VERSION "eCMP INFO-DIV vehicle review 2026-11-03; 125000 bit/s; PSA-RE 67f7581e7622410efdbb29c7eda3b86982b9b450; Apache-2.0"

NS_ :

BS_:

BU_: AAS AMPLI AVP BCM BGP BSG BSI BTA BTEL BTT CDC CMB CRT DIAG_TOOL EDP_C EMF FMUX IC ICSV IDVR IVC_D MATT MDS OVIP PDS_C RAD RBG SDCM VTH WLC

BO_ 603 BTEL_ClimatePrecondSched: 7 BTEL
 SG_ ClimatePrecondSlot2StartTime : 42|11@0+ (1,0) [0|1440] "min"  BSI
 SG_ Unused3 : 47|5@0+ (1,0) [0|31] ""  BSI
 SG_ ClimatePrecondSundaySlot2Enabled : 32|1@0+ (1,0) [0|1] ""  BSI
 SG_ ClimatePrecondSaturdaySlo_fd2bfe : 33|1@0+ (1,0) [0|1] ""  BSI
 SG_ ClimatePrecondFridaySlot2Enabled : 34|1@0+ (1,0) [0|1] ""  BSI
 SG_ ClimatePrecondThursdaySlo_8ba9ec : 35|1@0+ (1,0) [0|1] ""  BSI
 SG_ ClimatePrecondWednesdaySl_20214f : 36|1@0+ (1,0) [0|1] ""  BSI
 SG_ ClimatePrecondTuesdaySlot_413385 : 37|1@0+ (1,0) [0|1] ""  BSI
 SG_ ClimatePrecondMondaySlot2Enabled : 38|1@0+ (1,0) [0|1] ""  BSI
 SG_ ClimatePrecondSlot2Enabled : 39|1@0+ (1,0) [0|1] ""  BSI
 SG_ ClimatePrecondSlot1StartTime : 18|11@0+ (1,0) [0|1440] "min"  BSI
 SG_ Unused2 : 23|5@0+ (1,0) [0|31] ""  BSI
 SG_ ClimatePrecondSundaySlot1Enabled : 8|1@0+ (1,0) [0|1] ""  BSI
 SG_ ClimatePrecondSaturdaySlo_c187b9 : 9|1@0+ (1,0) [0|1] ""  BSI
 SG_ ClimatePrecondFridaySlot1Enabled : 10|1@0+ (1,0) [0|1] ""  BSI
 SG_ ClimatePrecondThursdaySlo_13efd6 : 11|1@0+ (1,0) [0|1] ""  BSI
 SG_ ClimatePrecondWednesdaySl_d65ca4 : 12|1@0+ (1,0) [0|1] ""  BSI
 SG_ ClimatePrecondTuesdaySlot_1bddd8 : 13|1@0+ (1,0) [0|1] ""  BSI
 SG_ ClimatePrecondMondaySlot1Enabled : 14|1@0+ (1,0) [0|1] ""  BSI
 SG_ ClimatePrecondSlot1Enabled : 15|1@0+ (1,0) [0|1] ""  BSI
 SG_ Unused1 : 6|7@0+ (1,0) [0|127] ""  BSI
 SG_ ClimatePrecondMenuAvailability : 7|1@0+ (1,0) [0|1] ""  BSI

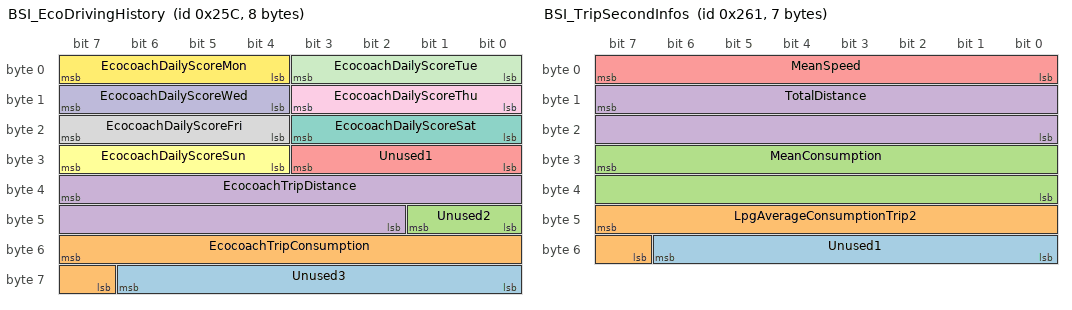
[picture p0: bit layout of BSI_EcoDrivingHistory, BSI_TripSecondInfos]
BO_ 604 BSI_EcoDrivingHistory: 8 BSI
 SG_ Unused3 : 62|7@0+ (1,0) [0|127] ""  OVIP,BTEL
 SG_ EcocoachTripConsumption : 55|9@0+ (0.1,0) [0|30] "L"  OVIP,BTEL
 SG_ Unused2 : 41|2@0+ (1,0) [0|3] ""  OVIP,BTEL
 SG_ EcocoachTripDistance : 39|14@0+ (1,0) [0|16383] "km"  OVIP,BTEL
 SG_ Unused1 : 27|4@0+ (1,0) [0|15] ""  OVIP,BTEL
 SG_ EcocoachDailyScoreSun : 31|4@0+ (1,0) [0|10] ""  OVIP,BTEL
 SG_ EcocoachDailyScoreSat : 19|4@0+ (1,0) [0|10] ""  OVIP,BTEL
 SG_ EcocoachDailyScoreFri : 23|4@0+ (1,0) [0|10] ""  OVIP,BTEL
 SG_ EcocoachDailyScoreThu : 11|4@0+ (1,0) [0|10] ""  OVIP,BTEL
 SG_ EcocoachDailyScoreWed : 15|4@0+ (1,0) [0|10] ""  OVIP,BTEL
 SG_ EcocoachDailyScoreTue : 3|4@0+ (1,0) [0|10] ""  OVIP,BTEL
 SG_ EcocoachDailyScoreMon : 7|4@0+ (1,0) [0|10] ""  OVIP,BTEL

BO_ 607 EMF_KmlReplyFlowControl: 8 EMF
 SG_ FlowPadding5 m3 : 63|8@0+ (1,0) [0|255] "raw"  RAD
 SG_ FirstData6 m1 : 63|8@0+ (1,0) [0|255] "raw"  RAD
 SG_ UnknownData7 m4 : 63|8@0+ (1,0) [0|255] "raw"  RAD
 SG_ ConsecutiveData7 m2 : 63|8@0+ (1,0) [0|255] "raw"  RAD
 SG_ SingleData7 m0 : 63|8@0+ (1,0) [0|255] "raw"  RAD
 SG_ FlowPadding4 m3 : 55|8@0+ (1,0) [0|255] "raw"  RAD
 SG_ FirstData5 m1 : 55|8@0+ (1,0) [0|255] "raw"  RAD
 SG_ UnknownData6 m4 : 55|8@0+ (1,0) [0|255] "raw"  RAD
 SG_ ConsecutiveData6 m2 : 55|8@0+ (1,0) [0|255] "raw"  RAD
 SG_ SingleData6 m0 : 55|8@0+ (1,0) [0|255] "raw"  RAD
 SG_ FlowPadding3 m3 : 47|8@0+ (1,0) [0|255] "raw"  RAD
 SG_ FirstData4 m1 : 47|8@0+ (1,0) [0|255] "raw"  RAD
 SG_ UnknownData5 m4 : 47|8@0+ (1,0) [0|255] "raw"  RAD
 SG_ ConsecutiveData5 m2 : 47|8@0+ (1,0) [0|255] "raw"  RAD
 SG_ SingleData5 m0 : 47|8@0+ (1,0) [0|255] "raw"  RAD
 SG_ FlowPadding2 m3 : 39|8@0+ (1,0) [0|255] "raw"  RAD
 SG_ FirstData3 m1 : 39|8@0+ (1,0) [0|255] "raw"  RAD
 SG_ UnknownData4 m4 : 39|8@0+ (1,0) [0|255] "raw"  RAD
 SG_ ConsecutiveData4 m2 : 39|8@0+ (1,0) [0|255] "raw"  RAD
 SG_ SingleData4 m0 : 39|8@0+ (1,0) [0|255] "raw"  RAD
 SG_ FlowPadding1 m3 : 31|8@0+ (1,0) [0|255] "raw"  RAD
 SG_ FirstData2 m1 : 31|8@0+ (1,0) [0|255] "raw"  RAD
 SG_ UnknownData3 m4 : 31|8@0+ (1,0) [0|255] "raw"  RAD
 SG_ ConsecutiveData3 m2 : 31|8@0+ (1,0) [0|255] "raw"  RAD
 SG_ SingleData3 m0 : 31|8@0+ (1,0) [0|255] "raw"  RAD
 SG_ FirstData1 m1 : 23|8@0+ (1,0) [0|255] "raw"  RAD
 SG_ UnknownData2 m4 : 23|8@0+ (1,0) [0|255] "raw"  RAD
 SG_ ConsecutiveData2 m2 : 23|8@0+ (1,0) [0|255] "raw"  RAD
 SG_ SingleData2 m0 : 23|8@0+ (1,0) [0|255] "raw"  RAD
 SG_ SeparationTimeRaw m3 : 23|8@0+ (1,0) [0|255] "raw"  RAD
 SG_ UnknownData1 m4 : 15|8@0+ (1,0) [0|255] "raw"  RAD
 SG_ ConsecutiveData1 m2 : 15|8@0+ (1,0) [0|255] "raw"  RAD
 SG_ SingleData1 m0 : 15|8@0+ (1,0) [0|255] "raw"  RAD
 SG_ BlockSize m3 : 15|8@0+ (1,0) [0|255] "raw"  RAD
 SG_ UnknownPciLow m4 : 3|4@0+ (1,0) [0|15] "raw"  RAD
 SG_ FlowStatus m3 : 3|4@0+ (1,0) [0|15] "raw"  RAD
 SG_ ConsecutiveSequence m2 : 3|4@0+ (1,0) [0|15] "raw"  RAD
 SG_ FirstFrameLength m1 : 3|12@0+ (1,0) [0|4095] "raw"  RAD
 SG_ SingleFrameLength m0 : 3|4@0+ (1,0) [0|15] "raw"  RAD
 SG_ IsoTpFrameType M : 7|4@0+ (1,0) [0|15] ""  RAD

BO_ 608 BSI_VehiclePersonalizatio_19d41f: 8 BSI
 SG_ AmlaItemStatus : 56|1@0+ (1,0) [0|1] ""  IDVR,EMF,BTEL,MATT,MDS,CMB,VTH,RAD,ICSV,BGP,FMUX,OVIP
 SG_ AfsFunctionActive : 57|1@0+ (1,0) [0|1] ""  IDVR,EMF,BTEL,MATT,MDS,CMB,VTH,RAD,ICSV,BGP,FMUX,OVIP
 SG_ ArsFunctionActive : 58|1@0+ (1,0) [0|1] ""  IDVR,EMF,BTEL,MATT,MDS,CMB,VTH,RAD,ICSV,BGP,FMUX,OVIP
 SG_ IrvFunctionInhibited : 59|1@0+ (1,0) [0|1] ""  IDVR,EMF,BTEL,MATT,MDS,CMB,VTH,RAD,ICSV,BGP,FMUX,OVIP
 SG_ Dae4wdItemModeStatus : 61|2@0+ (1,0) [0|3] ""  IDVR,EMF,BTEL,MATT,MDS,CMB,VTH,RAD,ICSV,BGP,FMUX,OVIP
 SG_ DaeItemModeStatus : 63|2@0+ (1,0) [0|3] ""  IDVR,EMF,BTEL,MATT,MDS,CMB,VTH,RAD,ICSV,BGP,FMUX,OVIP
 SG_ LoadedArmsAccessFunctionActive : 48|1@0+ (1,0) [0|1] ""  IDVR,EMF,BTEL,MATT,MDS,CMB,VTH,RAD,ICSV,BGP,FMUX,OVIP
 SG_ IlvItemStatus : 49|1@0+ (1,0) [0|1] ""  IDVR,EMF,BTEL,MATT,MDS,CMB,VTH,RAD,ICSV,BGP,FMUX,OVIP
 SG_ GrilleLightingFunctionStatus : 50|1@0+ (1,0) [0|1] ""  IDVR,EMF,BTEL,MATT,MDS,CMB,VTH,RAD,ICSV,BGP,FMUX,OVIP
 SG_ CafrItemStatus : 51|1@0+ (1,0) [0|1] ""  IDVR,EMF,BTEL,MATT,MDS,CMB,VTH,RAD,ICSV,BGP,FMUX,OVIP
 SG_ DriverAlertAssistFunctionActive : 52|1@0+ (1,0) [0|1] ""  IDVR,EMF,BTEL,MATT,MDS,CMB,VTH,RAD,ICSV,BGP,FMUX,OVIP
 SG_ LoadedArmsLockFunctionActive : 53|1@0+ (1,0) [0|1] ""  IDVR,EMF,BTEL,MATT,MDS,CMB,VTH,RAD,ICSV,BGP,FMUX,OVIP
 SG_ EtsrFunctionActive : 54|1@0+ (1,0) [0|1] ""  IDVR,EMF,BTEL,MATT,MDS,CMB,VTH,RAD,ICSV,BGP,FMUX,OVIP
 SG_ EcsModeFunctionActive : 55|1@0+ (1,0) [0|1] ""  IDVR,EMF,BTEL,MATT,MDS,CMB,VTH,RAD,ICSV,BGP,FMUX,OVIP
 SG_ ActiveUserProfile : 41|2@0+ (1,0) [0|3] ""  IDVR,EMF,BTEL,MATT,MDS,CMB,VTH,RAD,ICSV,BGP,FMUX,OVIP
 SG_ ReverseIndexingStatus : 42|1@0+ (1,0) [0|1] ""  IDVR,EMF,BTEL,MATT,MDS,CMB,VTH,RAD,ICSV,BGP,FMUX,OVIP
 SG_ TpmsReinitializationStatus : 43|1@0+ (1,0) [0|1] ""  IDVR,EMF,BTEL,MATT,MDS,CMB,VTH,RAD,ICSV,BGP,FMUX,OVIP
 SG_ CollisionRiskBrakingType : 44|1@0+ (1,0) [0|1] ""  IDVR,EMF,BTEL,MATT,MDS,CMB,VTH,RAD,ICSV,BGP,FMUX,OVIP
 SG_ ArcSensitivityLevel : 46|2@0+ (1,0) [0|3] ""  IDVR,EMF,BTEL,MATT,MDS,CMB,VTH,RAD,ICSV,BGP,FMUX,OVIP
 SG_ ArcFunctionActive : 47|1@0+ (1,0) [0|1] ""  IDVR,EMF,BTEL,MATT,MDS,CMB,VTH,RAD,ICSV,BGP,FMUX,OVIP
 SG_ ConfigurableButtonFunction : 35|4@0+ (1,0) [0|15] ""  IDVR,EMF,BTEL,MATT,MDS,CMB,VTH,RAD,ICSV,BGP,FMUX,OVIP
 SG_ RearFlapMotorizationFunct_177f8c : 36|1@0+ (1,0) [0|1] ""  IDVR,EMF,BTEL,MATT,MDS,CMB,VTH,RAD,ICSV,BGP,FMUX,OVIP
 SG_ AutomaticRearWiperInReverse : 37|1@0+ (1,0) [0|1] ""  IDVR,EMF,BTEL,MATT,MDS,CMB,VTH,RAD,ICSV,BGP,FMUX,OVIP
 SG_ BlindSpotMonitoringFeedbackType : 38|1@0+ (1,0) [0|1] ""  IDVR,EMF,BTEL,MATT,MDS,CMB,VTH,RAD,ICSV,BGP,FMUX,OVIP
 SG_ ParkingAidSetup : 39|1@0+ (1,0) [0|1] ""  IDVR,EMF,BTEL,MATT,MDS,CMB,VTH,RAD,ICSV,BGP,FMUX,OVIP
 SG_ AutomaticHeadlightsSwitchingOn : 24|1@0+ (1,0) [0|1] ""  IDVR,EMF,BTEL,MATT,MDS,CMB,VTH,RAD,ICSV,BGP,FMUX,OVIP
 SG_ UnlockingLightingDuration : 26|2@0+ (1,0) [0|3] ""  IDVR,EMF,BTEL,MATT,MDS,CMB,VTH,RAD,ICSV,BGP,FMUX,OVIP
 SG_ UnlockingLightingFunction : 27|1@0+ (1,0) [0|1] ""  IDVR,EMF,BTEL,MATT,MDS,CMB,VTH,RAD,ICSV,BGP,FMUX,OVIP
 SG_ MotorwayLightingFunction : 28|1@0+ (1,0) [0|1] ""  IDVR,EMF,BTEL,MATT,MDS,CMB,VTH,RAD,ICSV,BGP,FMUX,OVIP
 SG_ FollowMeHomeDuration : 30|2@0+ (1,0) [0|3] ""  IDVR,EMF,BTEL,MATT,MDS,CMB,VTH,RAD,ICSV,BGP,FMUX,OVIP
 SG_ FollowMeHome : 31|1@0+ (1,0) [0|1] ""  IDVR,EMF,BTEL,MATT,MDS,CMB,VTH,RAD,ICSV,BGP,FMUX,OVIP
 SG_ AmbientLighting : 16|1@0+ (1,0) [0|1] ""  IDVR,EMF,BTEL,MATT,MDS,CMB,VTH,RAD,ICSV,BGP,FMUX,OVIP
 SG_ DlrFunction : 17|1@0+ (1,0) [0|1] ""  IDVR,EMF,BTEL,MATT,MDS,CMB,VTH,RAD,ICSV,BGP,FMUX,OVIP
 SG_ AdaptiveLighting : 18|1@0+ (1,0) [0|1] ""  IDVR,EMF,BTEL,MATT,MDS,CMB,VTH,RAD,ICSV,BGP,FMUX,OVIP
 SG_ DriverGreeting : 19|1@0+ (1,0) [0|1] ""  IDVR,EMF,BTEL,MATT,MDS,CMB,VTH,RAD,ICSV,BGP,FMUX,OVIP
 SG_ RearOpeningsSelectivityStatus : 20|1@0+ (1,0) [0|1] ""  IDVR,EMF,BTEL,MATT,MDS,CMB,VTH,RAD,ICSV,BGP,FMUX,OVIP
 SG_ CabOpeningsSelectivityFun_dd2313 : 21|1@0+ (1,0) [0|1] ""  IDVR,EMF,BTEL,MATT,MDS,CMB,VTH,RAD,ICSV,BGP,FMUX,OVIP
 SG_ DoorUnlockingModeOnKey : 22|1@0+ (1,0) [0|1] ""  IDVR,EMF,BTEL,MATT,MDS,CMB,VTH,RAD,ICSV,BGP,FMUX,OVIP
 SG_ AutomaticElectricParkingB_11b15b : 23|1@0+ (1,0) [0|1] ""  IDVR,EMF,BTEL,MATT,MDS,CMB,VTH,RAD,ICSV,BGP,FMUX,OVIP
 SG_ VehicleSoundHarmony : 9|2@0+ (1,0) [0|3] ""  IDVR,EMF,BTEL,MATT,MDS,CMB,VTH,RAD,ICSV,BGP,FMUX,OVIP
 SG_ VehicleConfigurationDataValid : 10|1@0+ (1,0) [0|1] ""  IDVR,EMF,BTEL,MATT,MDS,CMB,VTH,RAD,ICSV,BGP,FMUX,OVIP
 SG_ AmbientLightingLevel : 13|3@0+ (1,0) [0|7] ""  IDVR,EMF,BTEL,MATT,MDS,CMB,VTH,RAD,ICSV,BGP,FMUX,OVIP
 SG_ TemperatureUnit : 14|1@0+ (1,0) [0|1] ""  IDVR,EMF,BTEL,MATT,MDS,CMB,VTH,RAD,ICSV,BGP,FMUX,OVIP
 SG_ ConfigVolumeUnit : 15|1@0+ (1,0) [0|1] ""  IDVR,EMF,BTEL,MATT,MDS,CMB,VTH,RAD,ICSV,BGP,FMUX,OVIP
 SG_ ConfigConsumptionUnit : 0|1@0+ (1,0) [0|1] ""  IDVR,EMF,BTEL,MATT,MDS,CMB,VTH,RAD,ICSV,BGP,FMUX,OVIP
 SG_ DistanceUnit : 1|1@0+ (1,0) [0|1] ""  IDVR,EMF,BTEL,MATT,MDS,CMB,VTH,RAD,ICSV,BGP,FMUX,OVIP
 SG_ VehicleLanguage : 6|5@0+ (1,0) [0|31] ""  IDVR,EMF,BTEL,MATT,MDS,CMB,VTH,RAD,ICSV,BGP,FMUX,OVIP
 SG_ UnitLanguageDataValidity : 7|1@0+ (1,0) [0|1] ""  IDVR,EMF,BTEL,MATT,MDS,CMB,VTH,RAD,ICSV,BGP,FMUX,OVIP

BO_ 609 BSI_TripSecondInfos: 7 BSI
 SG_ Unused1 : 54|7@0+ (1,0) [0|127] ""  EMF,CMB,BTEL,MATT,BGP,OVIP,RAD
 SG_ LpgAverageConsumptionTrip2 : 47|9@0+ (0.1,0) [0|30] "L/100km"  EMF,CMB,BTEL,MATT,BGP,OVIP,RAD
 SG_ MeanConsumption : 31|16@0+ (0.1,0) [0|30] "L/100km"  EMF,CMB,BTEL,MATT,BGP,OVIP,RAD
 SG_ TotalDistance : 15|16@0+ (1,0) [0|50000] "km"  EMF,CMB,BTEL,MATT,BGP,OVIP,RAD
 SG_ MeanSpeed : 7|8@0+ (1,0) [0|250] "km/h"  EMF,CMB,BTEL,MATT,BGP,OVIP,RAD

BO_ 611 RAD_EmfTelephoneReplyFlowControl: 8 RAD
 SG_ FlowPadding5 m3 : 63|8@0+ (1,0) [0|255] "raw"  EMF
 SG_ FirstData6 m1 : 63|8@0+ (1,0) [0|255] "raw"  EMF
 SG_ UnknownData7 m4 : 63|8@0+ (1,0) [0|255] "raw"  EMF
 SG_ ConsecutiveData7 m2 : 63|8@0+ (1,0) [0|255] "raw"  EMF
 SG_ SingleData7 m0 : 63|8@0+ (1,0) [0|255] "raw"  EMF
 SG_ FlowPadding4 m3 : 55|8@0+ (1,0) [0|255] "raw"  EMF
 SG_ FirstData5 m1 : 55|8@0+ (1,0) [0|255] "raw"  EMF
 SG_ UnknownData6 m4 : 55|8@0+ (1,0) [0|255] "raw"  EMF
 SG_ ConsecutiveData6 m2 : 55|8@0+ (1,0) [0|255] "raw"  EMF
 SG_ SingleData6 m0 : 55|8@0+ (1,0) [0|255] "raw"  EMF
 SG_ FlowPadding3 m3 : 47|8@0+ (1,0) [0|255] "raw"  EMF
 SG_ FirstData4 m1 : 47|8@0+ (1,0) [0|255] "raw"  EMF
 SG_ UnknownData5 m4 : 47|8@0+ (1,0) [0|255] "raw"  EMF
 SG_ ConsecutiveData5 m2 : 47|8@0+ (1,0) [0|255] "raw"  EMF
 SG_ SingleData5 m0 : 47|8@0+ (1,0) [0|255] "raw"  EMF
 SG_ FlowPadding2 m3 : 39|8@0+ (1,0) [0|255] "raw"  EMF
 SG_ FirstData3 m1 : 39|8@0+ (1,0) [0|255] "raw"  EMF
 SG_ UnknownData4 m4 : 39|8@0+ (1,0) [0|255] "raw"  EMF
 SG_ ConsecutiveData4 m2 : 39|8@0+ (1,0) [0|255] "raw"  EMF
 SG_ SingleData4 m0 : 39|8@0+ (1,0) [0|255] "raw"  EMF
 SG_ FlowPadding1 m3 : 31|8@0+ (1,0) [0|255] "raw"  EMF
 SG_ FirstData2 m1 : 31|8@0+ (1,0) [0|255] "raw"  EMF
 SG_ UnknownData3 m4 : 31|8@0+ (1,0) [0|255] "raw"  EMF
 SG_ ConsecutiveData3 m2 : 31|8@0+ (1,0) [0|255] "raw"  EMF
 SG_ SingleData3 m0 : 31|8@0+ (1,0) [0|255] "raw"  EMF
 SG_ FirstData1 m1 : 23|8@0+ (1,0) [0|255] "raw"  EMF
 SG_ UnknownData2 m4 : 23|8@0+ (1,0) [0|255] "raw"  EMF
 SG_ ConsecutiveData2 m2 : 23|8@0+ (1,0) [0|255] "raw"  EMF
 SG_ SingleData2 m0 : 23|8@0+ (1,0) [0|255] "raw"  EMF
 SG_ SeparationTimeRaw m3 : 23|8@0+ (1,0) [0|255] "raw"  EMF
 SG_ UnknownData1 m4 : 15|8@0+ (1,0) [0|255] "raw"  EMF
 SG_ ConsecutiveData1 m2 : 15|8@0+ (1,0) [0|255] "raw"  EMF
 SG_ SingleData1 m0 : 15|8@0+ (1,0) [0|255] "raw"  EMF
 SG_ BlockSize m3 : 15|8@0+ (1,0) [0|255] "raw"  EMF
 SG_ UnknownPciLow m4 : 3|4@0+ (1,0) [0|15] "raw"  EMF
 SG_ FlowStatus m3 : 3|4@0+ (1,0) [0|15] "raw"  EMF
 SG_ ConsecutiveSequence m2 : 3|4@0+ (1,0) [0|15] "raw"  EMF
 SG_ FirstFrameLength m1 : 3|12@0+ (1,0) [0|4095] "raw"  EMF
 SG_ SingleFrameLength m0 : 3|4@0+ (1,0) [0|15] "raw"  EMF
 SG_ IsoTpFrameType M : 7|4@0+ (1,0) [0|15] ""  EMF

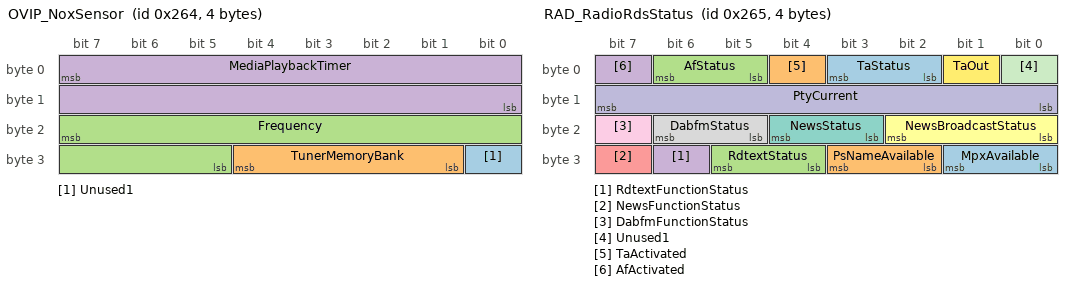
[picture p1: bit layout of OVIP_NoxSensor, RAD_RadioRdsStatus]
BO_ 612 OVIP_NoxSensor: 4 OVIP
 SG_ Unused1 : 24|1@0+ (1,0) [0|1] ""  CMB
 SG_ TunerMemoryBank : 28|4@0+ (1,0) [0|15] ""  CMB
 SG_ Frequency : 23|11@0+ (1,0) [0|2045] "frequency step"  CMB
 SG_ MediaPlaybackTimer : 7|16@0+ (1,0) [0|65500] "s"  CMB

BO_ 613 RAD_RadioRdsStatus: 4 RAD
 SG_ MpxAvailable : 25|2@0+ (1,0) [0|3] ""  EMF
 SG_ PsNameAvailable : 27|2@0+ (1,0) [0|3] ""  EMF
 SG_ RdtextStatus : 29|2@0+ (1,0) [0|3] ""  EMF
 SG_ RdtextFunctionStatus : 30|1@0+ (1,0) [0|1] ""  EMF
 SG_ NewsFunctionStatus : 31|1@0+ (1,0) [0|1] ""  EMF
 SG_ NewsBroadcastStatus : 18|3@0+ (1,0) [0|7] ""  EMF
 SG_ NewsStatus : 20|2@0+ (1,0) [0|3] ""  EMF
 SG_ DabfmStatus : 22|2@0+ (1,0) [0|3] ""  EMF
 SG_ DabfmFunctionStatus : 23|1@0+ (1,0) [0|1] ""  EMF
 SG_ PtyCurrent : 15|8@0+ (1,0) [0|255] ""  EMF
 SG_ Unused1 : 0|1@0+ (1,0) [0|1] ""  EMF
 SG_ TaOut : 1|1@0+ (1,0) [0|1] ""  EMF
 SG_ TaStatus : 3|2@0+ (1,0) [0|3] ""  EMF
 SG_ TaActivated : 4|1@0+ (1,0) [0|1] ""  EMF
 SG_ AfStatus : 6|2@0+ (1,0) [0|3] ""  EMF
 SG_ AfActivated : 7|1@0+ (1,0) [0|1] ""  EMF

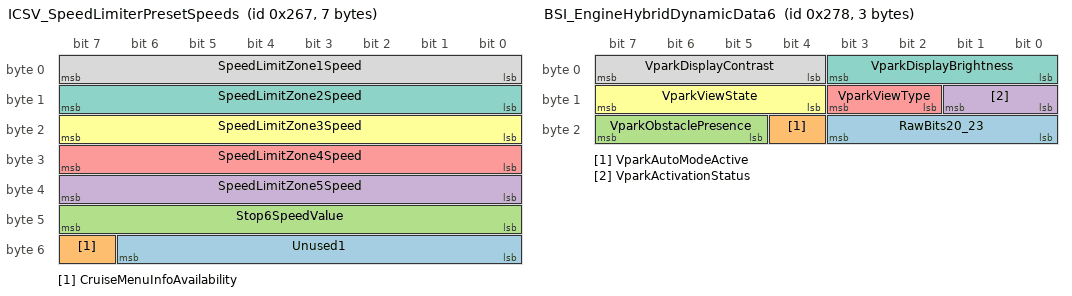
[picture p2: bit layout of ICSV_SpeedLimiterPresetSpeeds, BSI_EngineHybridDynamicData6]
BO_ 615 ICSV_SpeedLimiterPresetSpeeds: 7 ICSV
 SG_ Unused1 : 54|7@0+ (1,0) [0|127] ""  CMB,BTEL,OVIP,MATT,RAD
 SG_ CruiseMenuInfoAvailability : 55|1@0+ (1,0) [0|1] ""  CMB,BTEL,OVIP,MATT,RAD
 SG_ Stop6SpeedValue : 47|8@0+ (1,0) [0|253] "km/h"  CMB,BTEL,OVIP,MATT,RAD
 SG_ SpeedLimitZone5Speed : 39|8@0+ (1,0) [0|254] "km/h"  CMB,BTEL,OVIP,MATT,RAD
 SG_ SpeedLimitZone4Speed : 31|8@0+ (1,0) [0|254] "km/h"  CMB,BTEL,OVIP,MATT,RAD
 SG_ SpeedLimitZone3Speed : 23|8@0+ (1,0) [0|254] "km/h"  CMB,BTEL,OVIP,MATT,RAD
 SG_ SpeedLimitZone2Speed : 15|8@0+ (1,0) [0|254] "km/h"  CMB,BTEL,OVIP,MATT,RAD
 SG_ SpeedLimitZone1Speed : 7|8@0+ (1,0) [0|254] "km/h"  CMB,BTEL,OVIP,MATT,RAD

BO_ 616 BSI_EngineDynamicData: 8 BSI
 SG_ AuthenticationHmiDisplayRequest : 56|1@0+ (1,0) [0|1] ""  BTEL,VTH,CMB,MATT,MDS,OVIP,FMUX,RAD
 SG_ ManualModeSelectionState : 57|1@0+ (1,0) [0|1] ""  BTEL,VTH,CMB,MATT,MDS,OVIP,FMUX,RAD
 SG_ VehicleModeSelectorCommand : 59|2@0+ (1,0) [0|3] ""  BTEL,VTH,CMB,MATT,MDS,OVIP,FMUX,RAD
 SG_ CurrentVehicleMode : 63|4@0+ (1,0) [0|15] ""  BTEL,VTH,CMB,MATT,MDS,OVIP,FMUX,RAD
 SG_ VehicleModeSelectorConfiguration : 51|4@0+ (1,0) [0|15] ""  BTEL,VTH,CMB,MATT,MDS,OVIP,FMUX,RAD
 SG_ DriverMassageStatus : 53|2@0+ (1,0) [0|3] ""  BTEL,VTH,CMB,MATT,MDS,OVIP,FMUX,RAD
 SG_ PassengerMassageStatus : 55|2@0+ (1,0) [0|3] ""  BTEL,VTH,CMB,MATT,MDS,OVIP,FMUX,RAD
 SG_ SmartDeviceNotification : 40|1@0+ (1,0) [0|1] ""  BTEL,VTH,CMB,MATT,MDS,OVIP,FMUX,RAD
 SG_ AsrConnectionStatus : 42|2@0+ (1,0) [0|3] ""  BTEL,VTH,CMB,MATT,MDS,OVIP,FMUX,RAD
 SG_ AdblueMaxRefillVolume : 47|5@0+ (1,0) [0|30] "L"  BTEL,VTH,CMB,MATT,MDS,OVIP,FMUX,RAD
 SG_ DynamicModeHmiFeedback : 33|2@0+ (1,0) [0|3] ""  BTEL,VTH,CMB,MATT,MDS,OVIP,FMUX,RAD
 SG_ UreaTankLevel : 38|5@0+ (5,0) [0|100] "%"  BTEL,VTH,CMB,MATT,MDS,OVIP,FMUX,RAD
 SG_ DynamicSettingType : 39|1@0+ (1,0) [0|1] ""  BTEL,VTH,CMB,MATT,MDS,OVIP,FMUX,RAD
 SG_ DynamicModeSelectedSynthesis : 25|2@0+ (1,0) [0|3] ""  BTEL,VTH,CMB,MATT,MDS,OVIP,FMUX,RAD
 SG_ DriverMassageButtonStatus : 26|1@0+ (1,0) [0|1] ""  BTEL,VTH,CMB,MATT,MDS,OVIP,FMUX,RAD
 SG_ PassengerMassageButtonStatus : 27|1@0+ (1,0) [0|1] ""  BTEL,VTH,CMB,MATT,MDS,OVIP,FMUX,RAD
 SG_ DriverMassageIntensityStatus : 29|2@0+ (1,0) [0|3] ""  BTEL,VTH,CMB,MATT,MDS,OVIP,FMUX,RAD
 SG_ PassengerMassageIntensityStatus : 31|2@0+ (1,0) [0|3] ""  BTEL,VTH,CMB,MATT,MDS,OVIP,FMUX,RAD
 SG_ DriverMassageTypeStatus : 19|4@0+ (1,0) [0|15] ""  BTEL,VTH,CMB,MATT,MDS,OVIP,FMUX,RAD
 SG_ PassengerMassageTypeStatus : 23|4@0+ (1,0) [0|15] ""  BTEL,VTH,CMB,MATT,MDS,OVIP,FMUX,RAD
 SG_ VehiclePoiDisplayRequest : 11|4@0+ (1,0) [0|15] ""  BTEL,VTH,CMB,MATT,MDS,OVIP,FMUX,RAD
 SG_ IlvSpeedRobustFlag : 12|1@0+ (1,0) [0|1] ""  BTEL,VTH,CMB,MATT,MDS,OVIP,FMUX,RAD
 SG_ IlvOverspeedFlag : 13|1@0+ (1,0) [0|1] ""  BTEL,VTH,CMB,MATT,MDS,OVIP,FMUX,RAD
 SG_ IlvSignType : 15|2@0+ (1,0) [0|3] ""  BTEL,VTH,CMB,MATT,MDS,OVIP,FMUX,RAD
 SG_ IlvSpeedToDisplay : 7|8@0+ (1,0) [0|253] "km/h"  BTEL,VTH,CMB,MATT,MDS,OVIP,FMUX,RAD

BO_ 617 MATT_NavExportFlowControl2: 8 MATT
 SG_ FlowPadding5 m3 : 63|8@0+ (1,0) [0|255] "raw"  BTEL,OVIP
 SG_ FirstData6 m1 : 63|8@0+ (1,0) [0|255] "raw"  BTEL,OVIP
 SG_ UnknownData7 m4 : 63|8@0+ (1,0) [0|255] "raw"  BTEL,OVIP
 SG_ ConsecutiveData7 m2 : 63|8@0+ (1,0) [0|255] "raw"  BTEL,OVIP
 SG_ SingleData7 m0 : 63|8@0+ (1,0) [0|255] "raw"  BTEL,OVIP
 SG_ FlowPadding4 m3 : 55|8@0+ (1,0) [0|255] "raw"  BTEL,OVIP
 SG_ FirstData5 m1 : 55|8@0+ (1,0) [0|255] "raw"  BTEL,OVIP
 SG_ UnknownData6 m4 : 55|8@0+ (1,0) [0|255] "raw"  BTEL,OVIP
 SG_ ConsecutiveData6 m2 : 55|8@0+ (1,0) [0|255] "raw"  BTEL,OVIP
 SG_ SingleData6 m0 : 55|8@0+ (1,0) [0|255] "raw"  BTEL,OVIP
 SG_ FlowPadding3 m3 : 47|8@0+ (1,0) [0|255] "raw"  BTEL,OVIP
 SG_ FirstData4 m1 : 47|8@0+ (1,0) [0|255] "raw"  BTEL,OVIP
 SG_ UnknownData5 m4 : 47|8@0+ (1,0) [0|255] "raw"  BTEL,OVIP
 SG_ ConsecutiveData5 m2 : 47|8@0+ (1,0) [0|255] "raw"  BTEL,OVIP
 SG_ SingleData5 m0 : 47|8@0+ (1,0) [0|255] "raw"  BTEL,OVIP
 SG_ FlowPadding2 m3 : 39|8@0+ (1,0) [0|255] "raw"  BTEL,OVIP
 SG_ FirstData3 m1 : 39|8@0+ (1,0) [0|255] "raw"  BTEL,OVIP
 SG_ UnknownData4 m4 : 39|8@0+ (1,0) [0|255] "raw"  BTEL,OVIP
 SG_ ConsecutiveData4 m2 : 39|8@0+ (1,0) [0|255] "raw"  BTEL,OVIP
 SG_ SingleData4 m0 : 39|8@0+ (1,0) [0|255] "raw"  BTEL,OVIP
 SG_ FlowPadding1 m3 : 31|8@0+ (1,0) [0|255] "raw"  BTEL,OVIP
 SG_ FirstData2 m1 : 31|8@0+ (1,0) [0|255] "raw"  BTEL,OVIP
 SG_ UnknownData3 m4 : 31|8@0+ (1,0) [0|255] "raw"  BTEL,OVIP
 SG_ ConsecutiveData3 m2 : 31|8@0+ (1,0) [0|255] "raw"  BTEL,OVIP
 SG_ SingleData3 m0 : 31|8@0+ (1,0) [0|255] "raw"  BTEL,OVIP
 SG_ FirstData1 m1 : 23|8@0+ (1,0) [0|255] "raw"  BTEL,OVIP
 SG_ UnknownData2 m4 : 23|8@0+ (1,0) [0|255] "raw"  BTEL,OVIP
 SG_ ConsecutiveData2 m2 : 23|8@0+ (1,0) [0|255] "raw"  BTEL,OVIP
 SG_ SingleData2 m0 : 23|8@0+ (1,0) [0|255] "raw"  BTEL,OVIP
 SG_ SeparationTimeRaw m3 : 23|8@0+ (1,0) [0|255] "raw"  BTEL,OVIP
 SG_ UnknownData1 m4 : 15|8@0+ (1,0) [0|255] "raw"  BTEL,OVIP
 SG_ ConsecutiveData1 m2 : 15|8@0+ (1,0) [0|255] "raw"  BTEL,OVIP
 SG_ SingleData1 m0 : 15|8@0+ (1,0) [0|255] "raw"  BTEL,OVIP
 SG_ BlockSize m3 : 15|8@0+ (1,0) [0|255] "raw"  BTEL,OVIP
 SG_ UnknownPciLow m4 : 3|4@0+ (1,0) [0|15] "raw"  BTEL,OVIP
 SG_ FlowStatus m3 : 3|4@0+ (1,0) [0|15] "raw"  BTEL,OVIP
 SG_ ConsecutiveSequence m2 : 3|4@0+ (1,0) [0|15] "raw"  BTEL,OVIP
 SG_ FirstFrameLength m1 : 3|12@0+ (1,0) [0|4095] "raw"  BTEL,OVIP
 SG_ SingleFrameLength m0 : 3|4@0+ (1,0) [0|15] "raw"  BTEL,OVIP
 SG_ IsoTpFrameType M : 7|4@0+ (1,0) [0|15] ""  BTEL,OVIP

BO_ 625 RAD_CdChangerReplyFlowControl: 8 RAD
 SG_ FlowPadding5 m3 : 63|8@0+ (1,0) [0|255] "raw"  CDC
 SG_ FirstData6 m1 : 63|8@0+ (1,0) [0|255] "raw"  CDC
 SG_ UnknownData7 m4 : 63|8@0+ (1,0) [0|255] "raw"  CDC
 SG_ ConsecutiveData7 m2 : 63|8@0+ (1,0) [0|255] "raw"  CDC
 SG_ SingleData7 m0 : 63|8@0+ (1,0) [0|255] "raw"  CDC
 SG_ FlowPadding4 m3 : 55|8@0+ (1,0) [0|255] "raw"  CDC
 SG_ FirstData5 m1 : 55|8@0+ (1,0) [0|255] "raw"  CDC
 SG_ UnknownData6 m4 : 55|8@0+ (1,0) [0|255] "raw"  CDC
 SG_ ConsecutiveData6 m2 : 55|8@0+ (1,0) [0|255] "raw"  CDC
 SG_ SingleData6 m0 : 55|8@0+ (1,0) [0|255] "raw"  CDC
 SG_ FlowPadding3 m3 : 47|8@0+ (1,0) [0|255] "raw"  CDC
 SG_ FirstData4 m1 : 47|8@0+ (1,0) [0|255] "raw"  CDC
 SG_ UnknownData5 m4 : 47|8@0+ (1,0) [0|255] "raw"  CDC
 SG_ ConsecutiveData5 m2 : 47|8@0+ (1,0) [0|255] "raw"  CDC
 SG_ SingleData5 m0 : 47|8@0+ (1,0) [0|255] "raw"  CDC
 SG_ FlowPadding2 m3 : 39|8@0+ (1,0) [0|255] "raw"  CDC
 SG_ FirstData3 m1 : 39|8@0+ (1,0) [0|255] "raw"  CDC
 SG_ UnknownData4 m4 : 39|8@0+ (1,0) [0|255] "raw"  CDC
 SG_ ConsecutiveData4 m2 : 39|8@0+ (1,0) [0|255] "raw"  CDC
 SG_ SingleData4 m0 : 39|8@0+ (1,0) [0|255] "raw"  CDC
 SG_ FlowPadding1 m3 : 31|8@0+ (1,0) [0|255] "raw"  CDC
 SG_ FirstData2 m1 : 31|8@0+ (1,0) [0|255] "raw"  CDC
 SG_ UnknownData3 m4 : 31|8@0+ (1,0) [0|255] "raw"  CDC
 SG_ ConsecutiveData3 m2 : 31|8@0+ (1,0) [0|255] "raw"  CDC
 SG_ SingleData3 m0 : 31|8@0+ (1,0) [0|255] "raw"  CDC
 SG_ FirstData1 m1 : 23|8@0+ (1,0) [0|255] "raw"  CDC
 SG_ UnknownData2 m4 : 23|8@0+ (1,0) [0|255] "raw"  CDC
 SG_ ConsecutiveData2 m2 : 23|8@0+ (1,0) [0|255] "raw"  CDC
 SG_ SingleData2 m0 : 23|8@0+ (1,0) [0|255] "raw"  CDC
 SG_ SeparationTimeRaw m3 : 23|8@0+ (1,0) [0|255] "raw"  CDC
 SG_ UnknownData1 m4 : 15|8@0+ (1,0) [0|255] "raw"  CDC
 SG_ ConsecutiveData1 m2 : 15|8@0+ (1,0) [0|255] "raw"  CDC
 SG_ SingleData1 m0 : 15|8@0+ (1,0) [0|255] "raw"  CDC
 SG_ BlockSize m3 : 15|8@0+ (1,0) [0|255] "raw"  CDC
 SG_ UnknownPciLow m4 : 3|4@0+ (1,0) [0|15] "raw"  CDC
 SG_ FlowStatus m3 : 3|4@0+ (1,0) [0|15] "raw"  CDC
 SG_ ConsecutiveSequence m2 : 3|4@0+ (1,0) [0|15] "raw"  CDC
 SG_ FirstFrameLength m1 : 3|12@0+ (1,0) [0|4095] "raw"  CDC
 SG_ SingleFrameLength m0 : 3|4@0+ (1,0) [0|15] "raw"  CDC
 SG_ IsoTpFrameType M : 7|4@0+ (1,0) [0|15] ""  CDC

BO_ 630 BSI_VsmSlowData: 8 BSI
 SG_ Unused5 : 57|2@0+ (1,0) [0|3] ""  SDCM,MDS,ICSV,CMB,EMF,MATT,BTEL,OVIP,IDVR,RAD
 SG_ RearOpeningUnlockSelectiv_f38f2f : 58|1@0+ (1,0) [0|1] ""  SDCM,MDS,ICSV,CMB,EMF,MATT,BTEL,OVIP,IDVR,RAD
 SG_ DriverDoorUnlockSelectivi_40d5a3 : 59|1@0+ (1,0) [0|1] ""  SDCM,MDS,ICSV,CMB,EMF,MATT,BTEL,OVIP,IDVR,RAD
 SG_ CabinLoadZoneSelectivityStatus : 60|1@0+ (1,0) [0|1] ""  SDCM,MDS,ICSV,CMB,EMF,MATT,BTEL,OVIP,IDVR,RAD
 SG_ SelectivityFunctionStatus : 61|1@0+ (1,0) [0|1] ""  SDCM,MDS,ICSV,CMB,EMF,MATT,BTEL,OVIP,IDVR,RAD
 SG_ RearOpeningLockStatus : 62|1@0+ (1,0) [0|1] ""  SDCM,MDS,ICSV,CMB,EMF,MATT,BTEL,OVIP,IDVR,RAD
 SG_ TrunkLockingState : 63|1@0+ (1,0) [0|1] ""  SDCM,MDS,ICSV,CMB,EMF,MATT,BTEL,OVIP,IDVR,RAD
 SG_ UreaRemainingAutonomy : 45|14@0+ (1,0) [0|10000] "km"  SDCM,MDS,ICSV,CMB,EMF,MATT,BTEL,OVIP,IDVR,RAD
 SG_ Unused4 : 46|1@0+ (1,0) [0|1] ""  SDCM,MDS,ICSV,CMB,EMF,MATT,BTEL,OVIP,IDVR,RAD
 SG_ UreaAutonomyDisplayRequest : 47|1@0+ (1,0) [0|1] ""  SDCM,MDS,ICSV,CMB,EMF,MATT,BTEL,OVIP,IDVR,RAD
 SG_ TimeMinute : 37|6@0+ (1,0) [0|59] "min"  SDCM,MDS,ICSV,CMB,EMF,MATT,BTEL,OVIP,IDVR,RAD
 SG_ Unused3 : 39|2@0+ (1,0) [0|3] ""  SDCM,MDS,ICSV,CMB,EMF,MATT,BTEL,OVIP,IDVR,RAD
 SG_ TimeHour : 28|5@0+ (1,0) [0|23] "h"  SDCM,MDS,ICSV,CMB,EMF,MATT,BTEL,OVIP,IDVR,RAD
 SG_ Unused2 : 31|3@0+ (1,0) [0|7] ""  SDCM,MDS,ICSV,CMB,EMF,MATT,BTEL,OVIP,IDVR,RAD
 SG_ ClockDay : 21|6@0+ (1,0) [1|31] "day"  SDCM,MDS,ICSV,CMB,EMF,MATT,BTEL,OVIP,IDVR,RAD
 SG_ Unused1 : 23|2@0+ (1,0) [0|3] ""  SDCM,MDS,ICSV,CMB,EMF,MATT,BTEL,OVIP,IDVR,RAD
 SG_ ClockMonth : 11|4@0+ (1,0) [0|15] ""  SDCM,MDS,ICSV,CMB,EMF,MATT,BTEL,OVIP,IDVR,RAD
 SG_ ClockDisplayType : 12|1@0+ (1,0) [0|1] ""  SDCM,MDS,ICSV,CMB,EMF,MATT,BTEL,OVIP,IDVR,RAD
 SG_ VehicleLockingState : 15|3@0+ (1,0) [0|7] ""  SDCM,MDS,ICSV,CMB,EMF,MATT,BTEL,OVIP,IDVR,RAD
 SG_ ClockYear : 6|7@0+ (1,2000) [0|125] "year"  SDCM,MDS,ICSV,CMB,EMF,MATT,BTEL,OVIP,IDVR,RAD
 SG_ ConfigDisplayTime : 7|1@0+ (1,0) [0|1] ""  SDCM,MDS,ICSV,CMB,EMF,MATT,BTEL,OVIP,IDVR,RAD

BO_ 632 BSI_EngineHybridDynamicData6: 3 BSI
 SG_ RawBits20_23 : 19|4@0+ (1,0) [0|15] "raw" Vector__XXX
 SG_ VparkAutoModeActive : 20|1@0+ (1,0) [0|1] ""  BTEL
 SG_ VparkObstaclePresence : 23|3@0+ (1,0) [0|7] ""  BTEL
 SG_ VparkActivationStatus : 9|2@0+ (1,0) [0|3] ""  BTEL
 SG_ VparkViewType : 11|2@0+ (1,0) [0|3] ""  BTEL
 SG_ VparkViewState : 15|4@0+ (1,0) [0|15] ""  BTEL
 SG_ VparkDisplayBrightness : 3|4@0+ (1,0) [0|15] ""  BTEL
 SG_ VparkDisplayContrast : 7|4@0+ (1,0) [0|15] ""  BTEL

BO_ 641 SDCM_UidTableEncryptedToS_67df2b: 8 SDCM
 SG_ FlowPadding5 m3 : 63|8@0+ (1,0) [0|255] "raw"  BSI
 SG_ FirstData6 m1 : 63|8@0+ (1,0) [0|255] "raw"  BSI
 SG_ UnknownData7 m4 : 63|8@0+ (1,0) [0|255] "raw"  BSI
 SG_ ConsecutiveData7 m2 : 63|8@0+ (1,0) [0|255] "raw"  BSI
 SG_ SingleData7 m0 : 63|8@0+ (1,0) [0|255] "raw"  BSI
 SG_ FlowPadding4 m3 : 55|8@0+ (1,0) [0|255] "raw"  BSI
 SG_ FirstData5 m1 : 55|8@0+ (1,0) [0|255] "raw"  BSI
 SG_ UnknownData6 m4 : 55|8@0+ (1,0) [0|255] "raw"  BSI
 SG_ ConsecutiveData6 m2 : 55|8@0+ (1,0) [0|255] "raw"  BSI
 SG_ SingleData6 m0 : 55|8@0+ (1,0) [0|255] "raw"  BSI
 SG_ FlowPadding3 m3 : 47|8@0+ (1,0) [0|255] "raw"  BSI
 SG_ FirstData4 m1 : 47|8@0+ (1,0) [0|255] "raw"  BSI
 SG_ UnknownData5 m4 : 47|8@0+ (1,0) [0|255] "raw"  BSI
 SG_ ConsecutiveData5 m2 : 47|8@0+ (1,0) [0|255] "raw"  BSI
 SG_ SingleData5 m0 : 47|8@0+ (1,0) [0|255] "raw"  BSI
 SG_ FlowPadding2 m3 : 39|8@0+ (1,0) [0|255] "raw"  BSI
 SG_ FirstData3 m1 : 39|8@0+ (1,0) [0|255] "raw"  BSI
 SG_ UnknownData4 m4 : 39|8@0+ (1,0) [0|255] "raw"  BSI
 SG_ ConsecutiveData4 m2 : 39|8@0+ (1,0) [0|255] "raw"  BSI
 SG_ SingleData4 m0 : 39|8@0+ (1,0) [0|255] "raw"  BSI
 SG_ FlowPadding1 m3 : 31|8@0+ (1,0) [0|255] "raw"  BSI
 SG_ FirstData2 m1 : 31|8@0+ (1,0) [0|255] "raw"  BSI
 SG_ UnknownData3 m4 : 31|8@0+ (1,0) [0|255] "raw"  BSI
 SG_ ConsecutiveData3 m2 : 31|8@0+ (1,0) [0|255] "raw"  BSI
 SG_ SingleData3 m0 : 31|8@0+ (1,0) [0|255] "raw"  BSI
 SG_ FirstData1 m1 : 23|8@0+ (1,0) [0|255] "raw"  BSI
 SG_ UnknownData2 m4 : 23|8@0+ (1,0) [0|255] "raw"  BSI
 SG_ ConsecutiveData2 m2 : 23|8@0+ (1,0) [0|255] "raw"  BSI
 SG_ SingleData2 m0 : 23|8@0+ (1,0) [0|255] "raw"  BSI
 SG_ SeparationTimeRaw m3 : 23|8@0+ (1,0) [0|255] "raw"  BSI
 SG_ UnknownData1 m4 : 15|8@0+ (1,0) [0|255] "raw"  BSI
 SG_ ConsecutiveData1 m2 : 15|8@0+ (1,0) [0|255] "raw"  BSI
 SG_ SingleData1 m0 : 15|8@0+ (1,0) [0|255] "raw"  BSI
 SG_ BlockSize m3 : 15|8@0+ (1,0) [0|255] "raw"  BSI
 SG_ UnknownPciLow m4 : 3|4@0+ (1,0) [0|15] "raw"  BSI
 SG_ FlowStatus m3 : 3|4@0+ (1,0) [0|15] "raw"  BSI
 SG_ ConsecutiveSequence m2 : 3|4@0+ (1,0) [0|15] "raw"  BSI
 SG_ FirstFrameLength m1 : 3|12@0+ (1,0) [0|4095] "raw"  BSI
 SG_ SingleFrameLength m0 : 3|4@0+ (1,0) [0|15] "raw"  BSI
 SG_ IsoTpFrameType M : 7|4@0+ (1,0) [0|15] ""  BSI

BO_ 643 BTEL_OdiDynamicDataMultiR_7da07a: 8 BTEL
 SG_ OdiDynDataMultiRequestCen_7bee23 : 7|64@0+ (1,0) [0|18446744073709551615] ""  MDS

BO_ 660 BSI_TractionBatteryDynamicData4: 8 BSI
 SG_ FlowPadding5 m3 : 63|8@0+ (1,0) [0|255] "raw"  MDS
 SG_ FirstData6 m1 : 63|8@0+ (1,0) [0|255] "raw"  MDS
 SG_ UnknownData7 m4 : 63|8@0+ (1,0) [0|255] "raw"  MDS
 SG_ ConsecutiveData7 m2 : 63|8@0+ (1,0) [0|255] "raw"  MDS
 SG_ SingleData7 m0 : 63|8@0+ (1,0) [0|255] "raw"  MDS
 SG_ FlowPadding4 m3 : 55|8@0+ (1,0) [0|255] "raw"  MDS
 SG_ FirstData5 m1 : 55|8@0+ (1,0) [0|255] "raw"  MDS
 SG_ UnknownData6 m4 : 55|8@0+ (1,0) [0|255] "raw"  MDS
 SG_ ConsecutiveData6 m2 : 55|8@0+ (1,0) [0|255] "raw"  MDS
 SG_ SingleData6 m0 : 55|8@0+ (1,0) [0|255] "raw"  MDS
 SG_ FlowPadding3 m3 : 47|8@0+ (1,0) [0|255] "raw"  MDS
 SG_ FirstData4 m1 : 47|8@0+ (1,0) [0|255] "raw"  MDS
 SG_ UnknownData5 m4 : 47|8@0+ (1,0) [0|255] "raw"  MDS
 SG_ ConsecutiveData5 m2 : 47|8@0+ (1,0) [0|255] "raw"  MDS
 SG_ SingleData5 m0 : 47|8@0+ (1,0) [0|255] "raw"  MDS
 SG_ FlowPadding2 m3 : 39|8@0+ (1,0) [0|255] "raw"  MDS
 SG_ FirstData3 m1 : 39|8@0+ (1,0) [0|255] "raw"  MDS
 SG_ UnknownData4 m4 : 39|8@0+ (1,0) [0|255] "raw"  MDS
 SG_ ConsecutiveData4 m2 : 39|8@0+ (1,0) [0|255] "raw"  MDS
 SG_ SingleData4 m0 : 39|8@0+ (1,0) [0|255] "raw"  MDS
 SG_ FlowPadding1 m3 : 31|8@0+ (1,0) [0|255] "raw"  MDS
 SG_ FirstData2 m1 : 31|8@0+ (1,0) [0|255] "raw"  MDS
 SG_ UnknownData3 m4 : 31|8@0+ (1,0) [0|255] "raw"  MDS
 SG_ ConsecutiveData3 m2 : 31|8@0+ (1,0) [0|255] "raw"  MDS
 SG_ SingleData3 m0 : 31|8@0+ (1,0) [0|255] "raw"  MDS
 SG_ FirstData1 m1 : 23|8@0+ (1,0) [0|255] "raw"  MDS
 SG_ UnknownData2 m4 : 23|8@0+ (1,0) [0|255] "raw"  MDS
 SG_ ConsecutiveData2 m2 : 23|8@0+ (1,0) [0|255] "raw"  MDS
 SG_ SingleData2 m0 : 23|8@0+ (1,0) [0|255] "raw"  MDS
 SG_ SeparationTimeRaw m3 : 23|8@0+ (1,0) [0|255] "raw"  MDS
 SG_ UnknownData1 m4 : 15|8@0+ (1,0) [0|255] "raw"  MDS
 SG_ ConsecutiveData1 m2 : 15|8@0+ (1,0) [0|255] "raw"  MDS
 SG_ SingleData1 m0 : 15|8@0+ (1,0) [0|255] "raw"  MDS
 SG_ BlockSize m3 : 15|8@0+ (1,0) [0|255] "raw"  MDS
 SG_ UnknownPciLow m4 : 3|4@0+ (1,0) [0|15] "raw"  MDS
 SG_ FlowStatus m3 : 3|4@0+ (1,0) [0|15] "raw"  MDS
 SG_ ConsecutiveSequence m2 : 3|4@0+ (1,0) [0|15] "raw"  MDS
 SG_ FirstFrameLength m1 : 3|12@0+ (1,0) [0|4095] "raw"  MDS
 SG_ SingleFrameLength m0 : 3|4@0+ (1,0) [0|15] "raw"  MDS
 SG_ IsoTpFrameType M : 7|4@0+ (1,0) [0|15] ""  MDS

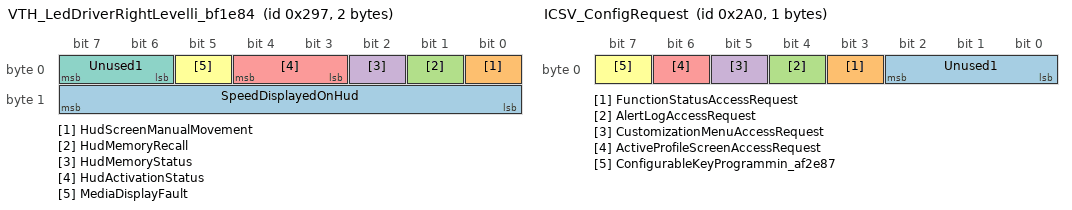
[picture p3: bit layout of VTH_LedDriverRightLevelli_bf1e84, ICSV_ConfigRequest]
BO_ 663 VTH_LedDriverRightLevelli_bf1e84: 2 VTH
 SG_ SpeedDisplayedOnHud : 15|8@0+ (1,0) [0|254] ""  BSI,MATT
 SG_ HudScreenManualMovement : 0|1@0+ (1,0) [0|1] ""  BSI,MATT
 SG_ HudMemoryRecall : 1|1@0+ (1,0) [0|1] ""  BSI,MATT
 SG_ HudMemoryStatus : 2|1@0+ (1,0) [0|1] ""  BSI,MATT
 SG_ HudActivationStatus : 4|2@0+ (1,0) [0|3] ""  BSI,MATT
 SG_ MediaDisplayFault : 5|1@0+ (1,0) [0|1] ""  BSI,MATT
 SG_ Unused1 : 7|2@0+ (1,0) [0|3] ""  BSI,MATT

BO_ 667 BTEL_ClimatePrecondSched2: 7 BTEL
 SG_ ClimatePrecondSlot4StartTime : 42|11@0+ (1,0) [0|1440] "min"  BSI
 SG_ Unused3 : 47|5@0+ (1,0) [0|31] ""  BSI
 SG_ ClimatePrecondSundaySlot4Enabled : 32|1@0+ (1,0) [0|1] ""  BSI
 SG_ ClimatePrecondSaturdaySlo_419d2b : 33|1@0+ (1,0) [0|1] ""  BSI
 SG_ ClimatePrecondFridaySlot4Enabled : 34|1@0+ (1,0) [0|1] ""  BSI
 SG_ ClimatePrecondThursdaySlo_d85853 : 35|1@0+ (1,0) [0|1] ""  BSI
 SG_ ClimatePrecondWednesdaySl_c2d848 : 36|1@0+ (1,0) [0|1] ""  BSI
 SG_ ClimatePrecondTuesdaySlot_ddb9f8 : 37|1@0+ (1,0) [0|1] ""  BSI
 SG_ ClimatePrecondMondaySlot4Enabled : 38|1@0+ (1,0) [0|1] ""  BSI
 SG_ ClimatePrecondSlot4Enabled : 39|1@0+ (1,0) [0|1] ""  BSI
 SG_ ClimatePrecondSlot3StartTime : 18|11@0+ (1,0) [0|1440] "min"  BSI
 SG_ Unused2 : 23|5@0+ (1,0) [0|31] ""  BSI
 SG_ ClimatePrecondSundaySlot3Enabled : 8|1@0+ (1,0) [0|1] ""  BSI
 SG_ ClimatePrecondSaturdaySlo_def41f : 9|1@0+ (1,0) [0|1] ""  BSI
 SG_ ClimatePrecondFridaySlot3Enabled : 10|1@0+ (1,0) [0|1] ""  BSI
 SG_ ClimatePrecondThursdaySlo_f9fbde : 11|1@0+ (1,0) [0|1] ""  BSI
 SG_ ClimatePrecondWednesdaySl_dfe9f3 : 12|1@0+ (1,0) [0|1] ""  BSI
 SG_ ClimatePrecondTuesdaySlot_f7a007 : 13|1@0+ (1,0) [0|1] ""  BSI
 SG_ ClimatePrecondMondaySlot3Enabled : 14|1@0+ (1,0) [0|1] ""  BSI
 SG_ ClimatePrecondSlot3Enabled : 15|1@0+ (1,0) [0|1] ""  BSI
 SG_ Unused1 : 7|8@0+ (1,0) [0|255] ""  BSI

BO_ 671 EMF_KmlTelephoneReplyFlowControl: 8 EMF
 SG_ FlowPadding5 m3 : 63|8@0+ (1,0) [0|255] "raw"  RAD
 SG_ FirstData6 m1 : 63|8@0+ (1,0) [0|255] "raw"  RAD
 SG_ UnknownData7 m4 : 63|8@0+ (1,0) [0|255] "raw"  RAD
 SG_ ConsecutiveData7 m2 : 63|8@0+ (1,0) [0|255] "raw"  RAD
 SG_ SingleData7 m0 : 63|8@0+ (1,0) [0|255] "raw"  RAD
 SG_ FlowPadding4 m3 : 55|8@0+ (1,0) [0|255] "raw"  RAD
 SG_ FirstData5 m1 : 55|8@0+ (1,0) [0|255] "raw"  RAD
 SG_ UnknownData6 m4 : 55|8@0+ (1,0) [0|255] "raw"  RAD
 SG_ ConsecutiveData6 m2 : 55|8@0+ (1,0) [0|255] "raw"  RAD
 SG_ SingleData6 m0 : 55|8@0+ (1,0) [0|255] "raw"  RAD
 SG_ FlowPadding3 m3 : 47|8@0+ (1,0) [0|255] "raw"  RAD
 SG_ FirstData4 m1 : 47|8@0+ (1,0) [0|255] "raw"  RAD
 SG_ UnknownData5 m4 : 47|8@0+ (1,0) [0|255] "raw"  RAD
 SG_ ConsecutiveData5 m2 : 47|8@0+ (1,0) [0|255] "raw"  RAD
 SG_ SingleData5 m0 : 47|8@0+ (1,0) [0|255] "raw"  RAD
 SG_ FlowPadding2 m3 : 39|8@0+ (1,0) [0|255] "raw"  RAD
 SG_ FirstData3 m1 : 39|8@0+ (1,0) [0|255] "raw"  RAD
 SG_ UnknownData4 m4 : 39|8@0+ (1,0) [0|255] "raw"  RAD
 SG_ ConsecutiveData4 m2 : 39|8@0+ (1,0) [0|255] "raw"  RAD
 SG_ SingleData4 m0 : 39|8@0+ (1,0) [0|255] "raw"  RAD
 SG_ FlowPadding1 m3 : 31|8@0+ (1,0) [0|255] "raw"  RAD
 SG_ FirstData2 m1 : 31|8@0+ (1,0) [0|255] "raw"  RAD
 SG_ UnknownData3 m4 : 31|8@0+ (1,0) [0|255] "raw"  RAD
 SG_ ConsecutiveData3 m2 : 31|8@0+ (1,0) [0|255] "raw"  RAD
 SG_ SingleData3 m0 : 31|8@0+ (1,0) [0|255] "raw"  RAD
 SG_ FirstData1 m1 : 23|8@0+ (1,0) [0|255] "raw"  RAD
 SG_ UnknownData2 m4 : 23|8@0+ (1,0) [0|255] "raw"  RAD
 SG_ ConsecutiveData2 m2 : 23|8@0+ (1,0) [0|255] "raw"  RAD
 SG_ SingleData2 m0 : 23|8@0+ (1,0) [0|255] "raw"  RAD
 SG_ SeparationTimeRaw m3 : 23|8@0+ (1,0) [0|255] "raw"  RAD
 SG_ UnknownData1 m4 : 15|8@0+ (1,0) [0|255] "raw"  RAD
 SG_ ConsecutiveData1 m2 : 15|8@0+ (1,0) [0|255] "raw"  RAD
 SG_ SingleData1 m0 : 15|8@0+ (1,0) [0|255] "raw"  RAD
 SG_ BlockSize m3 : 15|8@0+ (1,0) [0|255] "raw"  RAD
 SG_ UnknownPciLow m4 : 3|4@0+ (1,0) [0|15] "raw"  RAD
 SG_ FlowStatus m3 : 3|4@0+ (1,0) [0|15] "raw"  RAD
 SG_ ConsecutiveSequence m2 : 3|4@0+ (1,0) [0|15] "raw"  RAD
 SG_ FirstFrameLength m1 : 3|12@0+ (1,0) [0|4095] "raw"  RAD
 SG_ SingleFrameLength m0 : 3|4@0+ (1,0) [0|15] "raw"  RAD
 SG_ IsoTpFrameType M : 7|4@0+ (1,0) [0|15] ""  RAD

BO_ 672 ICSV_ConfigRequest: 1 ICSV
 SG_ Unused1 : 2|3@0+ (1,0) [0|7] ""  EMF,BTEL,MATT,OVIP,RAD
 SG_ FunctionStatusAccessRequest : 3|1@0+ (1,0) [0|1] ""  EMF,BTEL,MATT,OVIP,RAD
 SG_ AlertLogAccessRequest : 4|1@0+ (1,0) [0|1] ""  EMF,BTEL,MATT,OVIP,RAD
 SG_ CustomizationMenuAccessRequest : 5|1@0+ (1,0) [0|1] ""  EMF,BTEL,MATT,OVIP,RAD
 SG_ ActiveProfileScreenAccessRequest : 6|1@0+ (1,0) [0|1] ""  EMF,BTEL,MATT,OVIP,RAD
 SG_ ConfigurableKeyProgrammin_af2e87 : 7|1@0+ (1,0) [0|1] ""  EMF,BTEL,MATT,OVIP,RAD

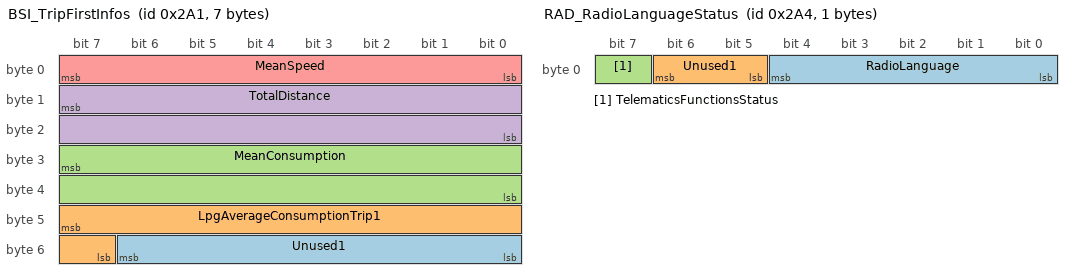
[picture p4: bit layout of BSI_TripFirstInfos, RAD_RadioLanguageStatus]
BO_ 673 BSI_TripFirstInfos: 7 BSI
 SG_ Unused1 : 54|7@0+ (1,0) [0|127] ""  BTEL,EMF,CMB,MATT,BGP,OVIP,RAD
 SG_ LpgAverageConsumptionTrip1 : 47|9@0+ (0.1,0) [0|30] "L/100km"  BTEL,EMF,CMB,MATT,BGP,OVIP,RAD
 SG_ MeanConsumption : 31|16@0+ (0.1,0) [0|30] "L/100km"  BTEL,EMF,CMB,MATT,BGP,OVIP,RAD
 SG_ TotalDistance : 15|16@0+ (1,0) [0|50000] "km"  BTEL,EMF,CMB,MATT,BGP,OVIP,RAD
 SG_ MeanSpeed : 7|8@0+ (1,0) [0|250] "km/h"  BTEL,EMF,CMB,MATT,BGP,OVIP,RAD

BO_ 674 ICSV_CdChangerReplyPayload: 8 ICSV
 SG_ FlowPadding5 m3 : 63|8@0+ (1,0) [0|255] "raw"  BTEL,OVIP,EMF,RAD
 SG_ FirstData6 m1 : 63|8@0+ (1,0) [0|255] "raw"  BTEL,OVIP,EMF,RAD
 SG_ UnknownData7 m4 : 63|8@0+ (1,0) [0|255] "raw"  BTEL,OVIP,EMF,RAD
 SG_ ConsecutiveData7 m2 : 63|8@0+ (1,0) [0|255] "raw"  BTEL,OVIP,EMF,RAD
 SG_ SingleData7 m0 : 63|8@0+ (1,0) [0|255] "raw"  BTEL,OVIP,EMF,RAD
 SG_ FlowPadding4 m3 : 55|8@0+ (1,0) [0|255] "raw"  BTEL,OVIP,EMF,RAD
 SG_ FirstData5 m1 : 55|8@0+ (1,0) [0|255] "raw"  BTEL,OVIP,EMF,RAD
 SG_ UnknownData6 m4 : 55|8@0+ (1,0) [0|255] "raw"  BTEL,OVIP,EMF,RAD
 SG_ ConsecutiveData6 m2 : 55|8@0+ (1,0) [0|255] "raw"  BTEL,OVIP,EMF,RAD
 SG_ SingleData6 m0 : 55|8@0+ (1,0) [0|255] "raw"  BTEL,OVIP,EMF,RAD
 SG_ FlowPadding3 m3 : 47|8@0+ (1,0) [0|255] "raw"  BTEL,OVIP,EMF,RAD
 SG_ FirstData4 m1 : 47|8@0+ (1,0) [0|255] "raw"  BTEL,OVIP,EMF,RAD
 SG_ UnknownData5 m4 : 47|8@0+ (1,0) [0|255] "raw"  BTEL,OVIP,EMF,RAD
 SG_ ConsecutiveData5 m2 : 47|8@0+ (1,0) [0|255] "raw"  BTEL,OVIP,EMF,RAD
 SG_ SingleData5 m0 : 47|8@0+ (1,0) [0|255] "raw"  BTEL,OVIP,EMF,RAD
 SG_ FlowPadding2 m3 : 39|8@0+ (1,0) [0|255] "raw"  BTEL,OVIP,EMF,RAD
 SG_ FirstData3 m1 : 39|8@0+ (1,0) [0|255] "raw"  BTEL,OVIP,EMF,RAD
 SG_ UnknownData4 m4 : 39|8@0+ (1,0) [0|255] "raw"  BTEL,OVIP,EMF,RAD
 SG_ ConsecutiveData4 m2 : 39|8@0+ (1,0) [0|255] "raw"  BTEL,OVIP,EMF,RAD
 SG_ SingleData4 m0 : 39|8@0+ (1,0) [0|255] "raw"  BTEL,OVIP,EMF,RAD
 SG_ FlowPadding1 m3 : 31|8@0+ (1,0) [0|255] "raw"  BTEL,OVIP,EMF,RAD
 SG_ FirstData2 m1 : 31|8@0+ (1,0) [0|255] "raw"  BTEL,OVIP,EMF,RAD
 SG_ UnknownData3 m4 : 31|8@0+ (1,0) [0|255] "raw"  BTEL,OVIP,EMF,RAD
 SG_ ConsecutiveData3 m2 : 31|8@0+ (1,0) [0|255] "raw"  BTEL,OVIP,EMF,RAD
 SG_ SingleData3 m0 : 31|8@0+ (1,0) [0|255] "raw"  BTEL,OVIP,EMF,RAD
 SG_ FirstData1 m1 : 23|8@0+ (1,0) [0|255] "raw"  BTEL,OVIP,EMF,RAD
 SG_ UnknownData2 m4 : 23|8@0+ (1,0) [0|255] "raw"  BTEL,OVIP,EMF,RAD
 SG_ ConsecutiveData2 m2 : 23|8@0+ (1,0) [0|255] "raw"  BTEL,OVIP,EMF,RAD
 SG_ SingleData2 m0 : 23|8@0+ (1,0) [0|255] "raw"  BTEL,OVIP,EMF,RAD
 SG_ SeparationTimeRaw m3 : 23|8@0+ (1,0) [0|255] "raw"  BTEL,OVIP,EMF,RAD
 SG_ UnknownData1 m4 : 15|8@0+ (1,0) [0|255] "raw"  BTEL,OVIP,EMF,RAD
 SG_ ConsecutiveData1 m2 : 15|8@0+ (1,0) [0|255] "raw"  BTEL,OVIP,EMF,RAD
 SG_ SingleData1 m0 : 15|8@0+ (1,0) [0|255] "raw"  BTEL,OVIP,EMF,RAD
 SG_ BlockSize m3 : 15|8@0+ (1,0) [0|255] "raw"  BTEL,OVIP,EMF,RAD
 SG_ UnknownPciLow m4 : 3|4@0+ (1,0) [0|15] "raw"  BTEL,OVIP,EMF,RAD
 SG_ FlowStatus m3 : 3|4@0+ (1,0) [0|15] "raw"  BTEL,OVIP,EMF,RAD
 SG_ ConsecutiveSequence m2 : 3|4@0+ (1,0) [0|15] "raw"  BTEL,OVIP,EMF,RAD
 SG_ FirstFrameLength m1 : 3|12@0+ (1,0) [0|4095] "raw"  BTEL,OVIP,EMF,RAD
 SG_ SingleFrameLength m0 : 3|4@0+ (1,0) [0|15] "raw"  BTEL,OVIP,EMF,RAD
 SG_ IsoTpFrameType M : 7|4@0+ (1,0) [0|15] ""  BTEL,OVIP,EMF,RAD

BO_ 676 RAD_RadioLanguageStatus: 1 RAD
 SG_ RadioLanguage : 4|5@0+ (1,0) [0|31] ""  BSI
 SG_ Unused1 : 6|2@0+ (1,0) [0|3] ""  BSI
 SG_ TelematicsFunctionsStatus : 7|1@0+ (1,0) [0|1] ""  BSI

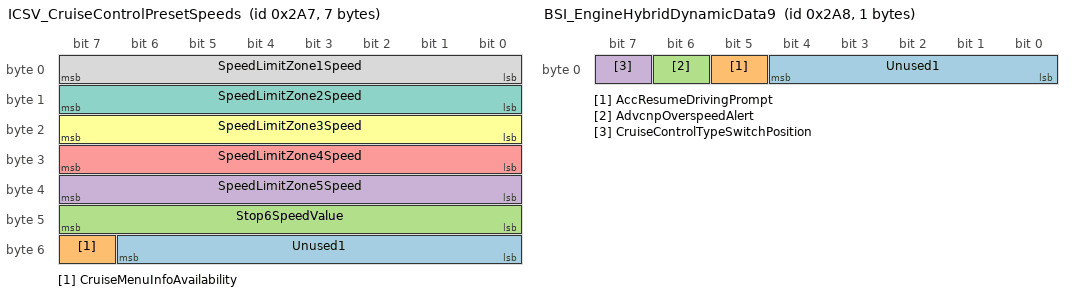
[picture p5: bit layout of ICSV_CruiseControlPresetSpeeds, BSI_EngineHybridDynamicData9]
BO_ 679 ICSV_CruiseControlPresetSpeeds: 7 ICSV
 SG_ Unused1 : 54|7@0+ (1,0) [0|127] ""  CMB,BTEL,OVIP,MATT,RAD
 SG_ CruiseMenuInfoAvailability : 55|1@0+ (1,0) [0|1] ""  CMB,BTEL,OVIP,MATT,RAD
 SG_ Stop6SpeedValue : 47|8@0+ (1,0) [0|253] "km/h"  CMB,BTEL,OVIP,MATT,RAD
 SG_ SpeedLimitZone5Speed : 39|8@0+ (1,0) [0|254] "km/h"  CMB,BTEL,OVIP,MATT,RAD
 SG_ SpeedLimitZone4Speed : 31|8@0+ (1,0) [0|254] "km/h"  CMB,BTEL,OVIP,MATT,RAD
 SG_ SpeedLimitZone3Speed : 23|8@0+ (1,0) [0|254] "km/h"  CMB,BTEL,OVIP,MATT,RAD
 SG_ SpeedLimitZone2Speed : 15|8@0+ (1,0) [0|254] "km/h"  CMB,BTEL,OVIP,MATT,RAD
 SG_ SpeedLimitZone1Speed : 7|8@0+ (1,0) [0|254] "km/h"  CMB,BTEL,OVIP,MATT,RAD

BO_ 680 BSI_EngineHybridDynamicData9: 1 BSI
 SG_ Unused1 : 4|5@0+ (1,0) [0|31] ""  OVIP,BTEL,CMB,MATT,RAD
 SG_ AccResumeDrivingPrompt : 5|1@0+ (1,0) [0|1] ""  OVIP,BTEL,CMB,MATT,RAD
 SG_ AdvcnpOverspeedAlert : 6|1@0+ (1,0) [0|1] ""  OVIP,BTEL,CMB,MATT,RAD
 SG_ CruiseControlTypeSwitchPosition : 7|1@0+ (1,0) [0|1] ""  OVIP,BTEL,CMB,MATT,RAD

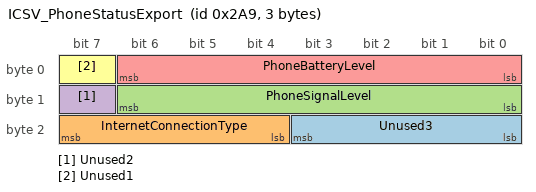
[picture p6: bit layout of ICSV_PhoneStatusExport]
BO_ 681 ICSV_PhoneStatusExport: 3 ICSV
 SG_ Unused3 : 19|4@0+ (1,0) [0|15] ""  CMB
 SG_ InternetConnectionType : 23|4@0+ (1,0) [0|15] ""  CMB
 SG_ PhoneSignalLevel : 14|7@0+ (1,0) [0|100] "%"  CMB
 SG_ Unused2 : 15|1@0+ (1,0) [0|1] ""  CMB
 SG_ PhoneBatteryLevel : 6|7@0+ (1,0) [0|100] "%"  CMB
 SG_ Unused1 : 7|1@0+ (1,0) [0|1] ""  CMB

BO_ 685 BSI_ClimateHmiCommand: 8 BSI
 SG_ CabinAirQualityLevel : 57|2@0+ (1,0) [0|3] ""  ICSV,CMB,FMUX,BTEL,OVIP,RAD
 SG_ CabinAirPurifierState : 60|3@0+ (1,0) [0|7] ""  ICSV,CMB,FMUX,BTEL,OVIP,RAD
 SG_ Unused2 : 61|1@0+ (1,0) [0|1] ""  ICSV,CMB,FMUX,BTEL,OVIP,RAD
 SG_ CabinAirPurificationState : 63|2@0+ (1,0) [0|3] ""  ICSV,CMB,FMUX,BTEL,OVIP,RAD
 SG_ RearLeftBlowerSetpoint : 55|8@0+ (1,0) [0|100] "%"  ICSV,CMB,FMUX,BTEL,OVIP,RAD
 SG_ RearHeatedVentilatedSeatsConfig : 41|2@0+ (1,0) [0|3] ""  ICSV,CMB,FMUX,BTEL,OVIP,RAD
 SG_ CabinAirFilterState : 43|2@0+ (1,0) [0|3] ""  ICSV,CMB,FMUX,BTEL,OVIP,RAD
 SG_ IonizerCommand : 45|2@0+ (1,0) [0|3] ""  ICSV,CMB,FMUX,BTEL,OVIP,RAD
 SG_ IonizerState : 47|2@0+ (1,0) [0|3] ""  ICSV,CMB,FMUX,BTEL,OVIP,RAD
 SG_ RearLeftBlowerMinusState : 35|4@0+ (1,0) [0|15] ""  ICSV,CMB,FMUX,BTEL,OVIP,RAD
 SG_ RearBlowerPlusSwitchState : 39|4@0+ (1,0) [0|15] ""  ICSV,CMB,FMUX,BTEL,OVIP,RAD
 SG_ FrontBlowerMinusState : 27|4@0+ (1,0) [0|15] ""  ICSV,CMB,FMUX,BTEL,OVIP,RAD
 SG_ FrontBlowerPlusSwitchState : 31|4@0+ (1,0) [0|15] ""  ICSV,CMB,FMUX,BTEL,OVIP,RAD
 SG_ FrontBlowerMotorSetpoint : 23|8@0+ (1,0) [0|100] "%"  ICSV,CMB,FMUX,BTEL,OVIP,RAD
 SG_ Unused1 : 8|1@0+ (1,0) [0|1] ""  ICSV,CMB,FMUX,BTEL,OVIP,RAD
 SG_ RearCentralDisplayPresence : 9|1@0+ (1,0) [0|1] ""  ICSV,CMB,FMUX,BTEL,OVIP,RAD
 SG_ HeatedWindshieldPresence : 10|1@0+ (1,0) [0|1] ""  ICSV,CMB,FMUX,BTEL,OVIP,RAD
 SG_ HeatedVentilatedSeatsConfig : 12|2@0+ (1,0) [0|3] ""  ICSV,CMB,FMUX,BTEL,OVIP,RAD
 SG_ AirInletSetpoint : 14|2@0+ (1,0) [0|3] ""  ICSV,CMB,FMUX,BTEL,OVIP,RAD
 SG_ HeatedWindshieldIndicatorRequest : 15|1@0+ (1,0) [0|1] ""  ICSV,CMB,FMUX,BTEL,OVIP,RAD
 SG_ AcSystemType : 1|2@0+ (1,0) [0|3] ""  ICSV,CMB,FMUX,BTEL,OVIP,RAD
 SG_ CenterTemperatureSetpoint : 4|3@0+ (1,0) [0|7] ""  ICSV,CMB,FMUX,BTEL,OVIP,RAD
 SG_ LuchWarningLamp : 5|1@0+ (1,0) [0|1] ""  ICSV,CMB,FMUX,BTEL,OVIP,RAD
 SG_ RestoreModeEnabled : 6|1@0+ (1,0) [0|1] ""  ICSV,CMB,FMUX,BTEL,OVIP,RAD
 SG_ AcLcdDisplayOffRequest : 7|1@0+ (1,0) [0|1] ""  ICSV,CMB,FMUX,BTEL,OVIP,RAD

BO_TX_BU_ 603 : BTEL,MDS,OVIP;
BO_TX_BU_ 607 : EMF,ICSV;
BO_TX_BU_ 611 : RAD,ICSV;
BO_TX_BU_ 612 : OVIP,BTEL;
BO_TX_BU_ 613 : RAD,ICSV;
BO_TX_BU_ 615 : ICSV,BSI;
BO_TX_BU_ 617 : MATT,CMB,VTH,ICSV;
BO_TX_BU_ 625 : RAD,ICSV,BTEL,EMF,OVIP;
BO_TX_BU_ 663 : VTH,CMB;
BO_TX_BU_ 667 : BTEL,MDS,OVIP;
BO_TX_BU_ 671 : EMF,ICSV;
BO_TX_BU_ 672 : ICSV,BSI;
BO_TX_BU_ 674 : ICSV,CDC;
BO_TX_BU_ 676 : RAD,ICSV;
BO_TX_BU_ 679 : ICSV,BSI;
BO_TX_BU_ 681 : ICSV,BTEL,OVIP;
CM_ BO_ 603 "DATABASE_CANDIDATE: physical interpretation unverified; capture/layout evidence reported separately. INFO-DIV CAN, 125000 bit/s; CAN ID 0x25B. PSA-RE title: CLIMATE_PRECOND_PROGRAM_SCREEN. Climate preconditioning weekly programming screen requests (part 1). Source: https://github.com/prototux/PSA-RE/blob/67f7581e7622410efdbb29c7eda3b86982b9b450/buses/AEE2010.full/LS.INFO-DIV/25B.yml. Source sender alternatives: BTEL,MDS,OVIP; physical TX/gateway forwarding not verified. ";
CM_ SG_ 603 ClimatePrecondSlot2StartTime "DATABASE_CANDIDATE: physical interpretation unverified; capture/layout evidence reported separately. PSA-RE bits 6.2-7.0. Start time of thermal preconditioning schedule 2 Upstream default raw=0 (not necessarily valid data).";
CM_ SG_ 603 Unused3 "DATABASE_CANDIDATE: physical interpretation unverified; capture/layout evidence reported separately. PSA-RE bits 6.7-6.3. ";
CM_ SG_ 603 ClimatePrecondSundaySlot2Enabled "DATABASE_CANDIDATE: physical interpretation unverified; capture/layout evidence reported separately. PSA-RE bits 5.0. Thermal preconditioning schedule 2 enabled (Sunday) Upstream default raw=0 (not necessarily valid data).";
CM_ SG_ 603 ClimatePrecondSaturdaySlo_fd2bfe "DATABASE_CANDIDATE: physical interpretation unverified; capture/layout evidence reported separately. PSA-RE bits 5.1. Thermal preconditioning schedule 2 enabled (Saturday) Upstream default raw=0 (not necessarily valid data).";
CM_ SG_ 603 ClimatePrecondFridaySlot2Enabled "DATABASE_CANDIDATE: physical interpretation unverified; capture/layout evidence reported separately. PSA-RE bits 5.2. Thermal preconditioning schedule 2 enabled (Friday) Upstream default raw=0 (not necessarily valid data).";
CM_ SG_ 603 ClimatePrecondThursdaySlo_8ba9ec "DATABASE_CANDIDATE: physical interpretation unverified; capture/layout evidence reported separately. PSA-RE bits 5.3. Thermal preconditioning schedule 2 enabled (Thursday) Upstream default raw=0 (not necessarily valid data).";
CM_ SG_ 603 ClimatePrecondWednesdaySl_20214f "DATABASE_CANDIDATE: physical interpretation unverified; capture/layout evidence reported separately. PSA-RE bits 5.4. Thermal preconditioning schedule 2 enabled (Wednesday) Upstream default raw=0 (not necessarily valid data).";
CM_ SG_ 603 ClimatePrecondTuesdaySlot_413385 "DATABASE_CANDIDATE: physical interpretation unverified; capture/layout evidence reported separately. PSA-RE bits 5.5. Thermal preconditioning schedule 2 enabled (Tuesday) Upstream default raw=0 (not necessarily valid data).";
CM_ SG_ 603 ClimatePrecondMondaySlot2Enabled "DATABASE_CANDIDATE: physical interpretation unverified; capture/layout evidence reported separately. PSA-RE bits 5.6. Thermal preconditioning schedule 2 enabled (Monday) Upstream default raw=0 (not necessarily valid data).";
CM_ SG_ 603 ClimatePrecondSlot2Enabled "DATABASE_CANDIDATE: physical interpretation unverified; capture/layout evidence reported separately. PSA-RE bits 5.7. Thermal preconditioning schedule 2 enabled Upstream default raw=0 (not necessarily valid data).";
CM_ SG_ 603 ClimatePrecondSlot1StartTime "DATABASE_CANDIDATE: physical interpretation unverified; capture/layout evidence reported separately. PSA-RE bits 3.2-4.0. Start time of thermal preconditioning schedule 1 Upstream default raw=0 (not necessarily valid data).";
CM_ SG_ 603 Unused2 "DATABASE_CANDIDATE: physical interpretation unverified; capture/layout evidence reported separately. PSA-RE bits 3.7-3.3. ";
CM_ SG_ 603 ClimatePrecondSundaySlot1Enabled "DATABASE_CANDIDATE: physical interpretation unverified; capture/layout evidence reported separately. PSA-RE bits 2.0. Thermal preconditioning schedule 1 enabled (Sunday) Upstream default raw=0 (not necessarily valid data).";
CM_ SG_ 603 ClimatePrecondSaturdaySlo_c187b9 "DATABASE_CANDIDATE: physical interpretation unverified; capture/layout evidence reported separately. PSA-RE bits 2.1. Thermal preconditioning schedule 1 enabled (Saturday) Upstream default raw=0 (not necessarily valid data).";
CM_ SG_ 603 ClimatePrecondFridaySlot1Enabled "DATABASE_CANDIDATE: physical interpretation unverified; capture/layout evidence reported separately. PSA-RE bits 2.2. Thermal preconditioning schedule 1 enabled (Friday) Upstream default raw=0 (not necessarily valid data).";
CM_ SG_ 603 ClimatePrecondThursdaySlo_13efd6 "DATABASE_CANDIDATE: physical interpretation unverified; capture/layout evidence reported separately. PSA-RE bits 2.3. Thermal preconditioning schedule 1 enabled (Thursday) Upstream default raw=0 (not necessarily valid data).";
CM_ SG_ 603 ClimatePrecondWednesdaySl_d65ca4 "DATABASE_CANDIDATE: physical interpretation unverified; capture/layout evidence reported separately. PSA-RE bits 2.4. Thermal preconditioning schedule 1 enabled (Wednesday) Upstream default raw=0 (not necessarily valid data).";
CM_ SG_ 603 ClimatePrecondTuesdaySlot_1bddd8 "DATABASE_CANDIDATE: physical interpretation unverified; capture/layout evidence reported separately. PSA-RE bits 2.5. Thermal preconditioning schedule 1 enabled (Tuesday) Upstream default raw=0 (not necessarily valid data).";
CM_ SG_ 603 ClimatePrecondMondaySlot1Enabled "DATABASE_CANDIDATE: physical interpretation unverified; capture/layout evidence reported separately. PSA-RE bits 2.6. Thermal preconditioning schedule 1 enabled (Monday) Upstream default raw=0 (not necessarily valid data).";
CM_ SG_ 603 ClimatePrecondSlot1Enabled "DATABASE_CANDIDATE: physical interpretation unverified; capture/layout evidence reported separately. PSA-RE bits 2.7. Thermal preconditioning schedule 1 enabled Upstream default raw=0 (not necessarily valid data).";
CM_ SG_ 603 Unused1 "DATABASE_CANDIDATE: physical interpretation unverified; capture/layout evidence reported separately. PSA-RE bits 1.6-1.0. ";
CM_ SG_ 603 ClimatePrecondMenuAvailability "DATABASE_CANDIDATE: physical interpretation unverified; capture/layout evidence reported separately. PSA-RE bits 1.7. Information about the overall availability of the thermal preconditioning schedule menu Upstream default raw=0 (not necessarily valid data).";
CM_ BO_ 604 "DATABASE_CANDIDATE: physical interpretation unverified; capture/layout evidence reported separately. INFO-DIV CAN, 125000 bit/s; CAN ID 0x25C. PSA-RE title: ECO_DRIVING_HISTORY. Eco-driving coach trip consumption/distance and weekly history scores (Monday to Sunday). Source: https://github.com/prototux/PSA-RE/blob/67f7581e7622410efdbb29c7eda3b86982b9b450/buses/AEE2010.full/LS.INFO-DIV/25C.yml. Source sender alternatives: BSI; physical TX/gateway forwarding not verified. Observed 589 frames in info_apka.csv,info_buzeni_obc.csv,info_charging.csv,info_standby.csv,info_start_jizda.csv,infocan.csv; DLCs [8]. Unresolved alternative source layouts preserved in source JSON. ";
CM_ SG_ 604 Unused3 "DATABASE_CANDIDATE: physical interpretation unverified; capture/layout evidence reported separately. PSA-RE bits 8.6-8.0. ";
CM_ SG_ 604 EcocoachTripConsumption "DATABASE_CANDIDATE: physical interpretation unverified; capture/layout evidence reported separately. PSA-RE bits 7.7-8.7. Fuel consumption on the Eco Coaching trip Raw invalid=511; numeric DBC decoders may still scale it: check raw before use. Upstream default raw=510 (not necessarily valid data).";
CM_ SG_ 604 Unused2 "DATABASE_CANDIDATE: physical interpretation unverified; capture/layout evidence reported separately. PSA-RE bits 6.1-6.0. ";
CM_ SG_ 604 EcocoachTripDistance "DATABASE_CANDIDATE: physical interpretation unverified; capture/layout evidence reported separately. PSA-RE bits 5.7-6.2. Distance of the Eco Coaching trip Upstream default raw=16382 (not necessarily valid data).";
CM_ SG_ 604 Unused1 "DATABASE_CANDIDATE: physical interpretation unverified; capture/layout evidence reported separately. PSA-RE bits 4.3-4.0. ";
CM_ SG_ 604 EcocoachDailyScoreSun "DATABASE_CANDIDATE: physical interpretation unverified; capture/layout evidence reported separately. PSA-RE bits 4.7-4.4. Daily Eco Coaching score for Sunday Raw invalid=15; numeric DBC decoders may still scale it: check raw before use. Upstream default raw=14 (not necessarily valid data).";
CM_ SG_ 604 EcocoachDailyScoreSat "DATABASE_CANDIDATE: physical interpretation unverified; capture/layout evidence reported separately. PSA-RE bits 3.3-3.0. Daily Eco Coaching score for Saturday Raw invalid=15; numeric DBC decoders may still scale it: check raw before use. Upstream default raw=14 (not necessarily valid data).";
CM_ SG_ 604 EcocoachDailyScoreFri "DATABASE_CANDIDATE: physical interpretation unverified; capture/layout evidence reported separately. PSA-RE bits 3.7-3.4. Daily Eco Coaching score for Friday Raw invalid=15; numeric DBC decoders may still scale it: check raw before use. Upstream default raw=14 (not necessarily valid data).";
CM_ SG_ 604 EcocoachDailyScoreThu "DATABASE_CANDIDATE: physical interpretation unverified; capture/layout evidence reported separately. PSA-RE bits 2.3-2.0. Daily Eco Coaching score for Thursday Raw invalid=15; numeric DBC decoders may still scale it: check raw before use. Upstream default raw=14 (not necessarily valid data).";
CM_ SG_ 604 EcocoachDailyScoreWed "DATABASE_CANDIDATE: physical interpretation unverified; capture/layout evidence reported separately. PSA-RE bits 2.7-2.4. Daily Eco Coaching score for Wednesday Raw invalid=15; numeric DBC decoders may still scale it: check raw before use. Upstream default raw=14 (not necessarily valid data).";
CM_ SG_ 604 EcocoachDailyScoreTue "DATABASE_CANDIDATE: physical interpretation unverified; capture/layout evidence reported separately. PSA-RE bits 1.3-1.0. Daily Eco Coaching score for Tuesday Raw invalid=15; numeric DBC decoders may still scale it: check raw before use. Upstream default raw=14 (not necessarily valid data).";
CM_ SG_ 604 EcocoachDailyScoreMon "DATABASE_CANDIDATE: physical interpretation unverified; capture/layout evidence reported separately. PSA-RE bits 1.7-1.4. Daily Eco Coaching score for Monday Raw invalid=15; numeric DBC decoders may still scale it: check raw before use. Upstream default raw=14 (not necessarily valid data).";
CM_ BO_ 607 "DATABASE_CANDIDATE: physical interpretation unverified; capture/layout evidence reported separately. INFO-DIV CAN, 125000 bit/s; CAN ID 0x25F. PSA-RE title: KML_REPLY_FLOW_CONTROL. ISO-TP flow control frame for the hands-free kit reply multi-frame reply (block size, flow status, separation time). Source: https://github.com/prototux/PSA-RE/blob/67f7581e7622410efdbb29c7eda3b86982b9b450/buses/AEE2010.full/LS.INFO-DIV/25F.yml. Source sender alternatives: EMF,ICSV; physical TX/gateway forwarding not verified. WIRE ISO-TP ONLY: normal addressing candidate, maximum Classical CAN DLC 8; actual DLC may be shorter. Data includes padding. No reassembly, text, DID or application-layer decoding. Original application layouts are preserved in source JSON; do not decode them at wire offsets. ";
CM_ SG_ 607 FlowPadding5 "TRANSPORT_CANDIDATE: normal-addressing ISO-TP. PSA-RE bits 8.7-8.0. ";
CM_ SG_ 607 FirstData6 "TRANSPORT_CANDIDATE: normal-addressing ISO-TP. PSA-RE bits 8.7-8.0. ";
CM_ SG_ 607 UnknownData7 "TRANSPORT_CANDIDATE: normal-addressing ISO-TP. PSA-RE bits 8.7-8.0. ";
CM_ SG_ 607 ConsecutiveData7 "TRANSPORT_CANDIDATE: normal-addressing ISO-TP. PSA-RE bits 8.7-8.0. ";
CM_ SG_ 607 SingleData7 "TRANSPORT_CANDIDATE: normal-addressing ISO-TP. PSA-RE bits 8.7-8.0. ";
CM_ SG_ 607 FlowPadding4 "TRANSPORT_CANDIDATE: normal-addressing ISO-TP. PSA-RE bits 7.7-7.0. ";
CM_ SG_ 607 FirstData5 "TRANSPORT_CANDIDATE: normal-addressing ISO-TP. PSA-RE bits 7.7-7.0. ";
CM_ SG_ 607 UnknownData6 "TRANSPORT_CANDIDATE: normal-addressing ISO-TP. PSA-RE bits 7.7-7.0. ";
CM_ SG_ 607 ConsecutiveData6 "TRANSPORT_CANDIDATE: normal-addressing ISO-TP. PSA-RE bits 7.7-7.0. ";
CM_ SG_ 607 SingleData6 "TRANSPORT_CANDIDATE: normal-addressing ISO-TP. PSA-RE bits 7.7-7.0. ";
CM_ SG_ 607 FlowPadding3 "TRANSPORT_CANDIDATE: normal-addressing ISO-TP. PSA-RE bits 6.7-6.0. ";
CM_ SG_ 607 FirstData4 "TRANSPORT_CANDIDATE: normal-addressing ISO-TP. PSA-RE bits 6.7-6.0. ";
CM_ SG_ 607 UnknownData5 "TRANSPORT_CANDIDATE: normal-addressing ISO-TP. PSA-RE bits 6.7-6.0. ";
CM_ SG_ 607 ConsecutiveData5 "TRANSPORT_CANDIDATE: normal-addressing ISO-TP. PSA-RE bits 6.7-6.0. ";
CM_ SG_ 607 SingleData5 "TRANSPORT_CANDIDATE: normal-addressing ISO-TP. PSA-RE bits 6.7-6.0. ";
CM_ SG_ 607 FlowPadding2 "TRANSPORT_CANDIDATE: normal-addressing ISO-TP. PSA-RE bits 5.7-5.0. ";
CM_ SG_ 607 FirstData3 "TRANSPORT_CANDIDATE: normal-addressing ISO-TP. PSA-RE bits 5.7-5.0. ";
CM_ SG_ 607 UnknownData4 "TRANSPORT_CANDIDATE: normal-addressing ISO-TP. PSA-RE bits 5.7-5.0. ";
CM_ SG_ 607 ConsecutiveData4 "TRANSPORT_CANDIDATE: normal-addressing ISO-TP. PSA-RE bits 5.7-5.0. ";
CM_ SG_ 607 SingleData4 "TRANSPORT_CANDIDATE: normal-addressing ISO-TP. PSA-RE bits 5.7-5.0. ";
CM_ SG_ 607 FlowPadding1 "TRANSPORT_CANDIDATE: normal-addressing ISO-TP. PSA-RE bits 4.7-4.0. ";
CM_ SG_ 607 FirstData2 "TRANSPORT_CANDIDATE: normal-addressing ISO-TP. PSA-RE bits 4.7-4.0. ";
CM_ SG_ 607 UnknownData3 "TRANSPORT_CANDIDATE: normal-addressing ISO-TP. PSA-RE bits 4.7-4.0. ";
CM_ SG_ 607 ConsecutiveData3 "TRANSPORT_CANDIDATE: normal-addressing ISO-TP. PSA-RE bits 4.7-4.0. ";
CM_ SG_ 607 SingleData3 "TRANSPORT_CANDIDATE: normal-addressing ISO-TP. PSA-RE bits 4.7-4.0. ";
CM_ SG_ 607 FirstData1 "TRANSPORT_CANDIDATE: normal-addressing ISO-TP. PSA-RE bits 3.7-3.0. ";
CM_ SG_ 607 UnknownData2 "TRANSPORT_CANDIDATE: normal-addressing ISO-TP. PSA-RE bits 3.7-3.0. ";
CM_ SG_ 607 ConsecutiveData2 "TRANSPORT_CANDIDATE: normal-addressing ISO-TP. PSA-RE bits 3.7-3.0. ";
CM_ SG_ 607 SingleData2 "TRANSPORT_CANDIDATE: normal-addressing ISO-TP. PSA-RE bits 3.7-3.0. ";
CM_ SG_ 607 SeparationTimeRaw "TRANSPORT_CANDIDATE: normal-addressing ISO-TP. PSA-RE bits 3.7-3.0. Raw STmin code; 0xF1..0xF9 are not milliseconds.";
CM_ SG_ 607 UnknownData1 "TRANSPORT_CANDIDATE: normal-addressing ISO-TP. PSA-RE bits 2.7-2.0. ";
CM_ SG_ 607 ConsecutiveData1 "TRANSPORT_CANDIDATE: normal-addressing ISO-TP. PSA-RE bits 2.7-2.0. ";
CM_ SG_ 607 SingleData1 "TRANSPORT_CANDIDATE: normal-addressing ISO-TP. PSA-RE bits 2.7-2.0. ";
CM_ SG_ 607 BlockSize "TRANSPORT_CANDIDATE: normal-addressing ISO-TP. PSA-RE bits 2.7-2.0. ";
CM_ SG_ 607 UnknownPciLow "TRANSPORT_CANDIDATE: normal-addressing ISO-TP. PSA-RE bits 1.3-1.0. ";
CM_ SG_ 607 FlowStatus "TRANSPORT_CANDIDATE: normal-addressing ISO-TP. PSA-RE bits 1.3-1.0. ";
CM_ SG_ 607 ConsecutiveSequence "TRANSPORT_CANDIDATE: normal-addressing ISO-TP. PSA-RE bits 1.3-1.0. ";
CM_ SG_ 607 FirstFrameLength "TRANSPORT_CANDIDATE: normal-addressing ISO-TP. PSA-RE bits 1.3-2.0. 12-bit declared PDU length; not a reassembled value.";
CM_ SG_ 607 SingleFrameLength "TRANSPORT_CANDIDATE: normal-addressing ISO-TP. PSA-RE bits 1.3-1.0. Declared data length; not a validity check.";
CM_ SG_ 607 IsoTpFrameType "TRANSPORT_CANDIDATE: normal-addressing ISO-TP. PSA-RE bits 1.7-1.4. PCI high nibble; normal addressing candidate.";
CM_ BO_ 608 "DATABASE_CANDIDATE: physical interpretation unverified; capture/layout evidence reported separately. INFO-DIV CAN, 125000 bit/s; CAN ID 0x260. PSA-RE title: VEHICLE_PERSONALIZATION_STATUS_2. Personalization profile information used by the vehicle, defined by the profile message structure. Source: https://github.com/prototux/PSA-RE/blob/67f7581e7622410efdbb29c7eda3b86982b9b450/buses/AEE2010.full/LS.INFO-DIV/260.yml. Source sender alternatives: BSI; physical TX/gateway forwarding not verified. Observed 1173 frames in info_apka.csv,info_buzeni_obc.csv,info_charging.csv,info_standby.csv,info_start_jizda.csv,infocan.csv; DLCs [8]. ";
CM_ SG_ 608 AmlaItemStatus "DATABASE_CANDIDATE: physical interpretation unverified; capture/layout evidence reported separately. PSA-RE bits 8.0. AMLA function item status Upstream default raw=1 (not necessarily valid data).";
CM_ SG_ 608 AfsFunctionActive "DATABASE_CANDIDATE: physical interpretation unverified; capture/layout evidence reported separately. PSA-RE bits 8.1. Memorized activation status of the AFS function Upstream default raw=0 (not necessarily valid data).";
CM_ SG_ 608 ArsFunctionActive "DATABASE_CANDIDATE: physical interpretation unverified; capture/layout evidence reported separately. PSA-RE bits 8.2. Memorized activation status of the ARS function Upstream default raw=0 (not necessarily valid data).";
CM_ SG_ 608 IrvFunctionInhibited "DATABASE_CANDIDATE: physical interpretation unverified; capture/layout evidence reported separately. PSA-RE bits 8.3. Memorized activation status of the IRV function Upstream default raw=1 (not necessarily valid data).";
CM_ SG_ 608 Dae4wdItemModeStatus "DATABASE_CANDIDATE: physical interpretation unverified; capture/layout evidence reported separately. PSA-RE bits 8.5-8.4. DAE 4WD item mode status Upstream default raw=0 (not necessarily valid data).";
CM_ SG_ 608 DaeItemModeStatus "DATABASE_CANDIDATE: physical interpretation unverified; capture/layout evidence reported separately. PSA-RE bits 8.7-8.6. DAE item mode status Upstream default raw=0 (not necessarily valid data).";
CM_ SG_ 608 LoadedArmsAccessFunctionActive "DATABASE_CANDIDATE: physical interpretation unverified; capture/layout evidence reported separately. PSA-RE bits 7.0. Memorized activation status of the \"loaded arms access\" function Upstream default raw=0 (not necessarily valid data).";
CM_ SG_ 608 IlvItemStatus "DATABASE_CANDIDATE: physical interpretation unverified; capture/layout evidence reported separately. PSA-RE bits 7.1. ILV function item status Upstream default raw=0 (not necessarily valid data).";
CM_ SG_ 608 GrilleLightingFunctionStatus "DATABASE_CANDIDATE: physical interpretation unverified; capture/layout evidence reported separately. PSA-RE bits 7.2. Radiator grille lighting function status Upstream default raw=0 (not necessarily valid data).";
CM_ SG_ 608 CafrItemStatus "DATABASE_CANDIDATE: physical interpretation unverified; capture/layout evidence reported separately. PSA-RE bits 7.3. CAFR function item status Upstream default raw=0 (not necessarily valid data).";
CM_ SG_ 608 DriverAlertAssistFunctionActive "DATABASE_CANDIDATE: physical interpretation unverified; capture/layout evidence reported separately. PSA-RE bits 7.4. Memorized activation status of the Driver Alert Assist function Upstream default raw=0 (not necessarily valid data).";
CM_ SG_ 608 LoadedArmsLockFunctionActive "DATABASE_CANDIDATE: physical interpretation unverified; capture/layout evidence reported separately. PSA-RE bits 7.5. Memorized activation status of the \"loaded arms access\" lock function Upstream default raw=0 (not necessarily valid data).";
CM_ SG_ 608 EtsrFunctionActive "DATABASE_CANDIDATE: physical interpretation unverified; capture/layout evidence reported separately. PSA-RE bits 7.6. Memorized activation status of the ETSR function Upstream default raw=0 (not necessarily valid data).";
CM_ SG_ 608 EcsModeFunctionActive "DATABASE_CANDIDATE: physical interpretation unverified; capture/layout evidence reported separately. PSA-RE bits 7.7. Memorized activation status of the ECS mode function Upstream default raw=0 (not necessarily valid data).";
CM_ SG_ 608 ActiveUserProfile "DATABASE_CANDIDATE: physical interpretation unverified; capture/layout evidence reported separately. PSA-RE bits 6.1-6.0. Active user profile Upstream default raw=0 (not necessarily valid data).";
CM_ SG_ 608 ReverseIndexingStatus "DATABASE_CANDIDATE: physical interpretation unverified; capture/layout evidence reported separately. PSA-RE bits 6.2. Reverse gear indexing status Upstream default raw=0 (not necessarily valid data).";
CM_ SG_ 608 TpmsReinitializationStatus "DATABASE_CANDIDATE: physical interpretation unverified; capture/layout evidence reported separately. PSA-RE bits 6.3. Tyre pressure monitoring reinitialization status Upstream default raw=0 (not necessarily valid data).";
CM_ SG_ 608 CollisionRiskBrakingType "DATABASE_CANDIDATE: physical interpretation unverified; capture/layout evidence reported separately. PSA-RE bits 6.4. Type of braking on collision risk alert Upstream default raw=0 (not necessarily valid data).";
CM_ SG_ 608 ArcSensitivityLevel "DATABASE_CANDIDATE: physical interpretation unverified; capture/layout evidence reported separately. PSA-RE bits 6.6-6.5. ARC function sensitivity level Upstream default raw=2 (not necessarily valid data).";
CM_ SG_ 608 ArcFunctionActive "DATABASE_CANDIDATE: physical interpretation unverified; capture/layout evidence reported separately. PSA-RE bits 6.7. ARC function activation status Upstream default raw=0 (not necessarily valid data).";
CM_ SG_ 608 ConfigurableButtonFunction "DATABASE_CANDIDATE: physical interpretation unverified; capture/layout evidence reported separately. PSA-RE bits 5.3-5.0. Function currently assigned to the configurable key Upstream default raw=0 (not necessarily valid data).";
CM_ SG_ 608 RearFlapMotorizationFunct_177f8c "DATABASE_CANDIDATE: physical interpretation unverified; capture/layout evidence reported separately. PSA-RE bits 5.4. Rear flap motorization function status Upstream default raw=0 (not necessarily valid data).";
CM_ SG_ 608 AutomaticRearWiperInReverse "DATABASE_CANDIDATE: physical interpretation unverified; capture/layout evidence reported separately. PSA-RE bits 5.5. Memorized activation status of the automatic rear wiper in reverse gear function Upstream default raw=0 (not necessarily valid data).";
CM_ SG_ 608 BlindSpotMonitoringFeedbackType "DATABASE_CANDIDATE: physical interpretation unverified; capture/layout evidence reported separately. PSA-RE bits 5.6. Type of blind spot monitoring information feedback Upstream default raw=0 (not necessarily valid data).";
CM_ SG_ 608 ParkingAidSetup "DATABASE_CANDIDATE: physical interpretation unverified; capture/layout evidence reported separately. PSA-RE bits 5.7. Type of user feedback returned by the parking aid function Upstream default raw=0 (not necessarily valid data).";
CM_ SG_ 608 AutomaticHeadlightsSwitchingOn "DATABASE_CANDIDATE: physical interpretation unverified; capture/layout evidence reported separately. PSA-RE bits 4.0. Memorized activation status of the automatic headlights switching on function";
CM_ SG_ 608 UnlockingLightingDuration "DATABASE_CANDIDATE: physical interpretation unverified; capture/layout evidence reported separately. PSA-RE bits 4.2-4.1. Unlocking lighting duration setting Upstream default raw=0 (not necessarily valid data).";
CM_ SG_ 608 UnlockingLightingFunction "DATABASE_CANDIDATE: physical interpretation unverified; capture/layout evidence reported separately. PSA-RE bits 4.3. Memorized activation status of the unlocking lighting function Upstream default raw=0 (not necessarily valid data).";
CM_ SG_ 608 MotorwayLightingFunction "DATABASE_CANDIDATE: physical interpretation unverified; capture/layout evidence reported separately. PSA-RE bits 4.4. Memorized activation status of the motorway lighting function Upstream default raw=0 (not necessarily valid data).";
CM_ SG_ 608 FollowMeHomeDuration "DATABASE_CANDIDATE: physical interpretation unverified; capture/layout evidence reported separately. PSA-RE bits 4.6-4.5. \"Follow me Home\" escort lighting duration setting Upstream default raw=0 (not necessarily valid data).";
CM_ SG_ 608 FollowMeHome "DATABASE_CANDIDATE: physical interpretation unverified; capture/layout evidence reported separately. PSA-RE bits 4.7. Memorized activation status of the \"Follow me Home\" escort lighting function";
CM_ SG_ 608 AmbientLighting "DATABASE_CANDIDATE: physical interpretation unverified; capture/layout evidence reported separately. PSA-RE bits 3.0. Memorized activation status of the ambient lighting function";
CM_ SG_ 608 DlrFunction "DATABASE_CANDIDATE: physical interpretation unverified; capture/layout evidence reported separately. PSA-RE bits 3.1. Memorized activation status of the daytime running lights function";
CM_ SG_ 608 AdaptiveLighting "DATABASE_CANDIDATE: physical interpretation unverified; capture/layout evidence reported separately. PSA-RE bits 3.2. Memorized activation status of the adaptive lighting function";
CM_ SG_ 608 DriverGreeting "DATABASE_CANDIDATE: physical interpretation unverified; capture/layout evidence reported separately. PSA-RE bits 3.3. Driver greeting function activation status";
CM_ SG_ 608 RearOpeningsSelectivityStatus "DATABASE_CANDIDATE: physical interpretation unverified; capture/layout evidence reported separately. PSA-RE bits 3.4. Rear openings selectivity status Upstream default raw=0 (not necessarily valid data).";
CM_ SG_ 608 CabOpeningsSelectivityFun_dd2313 "DATABASE_CANDIDATE: physical interpretation unverified; capture/layout evidence reported separately. PSA-RE bits 3.5. Cab openings selectivity function status Upstream default raw=0 (not necessarily valid data).";
CM_ SG_ 608 DoorUnlockingModeOnKey "DATABASE_CANDIDATE: physical interpretation unverified; capture/layout evidence reported separately. PSA-RE bits 3.6. Openings selectivity via remote key status Upstream default raw=0 (not necessarily valid data).";
CM_ SG_ 608 AutomaticElectricParkingB_11b15b "DATABASE_CANDIDATE: physical interpretation unverified; capture/layout evidence reported separately. PSA-RE bits 3.7. Automatic electric parking brake application function status";
CM_ SG_ 608 VehicleSoundHarmony "DATABASE_CANDIDATE: physical interpretation unverified; capture/layout evidence reported separately. PSA-RE bits 2.1-2.0. Vehicle sound harmony setting Upstream default raw=0 (not necessarily valid data).";
CM_ SG_ 608 VehicleConfigurationDataValid "DATABASE_CANDIDATE: physical interpretation unverified; capture/layout evidence reported separately. PSA-RE bits 2.2. Validity of the vehicle configuration data Upstream default raw=0 (not necessarily valid data).";
CM_ SG_ 608 AmbientLightingLevel "DATABASE_CANDIDATE: physical interpretation unverified; capture/layout evidence reported separately. PSA-RE bits 2.5-2.3. Ambient lighting level Upstream default raw=3 (not necessarily valid data).";
CM_ SG_ 608 TemperatureUnit "DATABASE_CANDIDATE: physical interpretation unverified; capture/layout evidence reported separately. PSA-RE bits 2.6. Temperature unit chosen by the customer Upstream default raw=0 (not necessarily valid data).";
CM_ SG_ 608 ConfigVolumeUnit "DATABASE_CANDIDATE: physical interpretation unverified; capture/layout evidence reported separately. PSA-RE bits 2.7. Volume unit configuration (litre or gallon) Upstream default raw=0 (not necessarily valid data).";
CM_ SG_ 608 ConfigConsumptionUnit "DATABASE_CANDIDATE: physical interpretation unverified; capture/layout evidence reported separately. PSA-RE bits 1.0. Fuel consumption unit (volume per 100 distance units, or distance per volume unit) Upstream default raw=0 (not necessarily valid data).";
CM_ SG_ 608 DistanceUnit "DATABASE_CANDIDATE: physical interpretation unverified; capture/layout evidence reported separately. PSA-RE bits 1.1. Distance unit Upstream default raw=0 (not necessarily valid data).";
CM_ SG_ 608 VehicleLanguage "DATABASE_CANDIDATE: physical interpretation unverified; capture/layout evidence reported separately. PSA-RE bits 1.6-1.2. Current language used in the vehicle Upstream default raw=0 (not necessarily valid data).";
CM_ SG_ 608 UnitLanguageDataValidity "DATABASE_CANDIDATE: physical interpretation unverified; capture/layout evidence reported separately. PSA-RE bits 1.7. Validity of the speed unit information transmitted in the same frame Upstream default raw=0 (not necessarily valid data).";
CM_ BO_ 609 "DATABASE_CANDIDATE: physical interpretation unverified; capture/layout evidence reported separately. INFO-DIV CAN, 125000 bit/s; CAN ID 0x261. PSA-RE title: TRIP_SECOND_INFOS. Second saved trip data: fuel consumption, distance, duration and average speed. Source: https://github.com/prototux/PSA-RE/blob/67f7581e7622410efdbb29c7eda3b86982b9b450/buses/AEE2010.full/LS.INFO-DIV/261.yml. Source sender alternatives: BSI; physical TX/gateway forwarding not verified. Observed 586 frames in info_apka.csv,info_buzeni_obc.csv,info_charging.csv,info_standby.csv,info_start_jizda.csv,infocan.csv; DLCs [7]. ";
CM_ SG_ 609 Unused1 "DATABASE_CANDIDATE: physical interpretation unverified; capture/layout evidence reported separately. PSA-RE bits 7.6-7.0. ";
CM_ SG_ 609 LpgAverageConsumptionTrip2 "DATABASE_CANDIDATE: physical interpretation unverified; capture/layout evidence reported separately. PSA-RE bits 6.7-7.7. Average LPG consumption for trip 2 Raw invalid=511; numeric DBC decoders may still scale it: check raw before use. Upstream default raw=0 (not necessarily valid data).";
CM_ SG_ 609 MeanConsumption "DATABASE_CANDIDATE: physical interpretation unverified; capture/layout evidence reported separately. PSA-RE bits 4.7-5.0. Trip 2 average fuel consumption Raw invalid=65535; numeric DBC decoders may still scale it: check raw before use.";
CM_ SG_ 609 TotalDistance "DATABASE_CANDIDATE: physical interpretation unverified; capture/layout evidence reported separately. PSA-RE bits 2.7-3.0. Total distance of trip 2 Raw invalid=65535; numeric DBC decoders may still scale it: check raw before use.";
CM_ SG_ 609 MeanSpeed "DATABASE_CANDIDATE: physical interpretation unverified; capture/layout evidence reported separately. PSA-RE bits 1.7-1.0. Average speed of trip 2 Raw invalid=255; numeric DBC decoders may still scale it: check raw before use.";
CM_ BO_ 611 "DATABASE_CANDIDATE: physical interpretation unverified; capture/layout evidence reported separately. INFO-DIV CAN, 125000 bit/s; CAN ID 0x263. PSA-RE title: EMF_TELEPHONE_REPLY_FLOW_CONTROL. ISO-TP flow control frame for the EMF telephone reply multi-frame reply (block size, flow status, separation time). Source: https://github.com/prototux/PSA-RE/blob/67f7581e7622410efdbb29c7eda3b86982b9b450/buses/AEE2010.full/LS.INFO-DIV/263.yml. Source sender alternatives: RAD,ICSV; physical TX/gateway forwarding not verified. WIRE ISO-TP ONLY: normal addressing candidate, maximum Classical CAN DLC 8; actual DLC may be shorter. Data includes padding. No reassembly, text, DID or application-layer decoding. Original application layouts are preserved in source JSON; do not decode them at wire offsets. ";
CM_ SG_ 611 FlowPadding5 "TRANSPORT_CANDIDATE: normal-addressing ISO-TP. PSA-RE bits 8.7-8.0. ";
CM_ SG_ 611 FirstData6 "TRANSPORT_CANDIDATE: normal-addressing ISO-TP. PSA-RE bits 8.7-8.0. ";
CM_ SG_ 611 UnknownData7 "TRANSPORT_CANDIDATE: normal-addressing ISO-TP. PSA-RE bits 8.7-8.0. ";
CM_ SG_ 611 ConsecutiveData7 "TRANSPORT_CANDIDATE: normal-addressing ISO-TP. PSA-RE bits 8.7-8.0. ";
CM_ SG_ 611 SingleData7 "TRANSPORT_CANDIDATE: normal-addressing ISO-TP. PSA-RE bits 8.7-8.0. ";
CM_ SG_ 611 FlowPadding4 "TRANSPORT_CANDIDATE: normal-addressing ISO-TP. PSA-RE bits 7.7-7.0. ";
CM_ SG_ 611 FirstData5 "TRANSPORT_CANDIDATE: normal-addressing ISO-TP. PSA-RE bits 7.7-7.0. ";
CM_ SG_ 611 UnknownData6 "TRANSPORT_CANDIDATE: normal-addressing ISO-TP. PSA-RE bits 7.7-7.0. ";
CM_ SG_ 611 ConsecutiveData6 "TRANSPORT_CANDIDATE: normal-addressing ISO-TP. PSA-RE bits 7.7-7.0. ";
CM_ SG_ 611 SingleData6 "TRANSPORT_CANDIDATE: normal-addressing ISO-TP. PSA-RE bits 7.7-7.0. ";
CM_ SG_ 611 FlowPadding3 "TRANSPORT_CANDIDATE: normal-addressing ISO-TP. PSA-RE bits 6.7-6.0. ";
CM_ SG_ 611 FirstData4 "TRANSPORT_CANDIDATE: normal-addressing ISO-TP. PSA-RE bits 6.7-6.0. ";
CM_ SG_ 611 UnknownData5 "TRANSPORT_CANDIDATE: normal-addressing ISO-TP. PSA-RE bits 6.7-6.0. ";
CM_ SG_ 611 ConsecutiveData5 "TRANSPORT_CANDIDATE: normal-addressing ISO-TP. PSA-RE bits 6.7-6.0. ";
CM_ SG_ 611 SingleData5 "TRANSPORT_CANDIDATE: normal-addressing ISO-TP. PSA-RE bits 6.7-6.0. ";
CM_ SG_ 611 FlowPadding2 "TRANSPORT_CANDIDATE: normal-addressing ISO-TP. PSA-RE bits 5.7-5.0. ";
CM_ SG_ 611 FirstData3 "TRANSPORT_CANDIDATE: normal-addressing ISO-TP. PSA-RE bits 5.7-5.0. ";
CM_ SG_ 611 UnknownData4 "TRANSPORT_CANDIDATE: normal-addressing ISO-TP. PSA-RE bits 5.7-5.0. ";
CM_ SG_ 611 ConsecutiveData4 "TRANSPORT_CANDIDATE: normal-addressing ISO-TP. PSA-RE bits 5.7-5.0. ";
CM_ SG_ 611 SingleData4 "TRANSPORT_CANDIDATE: normal-addressing ISO-TP. PSA-RE bits 5.7-5.0. ";
CM_ SG_ 611 FlowPadding1 "TRANSPORT_CANDIDATE: normal-addressing ISO-TP. PSA-RE bits 4.7-4.0. ";
CM_ SG_ 611 FirstData2 "TRANSPORT_CANDIDATE: normal-addressing ISO-TP. PSA-RE bits 4.7-4.0. ";
CM_ SG_ 611 UnknownData3 "TRANSPORT_CANDIDATE: normal-addressing ISO-TP. PSA-RE bits 4.7-4.0. ";
CM_ SG_ 611 ConsecutiveData3 "TRANSPORT_CANDIDATE: normal-addressing ISO-TP. PSA-RE bits 4.7-4.0. ";
CM_ SG_ 611 SingleData3 "TRANSPORT_CANDIDATE: normal-addressing ISO-TP. PSA-RE bits 4.7-4.0. ";
CM_ SG_ 611 FirstData1 "TRANSPORT_CANDIDATE: normal-addressing ISO-TP. PSA-RE bits 3.7-3.0. ";
CM_ SG_ 611 UnknownData2 "TRANSPORT_CANDIDATE: normal-addressing ISO-TP. PSA-RE bits 3.7-3.0. ";
CM_ SG_ 611 ConsecutiveData2 "TRANSPORT_CANDIDATE: normal-addressing ISO-TP. PSA-RE bits 3.7-3.0. ";
CM_ SG_ 611 SingleData2 "TRANSPORT_CANDIDATE: normal-addressing ISO-TP. PSA-RE bits 3.7-3.0. ";
CM_ SG_ 611 SeparationTimeRaw "TRANSPORT_CANDIDATE: normal-addressing ISO-TP. PSA-RE bits 3.7-3.0. Raw STmin code; 0xF1..0xF9 are not milliseconds.";
CM_ SG_ 611 UnknownData1 "TRANSPORT_CANDIDATE: normal-addressing ISO-TP. PSA-RE bits 2.7-2.0. ";
CM_ SG_ 611 ConsecutiveData1 "TRANSPORT_CANDIDATE: normal-addressing ISO-TP. PSA-RE bits 2.7-2.0. ";
CM_ SG_ 611 SingleData1 "TRANSPORT_CANDIDATE: normal-addressing ISO-TP. PSA-RE bits 2.7-2.0. ";
CM_ SG_ 611 BlockSize "TRANSPORT_CANDIDATE: normal-addressing ISO-TP. PSA-RE bits 2.7-2.0. ";
CM_ SG_ 611 UnknownPciLow "TRANSPORT_CANDIDATE: normal-addressing ISO-TP. PSA-RE bits 1.3-1.0. ";
CM_ SG_ 611 FlowStatus "TRANSPORT_CANDIDATE: normal-addressing ISO-TP. PSA-RE bits 1.3-1.0. ";
CM_ SG_ 611 ConsecutiveSequence "TRANSPORT_CANDIDATE: normal-addressing ISO-TP. PSA-RE bits 1.3-1.0. ";
CM_ SG_ 611 FirstFrameLength "TRANSPORT_CANDIDATE: normal-addressing ISO-TP. PSA-RE bits 1.3-2.0. 12-bit declared PDU length; not a reassembled value.";
CM_ SG_ 611 SingleFrameLength "TRANSPORT_CANDIDATE: normal-addressing ISO-TP. PSA-RE bits 1.3-1.0. Declared data length; not a validity check.";
CM_ SG_ 611 IsoTpFrameType "TRANSPORT_CANDIDATE: normal-addressing ISO-TP. PSA-RE bits 1.7-1.4. PCI high nibble; normal addressing candidate.";
CM_ BO_ 612 "DATABASE_CANDIDATE: physical interpretation unverified; capture/layout evidence reported separately. INFO-DIV CAN, 125000 bit/s; CAN ID 0x264. PSA-RE title: NOX_SENSOR. Radio/media tuner frequency, station and playback timer, sent by the infotainment system. Source: https://github.com/prototux/PSA-RE/blob/67f7581e7622410efdbb29c7eda3b86982b9b450/buses/AEE2010.full/LS.INFO-DIV/264.yml. Source sender alternatives: OVIP,BTEL; physical TX/gateway forwarding not verified. ";
CM_ SG_ 612 Unused1 "DATABASE_CANDIDATE: physical interpretation unverified; capture/layout evidence reported separately. PSA-RE bits 4.0. ";
CM_ SG_ 612 TunerMemoryBank "DATABASE_CANDIDATE: physical interpretation unverified; capture/layout evidence reported separately. PSA-RE bits 4.4-4.1. Selected tuner memory bank (FM, AM, DAB). Upstream default raw=0 (not necessarily valid data).";
CM_ SG_ 612 Frequency "DATABASE_CANDIDATE: physical interpretation unverified; capture/layout evidence reported separately. PSA-RE bits 3.7-4.5. Controlling the number of steps in relation to the starting frequency Raw invalid=2047; numeric DBC decoders may still scale it: check raw before use. Upstream default raw=2047 (not necessarily valid data).";
CM_ SG_ 612 MediaPlaybackTimer "DATABASE_CANDIDATE: physical interpretation unverified; capture/layout evidence reported separately. PSA-RE bits 1.7-2.0. Media playback timer. Raw invalid=65535; numeric DBC decoders may still scale it: check raw before use. Upstream default raw=65535 (not necessarily valid data).";
CM_ BO_ 613 "DATABASE_CANDIDATE: physical interpretation unverified; capture/layout evidence reported separately. INFO-DIV CAN, 125000 bit/s; CAN ID 0x265. PSA-RE title: RADIO_RDS_STATUS. Radio RDS status: alternative frequency list validity, programme type, regional flag, traffic announcement state. Source: https://github.com/prototux/PSA-RE/blob/67f7581e7622410efdbb29c7eda3b86982b9b450/buses/AEE2010.full/LS.INFO-DIV/265.yml. Source sender alternatives: RAD,ICSV; physical TX/gateway forwarding not verified. ";
CM_ SG_ 613 MpxAvailable "DATABASE_CANDIDATE: physical interpretation unverified; capture/layout evidence reported separately. PSA-RE bits 4.1-4.0. MPX availability Upstream default raw=0 (not necessarily valid data).";
CM_ SG_ 613 PsNameAvailable "DATABASE_CANDIDATE: physical interpretation unverified; capture/layout evidence reported separately. PSA-RE bits 4.3-4.2. Availability of PS name Upstream default raw=0 (not necessarily valid data).";
CM_ SG_ 613 RdtextStatus "DATABASE_CANDIDATE: physical interpretation unverified; capture/layout evidence reported separately. PSA-RE bits 4.5-4.4. Status of RDTEXT Upstream default raw=0 (not necessarily valid data).";
CM_ SG_ 613 RdtextFunctionStatus "DATABASE_CANDIDATE: physical interpretation unverified; capture/layout evidence reported separately. PSA-RE bits 4.6. Status of the RDTEXT function Upstream default raw=0 (not necessarily valid data).";
CM_ SG_ 613 NewsFunctionStatus "DATABASE_CANDIDATE: physical interpretation unverified; capture/layout evidence reported separately. PSA-RE bits 4.7. Status of the NEWS function Upstream default raw=0 (not necessarily valid data).";
CM_ SG_ 613 NewsBroadcastStatus "DATABASE_CANDIDATE: physical interpretation unverified; capture/layout evidence reported separately. PSA-RE bits 3.2-3.0. Status of the NEWS Upstream default raw=0 (not necessarily valid data).";
CM_ SG_ 613 NewsStatus "DATABASE_CANDIDATE: physical interpretation unverified; capture/layout evidence reported separately. PSA-RE bits 3.4-3.3. Status of the NEWS Upstream default raw=0 (not necessarily valid data).";
CM_ SG_ 613 DabfmStatus "DATABASE_CANDIDATE: physical interpretation unverified; capture/layout evidence reported separately. PSA-RE bits 3.6-3.5. Status of the DABFM Upstream default raw=0 (not necessarily valid data).";
CM_ SG_ 613 DabfmFunctionStatus "DATABASE_CANDIDATE: physical interpretation unverified; capture/layout evidence reported separately. PSA-RE bits 3.7. Status of the DABFM function Upstream default raw=0 (not necessarily valid data).";
CM_ SG_ 613 PtyCurrent "DATABASE_CANDIDATE: physical interpretation unverified; capture/layout evidence reported separately. PSA-RE bits 2.7-2.0. Type of program listened to Upstream default raw=0 (not necessarily valid data).";
CM_ SG_ 613 Unused1 "DATABASE_CANDIDATE: physical interpretation unverified; capture/layout evidence reported separately. PSA-RE bits 1.0. ";
CM_ SG_ 613 TaOut "DATABASE_CANDIDATE: physical interpretation unverified; capture/layout evidence reported separately. PSA-RE bits 1.1. Playing a traffic message Upstream default raw=0 (not necessarily valid data).";
CM_ SG_ 613 TaStatus "DATABASE_CANDIDATE: physical interpretation unverified; capture/layout evidence reported separately. PSA-RE bits 1.3-1.2. Traffic Message Service available Upstream default raw=0 (not necessarily valid data).";
CM_ SG_ 613 TaActivated "DATABASE_CANDIDATE: physical interpretation unverified; capture/layout evidence reported separately. PSA-RE bits 1.4. Traffic Message Service requested Upstream default raw=0 (not necessarily valid data).";
CM_ SG_ 613 AfStatus "DATABASE_CANDIDATE: physical interpretation unverified; capture/layout evidence reported separately. PSA-RE bits 1.6-1.5. Alternative frequencies service available Upstream default raw=0 (not necessarily valid data).";
CM_ SG_ 613 AfActivated "DATABASE_CANDIDATE: physical interpretation unverified; capture/layout evidence reported separately. PSA-RE bits 1.7. Required alternative frequency services Upstream default raw=0 (not necessarily valid data).";
CM_ BO_ 615 "DATABASE_CANDIDATE: physical interpretation unverified; capture/layout evidence reported separately. INFO-DIV CAN, 125000 bit/s; CAN ID 0x267. PSA-RE title: SPEED_LIMITER_PRESET_SPEEDS. Preset speed values (up to 6) and availability information for the speed limiter. Source: https://github.com/prototux/PSA-RE/blob/67f7581e7622410efdbb29c7eda3b86982b9b450/buses/AEE2010.full/LS.INFO-DIV/267.yml. Source sender alternatives: ICSV,BSI; physical TX/gateway forwarding not verified. Observed 597 frames in info_apka.csv,info_buzeni_obc.csv,info_charging.csv,info_standby.csv,info_start_jizda.csv,infocan.csv; DLCs [7]. ";
CM_ SG_ 615 Unused1 "DATABASE_CANDIDATE: physical interpretation unverified; capture/layout evidence reported separately. PSA-RE bits 7.6-7.0. ";
CM_ SG_ 615 CruiseMenuInfoAvailability "DATABASE_CANDIDATE: physical interpretation unverified; capture/layout evidence reported separately. PSA-RE bits 7.7. Cruise control menu information availability Upstream default raw=0 (not necessarily valid data).";
CM_ SG_ 615 Stop6SpeedValue "DATABASE_CANDIDATE: physical interpretation unverified; capture/layout evidence reported separately. PSA-RE bits 6.7-6.0. Value of stop 6 speed Raw invalid=255; numeric DBC decoders may still scale it: check raw before use. Upstream default raw=0 (not necessarily valid data).";
CM_ SG_ 615 SpeedLimitZone5Speed "DATABASE_CANDIDATE: physical interpretation unverified; capture/layout evidence reported separately. PSA-RE bits 5.7-5.0. Speed limiter zone 5 speed value Upstream default raw=0 (not necessarily valid data).";
CM_ SG_ 615 SpeedLimitZone4Speed "DATABASE_CANDIDATE: physical interpretation unverified; capture/layout evidence reported separately. PSA-RE bits 4.7-4.0. Speed limiter zone 4 speed value Upstream default raw=0 (not necessarily valid data).";
CM_ SG_ 615 SpeedLimitZone3Speed "DATABASE_CANDIDATE: physical interpretation unverified; capture/layout evidence reported separately. PSA-RE bits 3.7-3.0. Speed limiter zone 3 speed value Upstream default raw=0 (not necessarily valid data).";
CM_ SG_ 615 SpeedLimitZone2Speed "DATABASE_CANDIDATE: physical interpretation unverified; capture/layout evidence reported separately. PSA-RE bits 2.7-2.0. Speed limiter zone 2 speed value Upstream default raw=0 (not necessarily valid data).";
CM_ SG_ 615 SpeedLimitZone1Speed "DATABASE_CANDIDATE: physical interpretation unverified; capture/layout evidence reported separately. PSA-RE bits 1.7-1.0. Speed limiter zone 1 speed value Upstream default raw=0 (not necessarily valid data).";
CM_ BO_ 616 "DATABASE_CANDIDATE: physical interpretation unverified; capture/layout evidence reported separately. INFO-DIV CAN, 125000 bit/s; CAN ID 0x268. PSA-RE title: ENGINE_DYNAMIC_DATA. Human-machine interface data: driver/passenger seat massage button presses, intensity, type and vehicle mode configuration. Source: https://github.com/prototux/PSA-RE/blob/67f7581e7622410efdbb29c7eda3b86982b9b450/buses/AEE2010.full/LS.INFO-DIV/268.yml. Source sender alternatives: BSI; physical TX/gateway forwarding not verified. Observed 590 frames in info_apka.csv,info_buzeni_obc.csv,info_charging.csv,info_standby.csv,info_start_jizda.csv,infocan.csv; DLCs [8]. ";
CM_ SG_ 616 AuthenticationHmiDisplayRequest "DATABASE_CANDIDATE: physical interpretation unverified; capture/layout evidence reported separately. PSA-RE bits 8.0. Authentication HMI display request Upstream default raw=0 (not necessarily valid data).";
CM_ SG_ 616 ManualModeSelectionState "DATABASE_CANDIDATE: physical interpretation unverified; capture/layout evidence reported separately. PSA-RE bits 8.1. Manual mode selection state Upstream default raw=0 (not necessarily valid data).";
CM_ SG_ 616 VehicleModeSelectorCommand "DATABASE_CANDIDATE: physical interpretation unverified; capture/layout evidence reported separately. PSA-RE bits 8.3-8.2. Vehicle mode selector command Upstream default raw=0 (not necessarily valid data).";
CM_ SG_ 616 CurrentVehicleMode "DATABASE_CANDIDATE: physical interpretation unverified; capture/layout evidence reported separately. PSA-RE bits 8.7-8.4. Current vehicle mode Upstream default raw=0 (not necessarily valid data).";
CM_ SG_ 616 VehicleModeSelectorConfiguration "DATABASE_CANDIDATE: physical interpretation unverified; capture/layout evidence reported separately. PSA-RE bits 7.3-7.0. Vehicle mode selector configuration Upstream default raw=0 (not necessarily valid data).";
CM_ SG_ 616 DriverMassageStatus "DATABASE_CANDIDATE: physical interpretation unverified; capture/layout evidence reported separately. PSA-RE bits 7.5-7.4. Driver massage status Upstream default raw=0 (not necessarily valid data).";
CM_ SG_ 616 PassengerMassageStatus "DATABASE_CANDIDATE: physical interpretation unverified; capture/layout evidence reported separately. PSA-RE bits 7.7-7.6. Passenger massage status Upstream default raw=0 (not necessarily valid data).";
CM_ SG_ 616 SmartDeviceNotification "DATABASE_CANDIDATE: physical interpretation unverified; capture/layout evidence reported separately. PSA-RE bits 6.0. Notification-display information about smart device function use Upstream default raw=0 (not necessarily valid data).";
CM_ SG_ 616 AsrConnectionStatus "DATABASE_CANDIDATE: physical interpretation unverified; capture/layout evidence reported separately. PSA-RE bits 6.2-6.1. ASR (traction control) connection/disconnection confirmation Upstream default raw=0 (not necessarily valid data).";
CM_ SG_ 616 AdblueMaxRefillVolume "DATABASE_CANDIDATE: physical interpretation unverified; capture/layout evidence reported separately. PSA-RE bits 6.7-6.3. Volume in litres that can be added to the AdBlue tank Upstream default raw=31 (not necessarily valid data).";
CM_ SG_ 616 DynamicModeHmiFeedback "DATABASE_CANDIDATE: physical interpretation unverified; capture/layout evidence reported separately. PSA-RE bits 5.1-5.0. Dynamic mode HMI feedback to display on the instrument cluster Upstream default raw=0 (not necessarily valid data).";
CM_ SG_ 616 UreaTankLevel "DATABASE_CANDIDATE: physical interpretation unverified; capture/layout evidence reported separately. PSA-RE bits 5.6-5.2. Urea tank filling level Upstream default raw=31 (not necessarily valid data).";
CM_ SG_ 616 DynamicSettingType "DATABASE_CANDIDATE: physical interpretation unverified; capture/layout evidence reported separately. PSA-RE bits 5.7. Dynamic mode setting type Upstream default raw=0 (not necessarily valid data).";
CM_ SG_ 616 DynamicModeSelectedSynthesis "DATABASE_CANDIDATE: physical interpretation unverified; capture/layout evidence reported separately. PSA-RE bits 4.1-4.0. Dynamic mode selected, combining touchscreen and physical HMI input Upstream default raw=0 (not necessarily valid data).";
CM_ SG_ 616 DriverMassageButtonStatus "DATABASE_CANDIDATE: physical interpretation unverified; capture/layout evidence reported separately. PSA-RE bits 4.2. Driver massage button press Upstream default raw=0 (not necessarily valid data).";
CM_ SG_ 616 PassengerMassageButtonStatus "DATABASE_CANDIDATE: physical interpretation unverified; capture/layout evidence reported separately. PSA-RE bits 4.3. Passenger massage button press Upstream default raw=0 (not necessarily valid data).";
CM_ SG_ 616 DriverMassageIntensityStatus "DATABASE_CANDIDATE: physical interpretation unverified; capture/layout evidence reported separately. PSA-RE bits 4.5-4.4. Driver massage intensity status Upstream default raw=1 (not necessarily valid data).";
CM_ SG_ 616 PassengerMassageIntensityStatus "DATABASE_CANDIDATE: physical interpretation unverified; capture/layout evidence reported separately. PSA-RE bits 4.7-4.6. Passenger massage intensity status Upstream default raw=1 (not necessarily valid data).";
CM_ SG_ 616 DriverMassageTypeStatus "DATABASE_CANDIDATE: physical interpretation unverified; capture/layout evidence reported separately. PSA-RE bits 3.3-3.0. Driver massage type status Upstream default raw=1 (not necessarily valid data).";
CM_ SG_ 616 PassengerMassageTypeStatus "DATABASE_CANDIDATE: physical interpretation unverified; capture/layout evidence reported separately. PSA-RE bits 3.7-3.4. Passenger massage type status Upstream default raw=1 (not necessarily valid data).";
CM_ SG_ 616 VehiclePoiDisplayRequest "DATABASE_CANDIDATE: physical interpretation unverified; capture/layout evidence reported separately. PSA-RE bits 2.3-2.0. Vehicle request to post a point of interest (POI) Upstream default raw=0 (not necessarily valid data).";
CM_ SG_ 616 IlvSpeedRobustFlag "DATABASE_CANDIDATE: physical interpretation unverified; capture/layout evidence reported separately. PSA-RE bits 2.4. Robust speed information flag (ILV) Upstream default raw=0 (not necessarily valid data).";
CM_ SG_ 616 IlvOverspeedFlag "DATABASE_CANDIDATE: physical interpretation unverified; capture/layout evidence reported separately. PSA-RE bits 2.5. Overspeed flag relative to the ILV speed-limit sign Upstream default raw=0 (not necessarily valid data).";
CM_ SG_ 616 IlvSignType "DATABASE_CANDIDATE: physical interpretation unverified; capture/layout evidence reported separately. PSA-RE bits 2.7-2.6. Road sign type (ILV) Upstream default raw=3 (not necessarily valid data).";
CM_ SG_ 616 IlvSpeedToDisplay "DATABASE_CANDIDATE: physical interpretation unverified; capture/layout evidence reported separately. PSA-RE bits 1.7-1.0. ILV speed information to display Raw invalid=255; numeric DBC decoders may still scale it: check raw before use. Upstream default raw=254 (not necessarily valid data).";
CM_ BO_ 617 "DATABASE_CANDIDATE: physical interpretation unverified; capture/layout evidence reported separately. INFO-DIV CAN, 125000 bit/s; CAN ID 0x269. PSA-RE title: NAV_EXPORT_FLOW_CONTROL_2. ISO-TP flow-control frame for the navigation export multi-frame transfer. Source: https://github.com/prototux/PSA-RE/blob/67f7581e7622410efdbb29c7eda3b86982b9b450/buses/AEE2010.full/LS.INFO-DIV/269.yml. Source sender alternatives: MATT,CMB,VTH,ICSV; physical TX/gateway forwarding not verified. WIRE ISO-TP ONLY: normal addressing candidate, maximum Classical CAN DLC 8; actual DLC may be shorter. Data includes padding. No reassembly, text, DID or application-layer decoding. Original application layouts are preserved in source JSON; do not decode them at wire offsets. ";
CM_ SG_ 617 FlowPadding5 "TRANSPORT_CANDIDATE: normal-addressing ISO-TP. PSA-RE bits 8.7-8.0. ";
CM_ SG_ 617 FirstData6 "TRANSPORT_CANDIDATE: normal-addressing ISO-TP. PSA-RE bits 8.7-8.0. ";
CM_ SG_ 617 UnknownData7 "TRANSPORT_CANDIDATE: normal-addressing ISO-TP. PSA-RE bits 8.7-8.0. ";
CM_ SG_ 617 ConsecutiveData7 "TRANSPORT_CANDIDATE: normal-addressing ISO-TP. PSA-RE bits 8.7-8.0. ";
CM_ SG_ 617 SingleData7 "TRANSPORT_CANDIDATE: normal-addressing ISO-TP. PSA-RE bits 8.7-8.0. ";
CM_ SG_ 617 FlowPadding4 "TRANSPORT_CANDIDATE: normal-addressing ISO-TP. PSA-RE bits 7.7-7.0. ";
CM_ SG_ 617 FirstData5 "TRANSPORT_CANDIDATE: normal-addressing ISO-TP. PSA-RE bits 7.7-7.0. ";
CM_ SG_ 617 UnknownData6 "TRANSPORT_CANDIDATE: normal-addressing ISO-TP. PSA-RE bits 7.7-7.0. ";
CM_ SG_ 617 ConsecutiveData6 "TRANSPORT_CANDIDATE: normal-addressing ISO-TP. PSA-RE bits 7.7-7.0. ";
CM_ SG_ 617 SingleData6 "TRANSPORT_CANDIDATE: normal-addressing ISO-TP. PSA-RE bits 7.7-7.0. ";
CM_ SG_ 617 FlowPadding3 "TRANSPORT_CANDIDATE: normal-addressing ISO-TP. PSA-RE bits 6.7-6.0. ";
CM_ SG_ 617 FirstData4 "TRANSPORT_CANDIDATE: normal-addressing ISO-TP. PSA-RE bits 6.7-6.0. ";
CM_ SG_ 617 UnknownData5 "TRANSPORT_CANDIDATE: normal-addressing ISO-TP. PSA-RE bits 6.7-6.0. ";
CM_ SG_ 617 ConsecutiveData5 "TRANSPORT_CANDIDATE: normal-addressing ISO-TP. PSA-RE bits 6.7-6.0. ";
CM_ SG_ 617 SingleData5 "TRANSPORT_CANDIDATE: normal-addressing ISO-TP. PSA-RE bits 6.7-6.0. ";
CM_ SG_ 617 FlowPadding2 "TRANSPORT_CANDIDATE: normal-addressing ISO-TP. PSA-RE bits 5.7-5.0. ";
CM_ SG_ 617 FirstData3 "TRANSPORT_CANDIDATE: normal-addressing ISO-TP. PSA-RE bits 5.7-5.0. ";
CM_ SG_ 617 UnknownData4 "TRANSPORT_CANDIDATE: normal-addressing ISO-TP. PSA-RE bits 5.7-5.0. ";
CM_ SG_ 617 ConsecutiveData4 "TRANSPORT_CANDIDATE: normal-addressing ISO-TP. PSA-RE bits 5.7-5.0. ";
CM_ SG_ 617 SingleData4 "TRANSPORT_CANDIDATE: normal-addressing ISO-TP. PSA-RE bits 5.7-5.0. ";
CM_ SG_ 617 FlowPadding1 "TRANSPORT_CANDIDATE: normal-addressing ISO-TP. PSA-RE bits 4.7-4.0. ";
CM_ SG_ 617 FirstData2 "TRANSPORT_CANDIDATE: normal-addressing ISO-TP. PSA-RE bits 4.7-4.0. ";
CM_ SG_ 617 UnknownData3 "TRANSPORT_CANDIDATE: normal-addressing ISO-TP. PSA-RE bits 4.7-4.0. ";
CM_ SG_ 617 ConsecutiveData3 "TRANSPORT_CANDIDATE: normal-addressing ISO-TP. PSA-RE bits 4.7-4.0. ";
CM_ SG_ 617 SingleData3 "TRANSPORT_CANDIDATE: normal-addressing ISO-TP. PSA-RE bits 4.7-4.0. ";
CM_ SG_ 617 FirstData1 "TRANSPORT_CANDIDATE: normal-addressing ISO-TP. PSA-RE bits 3.7-3.0. ";
CM_ SG_ 617 UnknownData2 "TRANSPORT_CANDIDATE: normal-addressing ISO-TP. PSA-RE bits 3.7-3.0. ";
CM_ SG_ 617 ConsecutiveData2 "TRANSPORT_CANDIDATE: normal-addressing ISO-TP. PSA-RE bits 3.7-3.0. ";
CM_ SG_ 617 SingleData2 "TRANSPORT_CANDIDATE: normal-addressing ISO-TP. PSA-RE bits 3.7-3.0. ";
CM_ SG_ 617 SeparationTimeRaw "TRANSPORT_CANDIDATE: normal-addressing ISO-TP. PSA-RE bits 3.7-3.0. Raw STmin code; 0xF1..0xF9 are not milliseconds.";
CM_ SG_ 617 UnknownData1 "TRANSPORT_CANDIDATE: normal-addressing ISO-TP. PSA-RE bits 2.7-2.0. ";
CM_ SG_ 617 ConsecutiveData1 "TRANSPORT_CANDIDATE: normal-addressing ISO-TP. PSA-RE bits 2.7-2.0. ";
CM_ SG_ 617 SingleData1 "TRANSPORT_CANDIDATE: normal-addressing ISO-TP. PSA-RE bits 2.7-2.0. ";
CM_ SG_ 617 BlockSize "TRANSPORT_CANDIDATE: normal-addressing ISO-TP. PSA-RE bits 2.7-2.0. ";
CM_ SG_ 617 UnknownPciLow "TRANSPORT_CANDIDATE: normal-addressing ISO-TP. PSA-RE bits 1.3-1.0. ";
CM_ SG_ 617 FlowStatus "TRANSPORT_CANDIDATE: normal-addressing ISO-TP. PSA-RE bits 1.3-1.0. ";
CM_ SG_ 617 ConsecutiveSequence "TRANSPORT_CANDIDATE: normal-addressing ISO-TP. PSA-RE bits 1.3-1.0. ";
CM_ SG_ 617 FirstFrameLength "TRANSPORT_CANDIDATE: normal-addressing ISO-TP. PSA-RE bits 1.3-2.0. 12-bit declared PDU length; not a reassembled value.";
CM_ SG_ 617 SingleFrameLength "TRANSPORT_CANDIDATE: normal-addressing ISO-TP. PSA-RE bits 1.3-1.0. Declared data length; not a validity check.";
CM_ SG_ 617 IsoTpFrameType "TRANSPORT_CANDIDATE: normal-addressing ISO-TP. PSA-RE bits 1.7-1.4. PCI high nibble; normal addressing candidate.";
CM_ BO_ 625 "DATABASE_CANDIDATE: physical interpretation unverified; capture/layout evidence reported separately. INFO-DIV CAN, 125000 bit/s; CAN ID 0x271. PSA-RE title: CD_CHANGER_REPLY_FLOW_CONTROL. ISO-TP flow control frame for the CD changer reply multi-frame reply (block size, flow status, separation time). Source: https://github.com/prototux/PSA-RE/blob/67f7581e7622410efdbb29c7eda3b86982b9b450/buses/AEE2010.full/LS.INFO-DIV/271.yml. Source sender alternatives: RAD,ICSV,BTEL,EMF,OVIP; physical TX/gateway forwarding not verified. WIRE ISO-TP ONLY: normal addressing candidate, maximum Classical CAN DLC 8; actual DLC may be shorter. Data includes padding. No reassembly, text, DID or application-layer decoding. Original application layouts are preserved in source JSON; do not decode them at wire offsets. ";
CM_ SG_ 625 FlowPadding5 "TRANSPORT_CANDIDATE: normal-addressing ISO-TP. PSA-RE bits 8.7-8.0. ";
CM_ SG_ 625 FirstData6 "TRANSPORT_CANDIDATE: normal-addressing ISO-TP. PSA-RE bits 8.7-8.0. ";
CM_ SG_ 625 UnknownData7 "TRANSPORT_CANDIDATE: normal-addressing ISO-TP. PSA-RE bits 8.7-8.0. ";
CM_ SG_ 625 ConsecutiveData7 "TRANSPORT_CANDIDATE: normal-addressing ISO-TP. PSA-RE bits 8.7-8.0. ";
CM_ SG_ 625 SingleData7 "TRANSPORT_CANDIDATE: normal-addressing ISO-TP. PSA-RE bits 8.7-8.0. ";
CM_ SG_ 625 FlowPadding4 "TRANSPORT_CANDIDATE: normal-addressing ISO-TP. PSA-RE bits 7.7-7.0. ";
CM_ SG_ 625 FirstData5 "TRANSPORT_CANDIDATE: normal-addressing ISO-TP. PSA-RE bits 7.7-7.0. ";
CM_ SG_ 625 UnknownData6 "TRANSPORT_CANDIDATE: normal-addressing ISO-TP. PSA-RE bits 7.7-7.0. ";
CM_ SG_ 625 ConsecutiveData6 "TRANSPORT_CANDIDATE: normal-addressing ISO-TP. PSA-RE bits 7.7-7.0. ";
CM_ SG_ 625 SingleData6 "TRANSPORT_CANDIDATE: normal-addressing ISO-TP. PSA-RE bits 7.7-7.0. ";
CM_ SG_ 625 FlowPadding3 "TRANSPORT_CANDIDATE: normal-addressing ISO-TP. PSA-RE bits 6.7-6.0. ";
CM_ SG_ 625 FirstData4 "TRANSPORT_CANDIDATE: normal-addressing ISO-TP. PSA-RE bits 6.7-6.0. ";
CM_ SG_ 625 UnknownData5 "TRANSPORT_CANDIDATE: normal-addressing ISO-TP. PSA-RE bits 6.7-6.0. ";
CM_ SG_ 625 ConsecutiveData5 "TRANSPORT_CANDIDATE: normal-addressing ISO-TP. PSA-RE bits 6.7-6.0. ";
CM_ SG_ 625 SingleData5 "TRANSPORT_CANDIDATE: normal-addressing ISO-TP. PSA-RE bits 6.7-6.0. ";
CM_ SG_ 625 FlowPadding2 "TRANSPORT_CANDIDATE: normal-addressing ISO-TP. PSA-RE bits 5.7-5.0. ";
CM_ SG_ 625 FirstData3 "TRANSPORT_CANDIDATE: normal-addressing ISO-TP. PSA-RE bits 5.7-5.0. ";
CM_ SG_ 625 UnknownData4 "TRANSPORT_CANDIDATE: normal-addressing ISO-TP. PSA-RE bits 5.7-5.0. ";
CM_ SG_ 625 ConsecutiveData4 "TRANSPORT_CANDIDATE: normal-addressing ISO-TP. PSA-RE bits 5.7-5.0. ";
CM_ SG_ 625 SingleData4 "TRANSPORT_CANDIDATE: normal-addressing ISO-TP. PSA-RE bits 5.7-5.0. ";
CM_ SG_ 625 FlowPadding1 "TRANSPORT_CANDIDATE: normal-addressing ISO-TP. PSA-RE bits 4.7-4.0. ";
CM_ SG_ 625 FirstData2 "TRANSPORT_CANDIDATE: normal-addressing ISO-TP. PSA-RE bits 4.7-4.0. ";
CM_ SG_ 625 UnknownData3 "TRANSPORT_CANDIDATE: normal-addressing ISO-TP. PSA-RE bits 4.7-4.0. ";
CM_ SG_ 625 ConsecutiveData3 "TRANSPORT_CANDIDATE: normal-addressing ISO-TP. PSA-RE bits 4.7-4.0. ";
CM_ SG_ 625 SingleData3 "TRANSPORT_CANDIDATE: normal-addressing ISO-TP. PSA-RE bits 4.7-4.0. ";
CM_ SG_ 625 FirstData1 "TRANSPORT_CANDIDATE: normal-addressing ISO-TP. PSA-RE bits 3.7-3.0. ";
CM_ SG_ 625 UnknownData2 "TRANSPORT_CANDIDATE: normal-addressing ISO-TP. PSA-RE bits 3.7-3.0. ";
CM_ SG_ 625 ConsecutiveData2 "TRANSPORT_CANDIDATE: normal-addressing ISO-TP. PSA-RE bits 3.7-3.0. ";
CM_ SG_ 625 SingleData2 "TRANSPORT_CANDIDATE: normal-addressing ISO-TP. PSA-RE bits 3.7-3.0. ";
CM_ SG_ 625 SeparationTimeRaw "TRANSPORT_CANDIDATE: normal-addressing ISO-TP. PSA-RE bits 3.7-3.0. Raw STmin code; 0xF1..0xF9 are not milliseconds.";
CM_ SG_ 625 UnknownData1 "TRANSPORT_CANDIDATE: normal-addressing ISO-TP. PSA-RE bits 2.7-2.0. ";
CM_ SG_ 625 ConsecutiveData1 "TRANSPORT_CANDIDATE: normal-addressing ISO-TP. PSA-RE bits 2.7-2.0. ";
CM_ SG_ 625 SingleData1 "TRANSPORT_CANDIDATE: normal-addressing ISO-TP. PSA-RE bits 2.7-2.0. ";
CM_ SG_ 625 BlockSize "TRANSPORT_CANDIDATE: normal-addressing ISO-TP. PSA-RE bits 2.7-2.0. ";
CM_ SG_ 625 UnknownPciLow "TRANSPORT_CANDIDATE: normal-addressing ISO-TP. PSA-RE bits 1.3-1.0. ";
CM_ SG_ 625 FlowStatus "TRANSPORT_CANDIDATE: normal-addressing ISO-TP. PSA-RE bits 1.3-1.0. ";
CM_ SG_ 625 ConsecutiveSequence "TRANSPORT_CANDIDATE: normal-addressing ISO-TP. PSA-RE bits 1.3-1.0. ";
CM_ SG_ 625 FirstFrameLength "TRANSPORT_CANDIDATE: normal-addressing ISO-TP. PSA-RE bits 1.3-2.0. 12-bit declared PDU length; not a reassembled value.";
CM_ SG_ 625 SingleFrameLength "TRANSPORT_CANDIDATE: normal-addressing ISO-TP. PSA-RE bits 1.3-1.0. Declared data length; not a validity check.";
CM_ SG_ 625 IsoTpFrameType "TRANSPORT_CANDIDATE: normal-addressing ISO-TP. PSA-RE bits 1.7-1.4. PCI high nibble; normal addressing candidate.";
CM_ BO_ 630 "DATABASE_CANDIDATE: physical interpretation unverified; capture/layout evidence reported separately. INFO-DIV CAN, 125000 bit/s; CAN ID 0x276. PSA-RE title: VSM_SLOW_DATA. Clock display, year, AdBlue range and display request, electrical architecture identifier, and seat/boot/rear-opening condition and selectivity status. Source: https://github.com/prototux/PSA-RE/blob/67f7581e7622410efdbb29c7eda3b86982b9b450/buses/AEE2010.full/LS.INFO-DIV/276.yml. Source sender alternatives: BSI; physical TX/gateway forwarding not verified. Observed 600 frames in info_apka.csv,info_buzeni_obc.csv,info_charging.csv,info_standby.csv,info_start_jizda.csv,infocan.csv; DLCs [8]. ";
CM_ SG_ 630 Unused5 "DATABASE_CANDIDATE: physical interpretation unverified; capture/layout evidence reported separately. PSA-RE bits 8.1-8.0. ";
CM_ SG_ 630 RearOpeningUnlockSelectiv_f38f2f "DATABASE_CANDIDATE: physical interpretation unverified; capture/layout evidence reported separately. PSA-RE bits 8.2. Status of the rear opening unlock selectivity function";
CM_ SG_ 630 DriverDoorUnlockSelectivi_40d5a3 "DATABASE_CANDIDATE: physical interpretation unverified; capture/layout evidence reported separately. PSA-RE bits 8.3. Status of the driver's door unlock selectivity function";
CM_ SG_ 630 CabinLoadZoneSelectivityStatus "DATABASE_CANDIDATE: physical interpretation unverified; capture/layout evidence reported separately. PSA-RE bits 8.4. Status of the cabin and load zone lock/unlock selectivity function";
CM_ SG_ 630 SelectivityFunctionStatus "DATABASE_CANDIDATE: physical interpretation unverified; capture/layout evidence reported separately. PSA-RE bits 8.5. Current status of the selectivity feature (driver or cabin/load zone)";
CM_ SG_ 630 RearOpeningLockStatus "DATABASE_CANDIDATE: physical interpretation unverified; capture/layout evidence reported separately. PSA-RE bits 8.6. Lock status of the vehicle's rear opening (updated at the end of locking/unlocking) Upstream default raw=1 (not necessarily valid data).";
CM_ SG_ 630 TrunkLockingState "DATABASE_CANDIDATE: physical interpretation unverified; capture/layout evidence reported separately. PSA-RE bits 8.7. Boot/trunk locking state Upstream default raw=0 (not necessarily valid data).";
CM_ SG_ 630 UreaRemainingAutonomy "DATABASE_CANDIDATE: physical interpretation unverified; capture/layout evidence reported separately. PSA-RE bits 6.5-7.0. Remaining urea (AdBlue) range Raw invalid=16383; numeric DBC decoders may still scale it: check raw before use. Upstream default raw=16382 (not necessarily valid data).";
CM_ SG_ 630 Unused4 "DATABASE_CANDIDATE: physical interpretation unverified; capture/layout evidence reported separately. PSA-RE bits 6.6. ";
CM_ SG_ 630 UreaAutonomyDisplayRequest "DATABASE_CANDIDATE: physical interpretation unverified; capture/layout evidence reported separately. PSA-RE bits 6.7. Request to display urea (AdBlue) range in the instrument cluster Upstream default raw=0 (not necessarily valid data).";
CM_ SG_ 630 TimeMinute "DATABASE_CANDIDATE: physical interpretation unverified; capture/layout evidence reported separately. PSA-RE bits 5.5-5.0. Clock minute Raw invalid=63; numeric DBC decoders may still scale it: check raw before use. Upstream default raw=62 (not necessarily valid data).";
CM_ SG_ 630 Unused3 "DATABASE_CANDIDATE: physical interpretation unverified; capture/layout evidence reported separately. PSA-RE bits 5.7-5.6. ";
CM_ SG_ 630 TimeHour "DATABASE_CANDIDATE: physical interpretation unverified; capture/layout evidence reported separately. PSA-RE bits 4.4-4.0. Clock hour Raw invalid=31; numeric DBC decoders may still scale it: check raw before use. Upstream default raw=30 (not necessarily valid data).";
CM_ SG_ 630 Unused2 "DATABASE_CANDIDATE: physical interpretation unverified; capture/layout evidence reported separately. PSA-RE bits 4.7-4.5. ";
CM_ SG_ 630 ClockDay "DATABASE_CANDIDATE: physical interpretation unverified; capture/layout evidence reported separately. PSA-RE bits 3.5-3.0. Clock day value Raw invalid=63; numeric DBC decoders may still scale it: check raw before use. Upstream default raw=62 (not necessarily valid data).";
CM_ SG_ 630 Unused1 "DATABASE_CANDIDATE: physical interpretation unverified; capture/layout evidence reported separately. PSA-RE bits 3.7-3.6. ";
CM_ SG_ 630 ClockMonth "DATABASE_CANDIDATE: physical interpretation unverified; capture/layout evidence reported separately. PSA-RE bits 2.3-2.0. Clock month value Upstream default raw=14 (not necessarily valid data).";
CM_ SG_ 630 ClockDisplayType "DATABASE_CANDIDATE: physical interpretation unverified; capture/layout evidence reported separately. PSA-RE bits 2.4. Clock display type Upstream default raw=0 (not necessarily valid data).";
CM_ SG_ 630 VehicleLockingState "DATABASE_CANDIDATE: physical interpretation unverified; capture/layout evidence reported separately. PSA-RE bits 2.7-2.5. Vehicle locking state Upstream default raw=1 (not necessarily valid data).";
CM_ SG_ 630 ClockYear "DATABASE_CANDIDATE: physical interpretation unverified; capture/layout evidence reported separately. PSA-RE bits 1.6-1.0. Clock year value Raw invalid=127; numeric DBC decoders may still scale it: check raw before use. Upstream default raw=126 (not necessarily valid data). Unresolved source alternatives: [{\"note\": \"Also observed with another scaling (factor 12000)\", \"factor\": 12000}]";
CM_ SG_ 630 ConfigDisplayTime "DATABASE_CANDIDATE: physical interpretation unverified; capture/layout evidence reported separately. PSA-RE bits 1.7. Time display format configured by the customer (12h/24h) Upstream default raw=1 (not necessarily valid data).";
CM_ BO_ 632 "DATABASE_CANDIDATE: physical interpretation unverified; capture/layout evidence reported separately. INFO-DIV CAN, 125000 bit/s; CAN ID 0x278. PSA-RE title: ENGINE_HYBRID_DYNAMIC_DATA_6. Parking camera view data: activation, obstacle presence, overlay, view type/selection, brightness and contrast. Source: https://github.com/prototux/PSA-RE/blob/67f7581e7622410efdbb29c7eda3b86982b9b450/buses/AEE2010.full/LS.INFO-DIV/278.yml. Source sender alternatives: BSI; physical TX/gateway forwarding not verified. ";
CM_ SG_ 632 RawBits20_23 "RAW. PSA-RE bits 3.3-3.0. Unmapped/padding bits, no physical interpretation.";
CM_ SG_ 632 VparkAutoModeActive "DATABASE_CANDIDATE: physical interpretation unverified; capture/layout evidence reported separately. PSA-RE bits 3.4. Automatic VPark mode active";
CM_ SG_ 632 VparkObstaclePresence "DATABASE_CANDIDATE: physical interpretation unverified; capture/layout evidence reported separately. PSA-RE bits 3.7-3.5. Parking assist obstacle presence";
CM_ SG_ 632 VparkActivationStatus "DATABASE_CANDIDATE: physical interpretation unverified; capture/layout evidence reported separately. PSA-RE bits 2.1-2.0. Automatic parking (VPark) activation status";
CM_ SG_ 632 VparkViewType "DATABASE_CANDIDATE: physical interpretation unverified; capture/layout evidence reported separately. PSA-RE bits 2.3-2.2. Parking camera view type";
CM_ SG_ 632 VparkViewState "DATABASE_CANDIDATE: physical interpretation unverified; capture/layout evidence reported separately. PSA-RE bits 2.7-2.4. Parking camera view state";
CM_ SG_ 632 VparkDisplayBrightness "DATABASE_CANDIDATE: physical interpretation unverified; capture/layout evidence reported separately. PSA-RE bits 1.3-1.0. VPark display brightness level";
CM_ SG_ 632 VparkDisplayContrast "DATABASE_CANDIDATE: physical interpretation unverified; capture/layout evidence reported separately. PSA-RE bits 1.7-1.4. VPark display contrast level";
CM_ BO_ 641 "DATABASE_CANDIDATE: physical interpretation unverified; capture/layout evidence reported separately. INFO-DIV CAN, 125000 bit/s; CAN ID 0x281. PSA-RE title: UID_TABLE_ENCRYPTED_TO_SDCM_FLOW_CONTROL. ISO-TP flow control frame for the encrypted identifier table transfer to the SDCM Source: https://github.com/prototux/PSA-RE/blob/67f7581e7622410efdbb29c7eda3b86982b9b450/buses/AEE2010.full/LS.INFO-DIV/281.yml. Source sender alternatives: SDCM; physical TX/gateway forwarding not verified. WIRE ISO-TP ONLY: normal addressing candidate, maximum Classical CAN DLC 8; actual DLC may be shorter. Data includes padding. No reassembly, text, DID or application-layer decoding. Original application layouts are preserved in source JSON; do not decode them at wire offsets. ";
CM_ SG_ 641 FlowPadding5 "TRANSPORT_CANDIDATE: normal-addressing ISO-TP. PSA-RE bits 8.7-8.0. ";
CM_ SG_ 641 FirstData6 "TRANSPORT_CANDIDATE: normal-addressing ISO-TP. PSA-RE bits 8.7-8.0. ";
CM_ SG_ 641 UnknownData7 "TRANSPORT_CANDIDATE: normal-addressing ISO-TP. PSA-RE bits 8.7-8.0. ";
CM_ SG_ 641 ConsecutiveData7 "TRANSPORT_CANDIDATE: normal-addressing ISO-TP. PSA-RE bits 8.7-8.0. ";
CM_ SG_ 641 SingleData7 "TRANSPORT_CANDIDATE: normal-addressing ISO-TP. PSA-RE bits 8.7-8.0. ";
CM_ SG_ 641 FlowPadding4 "TRANSPORT_CANDIDATE: normal-addressing ISO-TP. PSA-RE bits 7.7-7.0. ";
CM_ SG_ 641 FirstData5 "TRANSPORT_CANDIDATE: normal-addressing ISO-TP. PSA-RE bits 7.7-7.0. ";
CM_ SG_ 641 UnknownData6 "TRANSPORT_CANDIDATE: normal-addressing ISO-TP. PSA-RE bits 7.7-7.0. ";
CM_ SG_ 641 ConsecutiveData6 "TRANSPORT_CANDIDATE: normal-addressing ISO-TP. PSA-RE bits 7.7-7.0. ";
CM_ SG_ 641 SingleData6 "TRANSPORT_CANDIDATE: normal-addressing ISO-TP. PSA-RE bits 7.7-7.0. ";
CM_ SG_ 641 FlowPadding3 "TRANSPORT_CANDIDATE: normal-addressing ISO-TP. PSA-RE bits 6.7-6.0. ";
CM_ SG_ 641 FirstData4 "TRANSPORT_CANDIDATE: normal-addressing ISO-TP. PSA-RE bits 6.7-6.0. ";
CM_ SG_ 641 UnknownData5 "TRANSPORT_CANDIDATE: normal-addressing ISO-TP. PSA-RE bits 6.7-6.0. ";
CM_ SG_ 641 ConsecutiveData5 "TRANSPORT_CANDIDATE: normal-addressing ISO-TP. PSA-RE bits 6.7-6.0. ";
CM_ SG_ 641 SingleData5 "TRANSPORT_CANDIDATE: normal-addressing ISO-TP. PSA-RE bits 6.7-6.0. ";
CM_ SG_ 641 FlowPadding2 "TRANSPORT_CANDIDATE: normal-addressing ISO-TP. PSA-RE bits 5.7-5.0. ";
CM_ SG_ 641 FirstData3 "TRANSPORT_CANDIDATE: normal-addressing ISO-TP. PSA-RE bits 5.7-5.0. ";
CM_ SG_ 641 UnknownData4 "TRANSPORT_CANDIDATE: normal-addressing ISO-TP. PSA-RE bits 5.7-5.0. ";
CM_ SG_ 641 ConsecutiveData4 "TRANSPORT_CANDIDATE: normal-addressing ISO-TP. PSA-RE bits 5.7-5.0. ";
CM_ SG_ 641 SingleData4 "TRANSPORT_CANDIDATE: normal-addressing ISO-TP. PSA-RE bits 5.7-5.0. ";
CM_ SG_ 641 FlowPadding1 "TRANSPORT_CANDIDATE: normal-addressing ISO-TP. PSA-RE bits 4.7-4.0. ";
CM_ SG_ 641 FirstData2 "TRANSPORT_CANDIDATE: normal-addressing ISO-TP. PSA-RE bits 4.7-4.0. ";
CM_ SG_ 641 UnknownData3 "TRANSPORT_CANDIDATE: normal-addressing ISO-TP. PSA-RE bits 4.7-4.0. ";
CM_ SG_ 641 ConsecutiveData3 "TRANSPORT_CANDIDATE: normal-addressing ISO-TP. PSA-RE bits 4.7-4.0. ";
CM_ SG_ 641 SingleData3 "TRANSPORT_CANDIDATE: normal-addressing ISO-TP. PSA-RE bits 4.7-4.0. ";
CM_ SG_ 641 FirstData1 "TRANSPORT_CANDIDATE: normal-addressing ISO-TP. PSA-RE bits 3.7-3.0. ";
CM_ SG_ 641 UnknownData2 "TRANSPORT_CANDIDATE: normal-addressing ISO-TP. PSA-RE bits 3.7-3.0. ";
CM_ SG_ 641 ConsecutiveData2 "TRANSPORT_CANDIDATE: normal-addressing ISO-TP. PSA-RE bits 3.7-3.0. ";
CM_ SG_ 641 SingleData2 "TRANSPORT_CANDIDATE: normal-addressing ISO-TP. PSA-RE bits 3.7-3.0. ";
CM_ SG_ 641 SeparationTimeRaw "TRANSPORT_CANDIDATE: normal-addressing ISO-TP. PSA-RE bits 3.7-3.0. Raw STmin code; 0xF1..0xF9 are not milliseconds.";
CM_ SG_ 641 UnknownData1 "TRANSPORT_CANDIDATE: normal-addressing ISO-TP. PSA-RE bits 2.7-2.0. ";
CM_ SG_ 641 ConsecutiveData1 "TRANSPORT_CANDIDATE: normal-addressing ISO-TP. PSA-RE bits 2.7-2.0. ";
CM_ SG_ 641 SingleData1 "TRANSPORT_CANDIDATE: normal-addressing ISO-TP. PSA-RE bits 2.7-2.0. ";
CM_ SG_ 641 BlockSize "TRANSPORT_CANDIDATE: normal-addressing ISO-TP. PSA-RE bits 2.7-2.0. ";
CM_ SG_ 641 UnknownPciLow "TRANSPORT_CANDIDATE: normal-addressing ISO-TP. PSA-RE bits 1.3-1.0. ";
CM_ SG_ 641 FlowStatus "TRANSPORT_CANDIDATE: normal-addressing ISO-TP. PSA-RE bits 1.3-1.0. ";
CM_ SG_ 641 ConsecutiveSequence "TRANSPORT_CANDIDATE: normal-addressing ISO-TP. PSA-RE bits 1.3-1.0. ";
CM_ SG_ 641 FirstFrameLength "TRANSPORT_CANDIDATE: normal-addressing ISO-TP. PSA-RE bits 1.3-2.0. 12-bit declared PDU length; not a reassembled value.";
CM_ SG_ 641 SingleFrameLength "TRANSPORT_CANDIDATE: normal-addressing ISO-TP. PSA-RE bits 1.3-1.0. Declared data length; not a validity check.";
CM_ SG_ 641 IsoTpFrameType "TRANSPORT_CANDIDATE: normal-addressing ISO-TP. PSA-RE bits 1.7-1.4. PCI high nibble; normal addressing candidate.";
CM_ BO_ 643 "DATABASE_CANDIDATE: physical interpretation unverified; capture/layout evidence reported separately. INFO-DIV CAN, 125000 bit/s; CAN ID 0x283. PSA-RE title: ODI_DYNAMIC_DATA_MULTI_REQUEST_BUFFER. Opaque data buffer of the embedded diagnostics interface (ODI) between the telematics unit and the diagnostic tool: dynamic-data multiple request. Source: https://github.com/prototux/PSA-RE/blob/67f7581e7622410efdbb29c7eda3b86982b9b450/buses/AEE2010.full/LS.INFO-DIV/283.yml. Source sender alternatives: BTEL; physical TX/gateway forwarding not verified. ";
CM_ SG_ 643 OdiDynDataMultiRequestCen_7bee23 "DATABASE_CANDIDATE: physical interpretation unverified; capture/layout evidence reported separately. PSA-RE bits 1.7-8.0. Open Display Interface (ODI) dynamic data multi-request buffer for the center stack display";
CM_ BO_ 660 "DATABASE_CANDIDATE: physical interpretation unverified; capture/layout evidence reported separately. INFO-DIV CAN, 125000 bit/s; CAN ID 0x294. PSA-RE title: TRACTION_BATTERY_DYNAMIC_DATA_4. Status of the horn, turn lights, lock/unlock and immobiliser after a remote-control action. Source: https://github.com/prototux/PSA-RE/blob/67f7581e7622410efdbb29c7eda3b86982b9b450/buses/AEE2010.full/LS.INFO-DIV/294.yml. Source sender alternatives: BSI; physical TX/gateway forwarding not verified. WIRE ISO-TP ONLY: normal addressing candidate, maximum Classical CAN DLC 8; actual DLC may be shorter. Data includes padding. No reassembly, text, DID or application-layer decoding. Original application layouts are preserved in source JSON; do not decode them at wire offsets. ";
CM_ SG_ 660 FlowPadding5 "TRANSPORT_CANDIDATE: normal-addressing ISO-TP. PSA-RE bits 8.7-8.0. ";
CM_ SG_ 660 FirstData6 "TRANSPORT_CANDIDATE: normal-addressing ISO-TP. PSA-RE bits 8.7-8.0. ";
CM_ SG_ 660 UnknownData7 "TRANSPORT_CANDIDATE: normal-addressing ISO-TP. PSA-RE bits 8.7-8.0. ";
CM_ SG_ 660 ConsecutiveData7 "TRANSPORT_CANDIDATE: normal-addressing ISO-TP. PSA-RE bits 8.7-8.0. ";
CM_ SG_ 660 SingleData7 "TRANSPORT_CANDIDATE: normal-addressing ISO-TP. PSA-RE bits 8.7-8.0. ";
CM_ SG_ 660 FlowPadding4 "TRANSPORT_CANDIDATE: normal-addressing ISO-TP. PSA-RE bits 7.7-7.0. ";
CM_ SG_ 660 FirstData5 "TRANSPORT_CANDIDATE: normal-addressing ISO-TP. PSA-RE bits 7.7-7.0. ";
CM_ SG_ 660 UnknownData6 "TRANSPORT_CANDIDATE: normal-addressing ISO-TP. PSA-RE bits 7.7-7.0. ";
CM_ SG_ 660 ConsecutiveData6 "TRANSPORT_CANDIDATE: normal-addressing ISO-TP. PSA-RE bits 7.7-7.0. ";
CM_ SG_ 660 SingleData6 "TRANSPORT_CANDIDATE: normal-addressing ISO-TP. PSA-RE bits 7.7-7.0. ";
CM_ SG_ 660 FlowPadding3 "TRANSPORT_CANDIDATE: normal-addressing ISO-TP. PSA-RE bits 6.7-6.0. ";
CM_ SG_ 660 FirstData4 "TRANSPORT_CANDIDATE: normal-addressing ISO-TP. PSA-RE bits 6.7-6.0. ";
CM_ SG_ 660 UnknownData5 "TRANSPORT_CANDIDATE: normal-addressing ISO-TP. PSA-RE bits 6.7-6.0. ";
CM_ SG_ 660 ConsecutiveData5 "TRANSPORT_CANDIDATE: normal-addressing ISO-TP. PSA-RE bits 6.7-6.0. ";
CM_ SG_ 660 SingleData5 "TRANSPORT_CANDIDATE: normal-addressing ISO-TP. PSA-RE bits 6.7-6.0. ";
CM_ SG_ 660 FlowPadding2 "TRANSPORT_CANDIDATE: normal-addressing ISO-TP. PSA-RE bits 5.7-5.0. ";
CM_ SG_ 660 FirstData3 "TRANSPORT_CANDIDATE: normal-addressing ISO-TP. PSA-RE bits 5.7-5.0. ";
CM_ SG_ 660 UnknownData4 "TRANSPORT_CANDIDATE: normal-addressing ISO-TP. PSA-RE bits 5.7-5.0. ";
CM_ SG_ 660 ConsecutiveData4 "TRANSPORT_CANDIDATE: normal-addressing ISO-TP. PSA-RE bits 5.7-5.0. ";
CM_ SG_ 660 SingleData4 "TRANSPORT_CANDIDATE: normal-addressing ISO-TP. PSA-RE bits 5.7-5.0. ";
CM_ SG_ 660 FlowPadding1 "TRANSPORT_CANDIDATE: normal-addressing ISO-TP. PSA-RE bits 4.7-4.0. ";
CM_ SG_ 660 FirstData2 "TRANSPORT_CANDIDATE: normal-addressing ISO-TP. PSA-RE bits 4.7-4.0. ";
CM_ SG_ 660 UnknownData3 "TRANSPORT_CANDIDATE: normal-addressing ISO-TP. PSA-RE bits 4.7-4.0. ";
CM_ SG_ 660 ConsecutiveData3 "TRANSPORT_CANDIDATE: normal-addressing ISO-TP. PSA-RE bits 4.7-4.0. ";
CM_ SG_ 660 SingleData3 "TRANSPORT_CANDIDATE: normal-addressing ISO-TP. PSA-RE bits 4.7-4.0. ";
CM_ SG_ 660 FirstData1 "TRANSPORT_CANDIDATE: normal-addressing ISO-TP. PSA-RE bits 3.7-3.0. ";
CM_ SG_ 660 UnknownData2 "TRANSPORT_CANDIDATE: normal-addressing ISO-TP. PSA-RE bits 3.7-3.0. ";
CM_ SG_ 660 ConsecutiveData2 "TRANSPORT_CANDIDATE: normal-addressing ISO-TP. PSA-RE bits 3.7-3.0. ";
CM_ SG_ 660 SingleData2 "TRANSPORT_CANDIDATE: normal-addressing ISO-TP. PSA-RE bits 3.7-3.0. ";
CM_ SG_ 660 SeparationTimeRaw "TRANSPORT_CANDIDATE: normal-addressing ISO-TP. PSA-RE bits 3.7-3.0. Raw STmin code; 0xF1..0xF9 are not milliseconds.";
CM_ SG_ 660 UnknownData1 "TRANSPORT_CANDIDATE: normal-addressing ISO-TP. PSA-RE bits 2.7-2.0. ";
CM_ SG_ 660 ConsecutiveData1 "TRANSPORT_CANDIDATE: normal-addressing ISO-TP. PSA-RE bits 2.7-2.0. ";
CM_ SG_ 660 SingleData1 "TRANSPORT_CANDIDATE: normal-addressing ISO-TP. PSA-RE bits 2.7-2.0. ";
CM_ SG_ 660 BlockSize "TRANSPORT_CANDIDATE: normal-addressing ISO-TP. PSA-RE bits 2.7-2.0. ";
CM_ SG_ 660 UnknownPciLow "TRANSPORT_CANDIDATE: normal-addressing ISO-TP. PSA-RE bits 1.3-1.0. ";
CM_ SG_ 660 FlowStatus "TRANSPORT_CANDIDATE: normal-addressing ISO-TP. PSA-RE bits 1.3-1.0. ";
CM_ SG_ 660 ConsecutiveSequence "TRANSPORT_CANDIDATE: normal-addressing ISO-TP. PSA-RE bits 1.3-1.0. ";
CM_ SG_ 660 FirstFrameLength "TRANSPORT_CANDIDATE: normal-addressing ISO-TP. PSA-RE bits 1.3-2.0. 12-bit declared PDU length; not a reassembled value.";
CM_ SG_ 660 SingleFrameLength "TRANSPORT_CANDIDATE: normal-addressing ISO-TP. PSA-RE bits 1.3-1.0. Declared data length; not a validity check.";
CM_ SG_ 660 IsoTpFrameType "TRANSPORT_CANDIDATE: normal-addressing ISO-TP. PSA-RE bits 1.7-1.4. PCI high nibble; normal addressing candidate.";
CM_ BO_ 663 "DATABASE_CANDIDATE: physical interpretation unverified; capture/layout evidence reported separately. INFO-DIV CAN, 125000 bit/s; CAN ID 0x297. PSA-RE title: LED_DRIVER_RIGHT_LEVELLING_POSITION. Head-up display status: memory and recall, mirror movement, displayed speed. Source: https://github.com/prototux/PSA-RE/blob/67f7581e7622410efdbb29c7eda3b86982b9b450/buses/AEE2010.full/LS.INFO-DIV/297.yml. Source sender alternatives: VTH,CMB; physical TX/gateway forwarding not verified. ";
CM_ SG_ 663 SpeedDisplayedOnHud "DATABASE_CANDIDATE: physical interpretation unverified; capture/layout evidence reported separately. PSA-RE bits 2.7-2.0. Speed displayed in the HUD Raw invalid=255; numeric DBC decoders may still scale it: check raw before use. Upstream default raw=0 (not necessarily valid data).";
CM_ SG_ 663 HudScreenManualMovement "DATABASE_CANDIDATE: physical interpretation unverified; capture/layout evidence reported separately. PSA-RE bits 1.0. Mirror in manual movement Upstream default raw=0 (not necessarily valid data).";
CM_ SG_ 663 HudMemoryRecall "DATABASE_CANDIDATE: physical interpretation unverified; capture/layout evidence reported separately. PSA-RE bits 1.1. HUD memory recall Upstream default raw=0 (not necessarily valid data).";
CM_ SG_ 663 HudMemoryStatus "DATABASE_CANDIDATE: physical interpretation unverified; capture/layout evidence reported separately. PSA-RE bits 1.2. Storing in progress Upstream default raw=0 (not necessarily valid data).";
CM_ SG_ 663 HudActivationStatus "DATABASE_CANDIDATE: physical interpretation unverified; capture/layout evidence reported separately. PSA-RE bits 1.4-1.3. HUD activation status Upstream default raw=0 (not necessarily valid data).";
CM_ SG_ 663 MediaDisplayFault "DATABASE_CANDIDATE: physical interpretation unverified; capture/layout evidence reported separately. PSA-RE bits 1.5. Media display fault Upstream default raw=0 (not necessarily valid data).";
CM_ SG_ 663 Unused1 "DATABASE_CANDIDATE: physical interpretation unverified; capture/layout evidence reported separately. PSA-RE bits 1.7-1.6. ";
CM_ BO_ 667 "DATABASE_CANDIDATE: physical interpretation unverified; capture/layout evidence reported separately. INFO-DIV CAN, 125000 bit/s; CAN ID 0x29B. PSA-RE title: CLIMATE_PRECOND_PROGRAM_SCREEN_2. Climate preconditioning weekly programming screen requests (part 2). Source: https://github.com/prototux/PSA-RE/blob/67f7581e7622410efdbb29c7eda3b86982b9b450/buses/AEE2010.full/LS.INFO-DIV/29B.yml. Source sender alternatives: BTEL,MDS,OVIP; physical TX/gateway forwarding not verified. ";
CM_ SG_ 667 ClimatePrecondSlot4StartTime "DATABASE_CANDIDATE: physical interpretation unverified; capture/layout evidence reported separately. PSA-RE bits 6.2-7.0. Start time of thermal preconditioning schedule 4 Upstream default raw=0 (not necessarily valid data).";
CM_ SG_ 667 Unused3 "DATABASE_CANDIDATE: physical interpretation unverified; capture/layout evidence reported separately. PSA-RE bits 6.7-6.3. ";
CM_ SG_ 667 ClimatePrecondSundaySlot4Enabled "DATABASE_CANDIDATE: physical interpretation unverified; capture/layout evidence reported separately. PSA-RE bits 5.0. Thermal preconditioning schedule 4 enabled (Sunday) Upstream default raw=0 (not necessarily valid data).";
CM_ SG_ 667 ClimatePrecondSaturdaySlo_419d2b "DATABASE_CANDIDATE: physical interpretation unverified; capture/layout evidence reported separately. PSA-RE bits 5.1. Thermal preconditioning schedule 4 enabled (Saturday) Upstream default raw=0 (not necessarily valid data).";
CM_ SG_ 667 ClimatePrecondFridaySlot4Enabled "DATABASE_CANDIDATE: physical interpretation unverified; capture/layout evidence reported separately. PSA-RE bits 5.2. Thermal preconditioning schedule 4 enabled (Friday) Upstream default raw=0 (not necessarily valid data).";
CM_ SG_ 667 ClimatePrecondThursdaySlo_d85853 "DATABASE_CANDIDATE: physical interpretation unverified; capture/layout evidence reported separately. PSA-RE bits 5.3. Thermal preconditioning schedule 4 enabled (Thursday) Upstream default raw=0 (not necessarily valid data).";
CM_ SG_ 667 ClimatePrecondWednesdaySl_c2d848 "DATABASE_CANDIDATE: physical interpretation unverified; capture/layout evidence reported separately. PSA-RE bits 5.4. Thermal preconditioning schedule 4 enabled (Wednesday) Upstream default raw=0 (not necessarily valid data).";
CM_ SG_ 667 ClimatePrecondTuesdaySlot_ddb9f8 "DATABASE_CANDIDATE: physical interpretation unverified; capture/layout evidence reported separately. PSA-RE bits 5.5. Thermal preconditioning schedule 4 enabled (Tuesday) Upstream default raw=0 (not necessarily valid data).";
CM_ SG_ 667 ClimatePrecondMondaySlot4Enabled "DATABASE_CANDIDATE: physical interpretation unverified; capture/layout evidence reported separately. PSA-RE bits 5.6. Thermal preconditioning schedule 4 enabled (Monday) Upstream default raw=0 (not necessarily valid data).";
CM_ SG_ 667 ClimatePrecondSlot4Enabled "DATABASE_CANDIDATE: physical interpretation unverified; capture/layout evidence reported separately. PSA-RE bits 5.7. Thermal preconditioning schedule 4 enabled Upstream default raw=0 (not necessarily valid data).";
CM_ SG_ 667 ClimatePrecondSlot3StartTime "DATABASE_CANDIDATE: physical interpretation unverified; capture/layout evidence reported separately. PSA-RE bits 3.2-4.0. Start time of thermal preconditioning schedule 3 Upstream default raw=0 (not necessarily valid data).";
CM_ SG_ 667 Unused2 "DATABASE_CANDIDATE: physical interpretation unverified; capture/layout evidence reported separately. PSA-RE bits 3.7-3.3. ";
CM_ SG_ 667 ClimatePrecondSundaySlot3Enabled "DATABASE_CANDIDATE: physical interpretation unverified; capture/layout evidence reported separately. PSA-RE bits 2.0. Thermal preconditioning schedule 3 enabled (Sunday) Upstream default raw=0 (not necessarily valid data).";
CM_ SG_ 667 ClimatePrecondSaturdaySlo_def41f "DATABASE_CANDIDATE: physical interpretation unverified; capture/layout evidence reported separately. PSA-RE bits 2.1. Thermal preconditioning schedule 3 enabled (Saturday) Upstream default raw=0 (not necessarily valid data).";
CM_ SG_ 667 ClimatePrecondFridaySlot3Enabled "DATABASE_CANDIDATE: physical interpretation unverified; capture/layout evidence reported separately. PSA-RE bits 2.2. Thermal preconditioning schedule 3 enabled (Friday) Upstream default raw=0 (not necessarily valid data).";
CM_ SG_ 667 ClimatePrecondThursdaySlo_f9fbde "DATABASE_CANDIDATE: physical interpretation unverified; capture/layout evidence reported separately. PSA-RE bits 2.3. Thermal preconditioning schedule 3 enabled (Thursday) Upstream default raw=0 (not necessarily valid data).";
CM_ SG_ 667 ClimatePrecondWednesdaySl_dfe9f3 "DATABASE_CANDIDATE: physical interpretation unverified; capture/layout evidence reported separately. PSA-RE bits 2.4. Thermal preconditioning schedule 3 enabled (Wednesday) Upstream default raw=0 (not necessarily valid data).";
CM_ SG_ 667 ClimatePrecondTuesdaySlot_f7a007 "DATABASE_CANDIDATE: physical interpretation unverified; capture/layout evidence reported separately. PSA-RE bits 2.5. Thermal preconditioning schedule 3 enabled (Tuesday) Upstream default raw=0 (not necessarily valid data).";
CM_ SG_ 667 ClimatePrecondMondaySlot3Enabled "DATABASE_CANDIDATE: physical interpretation unverified; capture/layout evidence reported separately. PSA-RE bits 2.6. Thermal preconditioning schedule 3 enabled (Monday) Upstream default raw=0 (not necessarily valid data).";
CM_ SG_ 667 ClimatePrecondSlot3Enabled "DATABASE_CANDIDATE: physical interpretation unverified; capture/layout evidence reported separately. PSA-RE bits 2.7. Thermal preconditioning schedule 3 enabled Upstream default raw=0 (not necessarily valid data).";
CM_ SG_ 667 Unused1 "DATABASE_CANDIDATE: physical interpretation unverified; capture/layout evidence reported separately. PSA-RE bits 1.7-1.0. ";
CM_ BO_ 671 "DATABASE_CANDIDATE: physical interpretation unverified; capture/layout evidence reported separately. INFO-DIV CAN, 125000 bit/s; CAN ID 0x29F. PSA-RE title: KML_TELEPHONE_REPLY_FLOW_CONTROL. ISO-TP flow control frame for the hands-free kit telephone reply multi-frame reply (block size, flow status, separation time). Source: https://github.com/prototux/PSA-RE/blob/67f7581e7622410efdbb29c7eda3b86982b9b450/buses/AEE2010.full/LS.INFO-DIV/29F.yml. Source sender alternatives: EMF,ICSV; physical TX/gateway forwarding not verified. WIRE ISO-TP ONLY: normal addressing candidate, maximum Classical CAN DLC 8; actual DLC may be shorter. Data includes padding. No reassembly, text, DID or application-layer decoding. Original application layouts are preserved in source JSON; do not decode them at wire offsets. ";
CM_ SG_ 671 FlowPadding5 "TRANSPORT_CANDIDATE: normal-addressing ISO-TP. PSA-RE bits 8.7-8.0. ";
CM_ SG_ 671 FirstData6 "TRANSPORT_CANDIDATE: normal-addressing ISO-TP. PSA-RE bits 8.7-8.0. ";
CM_ SG_ 671 UnknownData7 "TRANSPORT_CANDIDATE: normal-addressing ISO-TP. PSA-RE bits 8.7-8.0. ";
CM_ SG_ 671 ConsecutiveData7 "TRANSPORT_CANDIDATE: normal-addressing ISO-TP. PSA-RE bits 8.7-8.0. ";
CM_ SG_ 671 SingleData7 "TRANSPORT_CANDIDATE: normal-addressing ISO-TP. PSA-RE bits 8.7-8.0. ";
CM_ SG_ 671 FlowPadding4 "TRANSPORT_CANDIDATE: normal-addressing ISO-TP. PSA-RE bits 7.7-7.0. ";
CM_ SG_ 671 FirstData5 "TRANSPORT_CANDIDATE: normal-addressing ISO-TP. PSA-RE bits 7.7-7.0. ";
CM_ SG_ 671 UnknownData6 "TRANSPORT_CANDIDATE: normal-addressing ISO-TP. PSA-RE bits 7.7-7.0. ";
CM_ SG_ 671 ConsecutiveData6 "TRANSPORT_CANDIDATE: normal-addressing ISO-TP. PSA-RE bits 7.7-7.0. ";
CM_ SG_ 671 SingleData6 "TRANSPORT_CANDIDATE: normal-addressing ISO-TP. PSA-RE bits 7.7-7.0. ";
CM_ SG_ 671 FlowPadding3 "TRANSPORT_CANDIDATE: normal-addressing ISO-TP. PSA-RE bits 6.7-6.0. ";
CM_ SG_ 671 FirstData4 "TRANSPORT_CANDIDATE: normal-addressing ISO-TP. PSA-RE bits 6.7-6.0. ";
CM_ SG_ 671 UnknownData5 "TRANSPORT_CANDIDATE: normal-addressing ISO-TP. PSA-RE bits 6.7-6.0. ";
CM_ SG_ 671 ConsecutiveData5 "TRANSPORT_CANDIDATE: normal-addressing ISO-TP. PSA-RE bits 6.7-6.0. ";
CM_ SG_ 671 SingleData5 "TRANSPORT_CANDIDATE: normal-addressing ISO-TP. PSA-RE bits 6.7-6.0. ";
CM_ SG_ 671 FlowPadding2 "TRANSPORT_CANDIDATE: normal-addressing ISO-TP. PSA-RE bits 5.7-5.0. ";
CM_ SG_ 671 FirstData3 "TRANSPORT_CANDIDATE: normal-addressing ISO-TP. PSA-RE bits 5.7-5.0. ";
CM_ SG_ 671 UnknownData4 "TRANSPORT_CANDIDATE: normal-addressing ISO-TP. PSA-RE bits 5.7-5.0. ";
CM_ SG_ 671 ConsecutiveData4 "TRANSPORT_CANDIDATE: normal-addressing ISO-TP. PSA-RE bits 5.7-5.0. ";
CM_ SG_ 671 SingleData4 "TRANSPORT_CANDIDATE: normal-addressing ISO-TP. PSA-RE bits 5.7-5.0. ";
CM_ SG_ 671 FlowPadding1 "TRANSPORT_CANDIDATE: normal-addressing ISO-TP. PSA-RE bits 4.7-4.0. ";
CM_ SG_ 671 FirstData2 "TRANSPORT_CANDIDATE: normal-addressing ISO-TP. PSA-RE bits 4.7-4.0. ";
CM_ SG_ 671 UnknownData3 "TRANSPORT_CANDIDATE: normal-addressing ISO-TP. PSA-RE bits 4.7-4.0. ";
CM_ SG_ 671 ConsecutiveData3 "TRANSPORT_CANDIDATE: normal-addressing ISO-TP. PSA-RE bits 4.7-4.0. ";
CM_ SG_ 671 SingleData3 "TRANSPORT_CANDIDATE: normal-addressing ISO-TP. PSA-RE bits 4.7-4.0. ";
CM_ SG_ 671 FirstData1 "TRANSPORT_CANDIDATE: normal-addressing ISO-TP. PSA-RE bits 3.7-3.0. ";
CM_ SG_ 671 UnknownData2 "TRANSPORT_CANDIDATE: normal-addressing ISO-TP. PSA-RE bits 3.7-3.0. ";
CM_ SG_ 671 ConsecutiveData2 "TRANSPORT_CANDIDATE: normal-addressing ISO-TP. PSA-RE bits 3.7-3.0. ";
CM_ SG_ 671 SingleData2 "TRANSPORT_CANDIDATE: normal-addressing ISO-TP. PSA-RE bits 3.7-3.0. ";
CM_ SG_ 671 SeparationTimeRaw "TRANSPORT_CANDIDATE: normal-addressing ISO-TP. PSA-RE bits 3.7-3.0. Raw STmin code; 0xF1..0xF9 are not milliseconds.";
CM_ SG_ 671 UnknownData1 "TRANSPORT_CANDIDATE: normal-addressing ISO-TP. PSA-RE bits 2.7-2.0. ";
CM_ SG_ 671 ConsecutiveData1 "TRANSPORT_CANDIDATE: normal-addressing ISO-TP. PSA-RE bits 2.7-2.0. ";
CM_ SG_ 671 SingleData1 "TRANSPORT_CANDIDATE: normal-addressing ISO-TP. PSA-RE bits 2.7-2.0. ";
CM_ SG_ 671 BlockSize "TRANSPORT_CANDIDATE: normal-addressing ISO-TP. PSA-RE bits 2.7-2.0. ";
CM_ SG_ 671 UnknownPciLow "TRANSPORT_CANDIDATE: normal-addressing ISO-TP. PSA-RE bits 1.3-1.0. ";
CM_ SG_ 671 FlowStatus "TRANSPORT_CANDIDATE: normal-addressing ISO-TP. PSA-RE bits 1.3-1.0. ";
CM_ SG_ 671 ConsecutiveSequence "TRANSPORT_CANDIDATE: normal-addressing ISO-TP. PSA-RE bits 1.3-1.0. ";
CM_ SG_ 671 FirstFrameLength "TRANSPORT_CANDIDATE: normal-addressing ISO-TP. PSA-RE bits 1.3-2.0. 12-bit declared PDU length; not a reassembled value.";
CM_ SG_ 671 SingleFrameLength "TRANSPORT_CANDIDATE: normal-addressing ISO-TP. PSA-RE bits 1.3-1.0. Declared data length; not a validity check.";
CM_ SG_ 671 IsoTpFrameType "TRANSPORT_CANDIDATE: normal-addressing ISO-TP. PSA-RE bits 1.7-1.4. PCI high nibble; normal addressing candidate.";
CM_ BO_ 672 "DATABASE_CANDIDATE: physical interpretation unverified; capture/layout evidence reported separately. INFO-DIV CAN, 125000 bit/s; CAN ID 0x2A0. PSA-RE title: CONFIG_REQUEST. Configuration request frame: programming, personalisation and profile activation requests Source: https://github.com/prototux/PSA-RE/blob/67f7581e7622410efdbb29c7eda3b86982b9b450/buses/AEE2010.full/LS.INFO-DIV/2A0.yml. Source sender alternatives: ICSV,BSI; physical TX/gateway forwarding not verified. ";
CM_ SG_ 672 Unused1 "DATABASE_CANDIDATE: physical interpretation unverified; capture/layout evidence reported separately. PSA-RE bits 1.2-1.0. ";
CM_ SG_ 672 FunctionStatusAccessRequest "DATABASE_CANDIDATE: physical interpretation unverified; capture/layout evidence reported separately. PSA-RE bits 1.3. Request for access to functions status. Upstream default raw=0 (not necessarily valid data).";
CM_ SG_ 672 AlertLogAccessRequest "DATABASE_CANDIDATE: physical interpretation unverified; capture/layout evidence reported separately. PSA-RE bits 1.4. Request for access to the alert log (JDA). Upstream default raw=0 (not necessarily valid data).";
CM_ SG_ 672 CustomizationMenuAccessRequest "DATABASE_CANDIDATE: physical interpretation unverified; capture/layout evidence reported separately. PSA-RE bits 1.5. Request for access to the first page of the customization menu. Upstream default raw=0 (not necessarily valid data).";
CM_ SG_ 672 ActiveProfileScreenAccessRequest "DATABASE_CANDIDATE: physical interpretation unverified; capture/layout evidence reported separately. PSA-RE bits 1.6. Request for access to the active profile selection screen. Upstream default raw=0 (not necessarily valid data).";
CM_ SG_ 672 ConfigurableKeyProgrammin_af2e87 "DATABASE_CANDIDATE: physical interpretation unverified; capture/layout evidence reported separately. PSA-RE bits 1.7. Request for configurable key programming. Upstream default raw=0 (not necessarily valid data).";
CM_ BO_ 673 "DATABASE_CANDIDATE: physical interpretation unverified; capture/layout evidence reported separately. INFO-DIV CAN, 125000 bit/s; CAN ID 0x2A1. PSA-RE title: TRIP_FIRST_INFOS. First saved trip data: fuel consumption, distance, duration and average speed. Source: https://github.com/prototux/PSA-RE/blob/67f7581e7622410efdbb29c7eda3b86982b9b450/buses/AEE2010.full/LS.INFO-DIV/2A1.yml. Source sender alternatives: BSI; physical TX/gateway forwarding not verified. Observed 586 frames in info_apka.csv,info_buzeni_obc.csv,info_charging.csv,info_standby.csv,info_start_jizda.csv,infocan.csv; DLCs [7]. ";
CM_ SG_ 673 Unused1 "DATABASE_CANDIDATE: physical interpretation unverified; capture/layout evidence reported separately. PSA-RE bits 7.6-7.0. ";
CM_ SG_ 673 LpgAverageConsumptionTrip1 "DATABASE_CANDIDATE: physical interpretation unverified; capture/layout evidence reported separately. PSA-RE bits 6.7-7.7. Average LPG consumption for trip 1 Raw invalid=511; numeric DBC decoders may still scale it: check raw before use. Upstream default raw=0 (not necessarily valid data).";
CM_ SG_ 673 MeanConsumption "DATABASE_CANDIDATE: physical interpretation unverified; capture/layout evidence reported separately. PSA-RE bits 4.7-5.0. Trip 1 average fuel consumption Raw invalid=65535; numeric DBC decoders may still scale it: check raw before use.";
CM_ SG_ 673 TotalDistance "DATABASE_CANDIDATE: physical interpretation unverified; capture/layout evidence reported separately. PSA-RE bits 2.7-3.0. Total distance of trip 1 Raw invalid=65535; numeric DBC decoders may still scale it: check raw before use.";
CM_ SG_ 673 MeanSpeed "DATABASE_CANDIDATE: physical interpretation unverified; capture/layout evidence reported separately. PSA-RE bits 1.7-1.0. Average speed of trip 1 Raw invalid=255; numeric DBC decoders may still scale it: check raw before use.";
CM_ BO_ 674 "DATABASE_CANDIDATE: physical interpretation unverified; capture/layout evidence reported separately. INFO-DIV CAN, 125000 bit/s; CAN ID 0x2A2. PSA-RE title: CD_CHANGER_REPLY_PAYLOAD. CD changer multi-frame reply payload (track list, MP3 info or ID3 tag, depending on the request). Source: https://github.com/prototux/PSA-RE/blob/67f7581e7622410efdbb29c7eda3b86982b9b450/buses/AEE2010.full/LS.INFO-DIV/2A2.yml. Source sender alternatives: ICSV,CDC; physical TX/gateway forwarding not verified. WIRE ISO-TP ONLY: normal addressing candidate, maximum Classical CAN DLC 8; actual DLC may be shorter. Data includes padding. No reassembly, text, DID or application-layer decoding. Original application layouts are preserved in source JSON; do not decode them at wire offsets. Unresolved alternative source layouts preserved in source JSON. ";
CM_ SG_ 674 FlowPadding5 "TRANSPORT_CANDIDATE: normal-addressing ISO-TP. PSA-RE bits 8.7-8.0. ";
CM_ SG_ 674 FirstData6 "TRANSPORT_CANDIDATE: normal-addressing ISO-TP. PSA-RE bits 8.7-8.0. ";
CM_ SG_ 674 UnknownData7 "TRANSPORT_CANDIDATE: normal-addressing ISO-TP. PSA-RE bits 8.7-8.0. ";
CM_ SG_ 674 ConsecutiveData7 "TRANSPORT_CANDIDATE: normal-addressing ISO-TP. PSA-RE bits 8.7-8.0. ";
CM_ SG_ 674 SingleData7 "TRANSPORT_CANDIDATE: normal-addressing ISO-TP. PSA-RE bits 8.7-8.0. ";
CM_ SG_ 674 FlowPadding4 "TRANSPORT_CANDIDATE: normal-addressing ISO-TP. PSA-RE bits 7.7-7.0. ";
CM_ SG_ 674 FirstData5 "TRANSPORT_CANDIDATE: normal-addressing ISO-TP. PSA-RE bits 7.7-7.0. ";
CM_ SG_ 674 UnknownData6 "TRANSPORT_CANDIDATE: normal-addressing ISO-TP. PSA-RE bits 7.7-7.0. ";
CM_ SG_ 674 ConsecutiveData6 "TRANSPORT_CANDIDATE: normal-addressing ISO-TP. PSA-RE bits 7.7-7.0. ";
CM_ SG_ 674 SingleData6 "TRANSPORT_CANDIDATE: normal-addressing ISO-TP. PSA-RE bits 7.7-7.0. ";
CM_ SG_ 674 FlowPadding3 "TRANSPORT_CANDIDATE: normal-addressing ISO-TP. PSA-RE bits 6.7-6.0. ";
CM_ SG_ 674 FirstData4 "TRANSPORT_CANDIDATE: normal-addressing ISO-TP. PSA-RE bits 6.7-6.0. ";
CM_ SG_ 674 UnknownData5 "TRANSPORT_CANDIDATE: normal-addressing ISO-TP. PSA-RE bits 6.7-6.0. ";
CM_ SG_ 674 ConsecutiveData5 "TRANSPORT_CANDIDATE: normal-addressing ISO-TP. PSA-RE bits 6.7-6.0. ";
CM_ SG_ 674 SingleData5 "TRANSPORT_CANDIDATE: normal-addressing ISO-TP. PSA-RE bits 6.7-6.0. ";
CM_ SG_ 674 FlowPadding2 "TRANSPORT_CANDIDATE: normal-addressing ISO-TP. PSA-RE bits 5.7-5.0. ";
CM_ SG_ 674 FirstData3 "TRANSPORT_CANDIDATE: normal-addressing ISO-TP. PSA-RE bits 5.7-5.0. ";
CM_ SG_ 674 UnknownData4 "TRANSPORT_CANDIDATE: normal-addressing ISO-TP. PSA-RE bits 5.7-5.0. ";
CM_ SG_ 674 ConsecutiveData4 "TRANSPORT_CANDIDATE: normal-addressing ISO-TP. PSA-RE bits 5.7-5.0. ";
CM_ SG_ 674 SingleData4 "TRANSPORT_CANDIDATE: normal-addressing ISO-TP. PSA-RE bits 5.7-5.0. ";
CM_ SG_ 674 FlowPadding1 "TRANSPORT_CANDIDATE: normal-addressing ISO-TP. PSA-RE bits 4.7-4.0. ";
CM_ SG_ 674 FirstData2 "TRANSPORT_CANDIDATE: normal-addressing ISO-TP. PSA-RE bits 4.7-4.0. ";
CM_ SG_ 674 UnknownData3 "TRANSPORT_CANDIDATE: normal-addressing ISO-TP. PSA-RE bits 4.7-4.0. ";
CM_ SG_ 674 ConsecutiveData3 "TRANSPORT_CANDIDATE: normal-addressing ISO-TP. PSA-RE bits 4.7-4.0. ";
CM_ SG_ 674 SingleData3 "TRANSPORT_CANDIDATE: normal-addressing ISO-TP. PSA-RE bits 4.7-4.0. ";
CM_ SG_ 674 FirstData1 "TRANSPORT_CANDIDATE: normal-addressing ISO-TP. PSA-RE bits 3.7-3.0. ";
CM_ SG_ 674 UnknownData2 "TRANSPORT_CANDIDATE: normal-addressing ISO-TP. PSA-RE bits 3.7-3.0. ";
CM_ SG_ 674 ConsecutiveData2 "TRANSPORT_CANDIDATE: normal-addressing ISO-TP. PSA-RE bits 3.7-3.0. ";
CM_ SG_ 674 SingleData2 "TRANSPORT_CANDIDATE: normal-addressing ISO-TP. PSA-RE bits 3.7-3.0. ";
CM_ SG_ 674 SeparationTimeRaw "TRANSPORT_CANDIDATE: normal-addressing ISO-TP. PSA-RE bits 3.7-3.0. Raw STmin code; 0xF1..0xF9 are not milliseconds.";
CM_ SG_ 674 UnknownData1 "TRANSPORT_CANDIDATE: normal-addressing ISO-TP. PSA-RE bits 2.7-2.0. ";
CM_ SG_ 674 ConsecutiveData1 "TRANSPORT_CANDIDATE: normal-addressing ISO-TP. PSA-RE bits 2.7-2.0. ";
CM_ SG_ 674 SingleData1 "TRANSPORT_CANDIDATE: normal-addressing ISO-TP. PSA-RE bits 2.7-2.0. ";
CM_ SG_ 674 BlockSize "TRANSPORT_CANDIDATE: normal-addressing ISO-TP. PSA-RE bits 2.7-2.0. ";
CM_ SG_ 674 UnknownPciLow "TRANSPORT_CANDIDATE: normal-addressing ISO-TP. PSA-RE bits 1.3-1.0. ";
CM_ SG_ 674 FlowStatus "TRANSPORT_CANDIDATE: normal-addressing ISO-TP. PSA-RE bits 1.3-1.0. ";
CM_ SG_ 674 ConsecutiveSequence "TRANSPORT_CANDIDATE: normal-addressing ISO-TP. PSA-RE bits 1.3-1.0. ";
CM_ SG_ 674 FirstFrameLength "TRANSPORT_CANDIDATE: normal-addressing ISO-TP. PSA-RE bits 1.3-2.0. 12-bit declared PDU length; not a reassembled value.";
CM_ SG_ 674 SingleFrameLength "TRANSPORT_CANDIDATE: normal-addressing ISO-TP. PSA-RE bits 1.3-1.0. Declared data length; not a validity check.";
CM_ SG_ 674 IsoTpFrameType "TRANSPORT_CANDIDATE: normal-addressing ISO-TP. PSA-RE bits 1.7-1.4. PCI high nibble; normal addressing candidate.";
CM_ BO_ 676 "DATABASE_CANDIDATE: physical interpretation unverified; capture/layout evidence reported separately. INFO-DIV CAN, 125000 bit/s; CAN ID 0x2A4. PSA-RE title: RADIO_LANGUAGE_STATUS. Radio settings: display language and telephone function state. Source: https://github.com/prototux/PSA-RE/blob/67f7581e7622410efdbb29c7eda3b86982b9b450/buses/AEE2010.full/LS.INFO-DIV/2A4.yml. Source sender alternatives: RAD,ICSV; physical TX/gateway forwarding not verified. Unresolved alternative source layouts preserved in source JSON. ";
CM_ SG_ 676 RadioLanguage "DATABASE_CANDIDATE: physical interpretation unverified; capture/layout evidence reported separately. PSA-RE bits 1.4-1.0. Language used in the radio Upstream default raw=0 (not necessarily valid data).";
CM_ SG_ 676 Unused1 "DATABASE_CANDIDATE: physical interpretation unverified; capture/layout evidence reported separately. PSA-RE bits 1.6-1.5. ";
CM_ SG_ 676 TelematicsFunctionsStatus "DATABASE_CANDIDATE: physical interpretation unverified; capture/layout evidence reported separately. PSA-RE bits 1.7. Telematics functions status Upstream default raw=0 (not necessarily valid data).";
CM_ BO_ 679 "DATABASE_CANDIDATE: physical interpretation unverified; capture/layout evidence reported separately. INFO-DIV CAN, 125000 bit/s; CAN ID 0x2A7. PSA-RE title: CRUISE_CONTROL_PRESET_SPEEDS. Preset speed values (up to 6) and availability information for the cruise control. Source: https://github.com/prototux/PSA-RE/blob/67f7581e7622410efdbb29c7eda3b86982b9b450/buses/AEE2010.full/LS.INFO-DIV/2A7.yml. Source sender alternatives: ICSV,BSI; physical TX/gateway forwarding not verified. Observed 597 frames in info_apka.csv,info_buzeni_obc.csv,info_charging.csv,info_standby.csv,info_start_jizda.csv,infocan.csv; DLCs [7]. ";
CM_ SG_ 679 Unused1 "DATABASE_CANDIDATE: physical interpretation unverified; capture/layout evidence reported separately. PSA-RE bits 7.6-7.0. ";
CM_ SG_ 679 CruiseMenuInfoAvailability "DATABASE_CANDIDATE: physical interpretation unverified; capture/layout evidence reported separately. PSA-RE bits 7.7. Cruise control menu information availability Upstream default raw=0 (not necessarily valid data).";
CM_ SG_ 679 Stop6SpeedValue "DATABASE_CANDIDATE: physical interpretation unverified; capture/layout evidence reported separately. PSA-RE bits 6.7-6.0. Value of stop 6 speed Raw invalid=255; numeric DBC decoders may still scale it: check raw before use. Upstream default raw=0 (not necessarily valid data).";
CM_ SG_ 679 SpeedLimitZone5Speed "DATABASE_CANDIDATE: physical interpretation unverified; capture/layout evidence reported separately. PSA-RE bits 5.7-5.0. Speed limiter zone 5 speed value Upstream default raw=0 (not necessarily valid data).";
CM_ SG_ 679 SpeedLimitZone4Speed "DATABASE_CANDIDATE: physical interpretation unverified; capture/layout evidence reported separately. PSA-RE bits 4.7-4.0. Speed limiter zone 4 speed value Upstream default raw=0 (not necessarily valid data).";
CM_ SG_ 679 SpeedLimitZone3Speed "DATABASE_CANDIDATE: physical interpretation unverified; capture/layout evidence reported separately. PSA-RE bits 3.7-3.0. Speed limiter zone 3 speed value Upstream default raw=0 (not necessarily valid data).";
CM_ SG_ 679 SpeedLimitZone2Speed "DATABASE_CANDIDATE: physical interpretation unverified; capture/layout evidence reported separately. PSA-RE bits 2.7-2.0. Speed limiter zone 2 speed value Upstream default raw=0 (not necessarily valid data).";
CM_ SG_ 679 SpeedLimitZone1Speed "DATABASE_CANDIDATE: physical interpretation unverified; capture/layout evidence reported separately. PSA-RE bits 1.7-1.0. Speed limiter zone 1 speed value Upstream default raw=0 (not necessarily valid data).";
CM_ BO_ 680 "DATABASE_CANDIDATE: physical interpretation unverified; capture/layout evidence reported separately. INFO-DIV CAN, 125000 bit/s; CAN ID 0x2A8. PSA-RE title: ENGINE_HYBRID_DYNAMIC_DATA_9. Additional cruise control display status: automatic activation prompt, overspeed warning and toggle switch position. Source: https://github.com/prototux/PSA-RE/blob/67f7581e7622410efdbb29c7eda3b86982b9b450/buses/AEE2010.full/LS.INFO-DIV/2A8.yml. Source sender alternatives: BSI; physical TX/gateway forwarding not verified. Observed 587 frames in info_apka.csv,info_buzeni_obc.csv,info_charging.csv,info_standby.csv,info_start_jizda.csv,infocan.csv; DLCs [1]. ";
CM_ SG_ 680 Unused1 "DATABASE_CANDIDATE: physical interpretation unverified; capture/layout evidence reported separately. PSA-RE bits 1.4-1.0. ";
CM_ SG_ 680 AccResumeDrivingPrompt "DATABASE_CANDIDATE: physical interpretation unverified; capture/layout evidence reported separately. PSA-RE bits 1.5. Pop-up prompting the driver to resume driving Upstream default raw=0 (not necessarily valid data).";
CM_ SG_ 680 AdvcnpOverspeedAlert "DATABASE_CANDIDATE: physical interpretation unverified; capture/layout evidence reported separately. PSA-RE bits 1.6. ADVCNP (speed-limit assist) overspeed alert Upstream default raw=0 (not necessarily valid data).";
CM_ SG_ 680 CruiseControlTypeSwitchPosition "DATABASE_CANDIDATE: physical interpretation unverified; capture/layout evidence reported separately. PSA-RE bits 1.7. Position of the cruise control / adaptive cruise control selector switch";
CM_ BO_ 681 "DATABASE_CANDIDATE: physical interpretation unverified; capture/layout evidence reported separately. INFO-DIV CAN, 125000 bit/s; CAN ID 0x2A9. PSA-RE title: PHONE_STATUS_EXPORT. Mobile phone status relayed to the display: battery level, signal strength and network type. Source: https://github.com/prototux/PSA-RE/blob/67f7581e7622410efdbb29c7eda3b86982b9b450/buses/AEE2010.full/LS.INFO-DIV/2A9.yml. Source sender alternatives: ICSV,BTEL,OVIP; physical TX/gateway forwarding not verified. ";
CM_ SG_ 681 Unused3 "DATABASE_CANDIDATE: physical interpretation unverified; capture/layout evidence reported separately. PSA-RE bits 3.3-3.0. ";
CM_ SG_ 681 InternetConnectionType "DATABASE_CANDIDATE: physical interpretation unverified; capture/layout evidence reported separately. PSA-RE bits 3.7-3.4. Type of internet connection Upstream default raw=15 (not necessarily valid data).";
CM_ SG_ 681 PhoneSignalLevel "DATABASE_CANDIDATE: physical interpretation unverified; capture/layout evidence reported separately. PSA-RE bits 2.6-2.0. Phone signal reception level Raw invalid=127; numeric DBC decoders may still scale it: check raw before use. Upstream default raw=127 (not necessarily valid data).";
CM_ SG_ 681 Unused2 "DATABASE_CANDIDATE: physical interpretation unverified; capture/layout evidence reported separately. PSA-RE bits 2.7. ";
CM_ SG_ 681 PhoneBatteryLevel "DATABASE_CANDIDATE: physical interpretation unverified; capture/layout evidence reported separately. PSA-RE bits 1.6-1.0. Phone battery level Raw invalid=127; numeric DBC decoders may still scale it: check raw before use. Upstream default raw=127 (not necessarily valid data).";
CM_ SG_ 681 Unused1 "DATABASE_CANDIDATE: physical interpretation unverified; capture/layout evidence reported separately. PSA-RE bits 1.7. ";
CM_ BO_ 685 "DATABASE_CANDIDATE: physical interpretation unverified; capture/layout evidence reported separately. INFO-DIV CAN, 125000 bit/s; CAN ID 0x2AD. PSA-RE title: CLIMATE_HMI_COMMAND. Commands sent by the BSI to the climate control: cabin air purifier level and state, filter/cabin cleaning states, ionizer command, air intake, blower and central temperature setpoints. Source: https://github.com/prototux/PSA-RE/blob/67f7581e7622410efdbb29c7eda3b86982b9b450/buses/AEE2010.full/LS.INFO-DIV/2AD.yml. Source sender alternatives: BSI; physical TX/gateway forwarding not verified. Observed 1197 frames in info_apka.csv,info_buzeni_obc.csv,info_charging.csv,info_standby.csv,info_start_jizda.csv,infocan.csv; DLCs [8]. ";
CM_ SG_ 685 CabinAirQualityLevel "DATABASE_CANDIDATE: physical interpretation unverified; capture/layout evidence reported separately. PSA-RE bits 8.1-8.0. Cabin air quality level Upstream default raw=3 (not necessarily valid data).";
CM_ SG_ 685 CabinAirPurifierState "DATABASE_CANDIDATE: physical interpretation unverified; capture/layout evidence reported separately. PSA-RE bits 8.4-8.2. Cabin air purifier state Upstream default raw=7 (not necessarily valid data).";
CM_ SG_ 685 Unused2 "DATABASE_CANDIDATE: physical interpretation unverified; capture/layout evidence reported separately. PSA-RE bits 8.5. ";
CM_ SG_ 685 CabinAirPurificationState "DATABASE_CANDIDATE: physical interpretation unverified; capture/layout evidence reported separately. PSA-RE bits 8.7-8.6. Cabin air purification state Upstream default raw=3 (not necessarily valid data).";
CM_ SG_ 685 RearLeftBlowerSetpoint "DATABASE_CANDIDATE: physical interpretation unverified; capture/layout evidence reported separately. PSA-RE bits 7.7-7.0. Rear left blower setpoint Raw invalid=255; numeric DBC decoders may still scale it: check raw before use. Upstream default raw=0 (not necessarily valid data).";
CM_ SG_ 685 RearHeatedVentilatedSeatsConfig "DATABASE_CANDIDATE: physical interpretation unverified; capture/layout evidence reported separately. PSA-RE bits 6.1-6.0. Rear climate panel heated/ventilated seat button configuration Upstream default raw=0 (not necessarily valid data).";
CM_ SG_ 685 CabinAirFilterState "DATABASE_CANDIDATE: physical interpretation unverified; capture/layout evidence reported separately. PSA-RE bits 6.3-6.2. Cabin air filter state Upstream default raw=3 (not necessarily valid data).";
CM_ SG_ 685 IonizerCommand "DATABASE_CANDIDATE: physical interpretation unverified; capture/layout evidence reported separately. PSA-RE bits 6.5-6.4. Ioniser activation command (validated by climate control) Upstream default raw=3 (not necessarily valid data).";
CM_ SG_ 685 IonizerState "DATABASE_CANDIDATE: physical interpretation unverified; capture/layout evidence reported separately. PSA-RE bits 6.7-6.6. Ioniser activation state (validated by climate control) Upstream default raw=3 (not necessarily valid data).";
CM_ SG_ 685 RearLeftBlowerMinusState "DATABASE_CANDIDATE: physical interpretation unverified; capture/layout evidence reported separately. PSA-RE bits 5.3-5.0. Rear left blower speed state on minus button press Upstream default raw=2 (not necessarily valid data).";
CM_ SG_ 685 RearBlowerPlusSwitchState "DATABASE_CANDIDATE: physical interpretation unverified; capture/layout evidence reported separately. PSA-RE bits 5.7-5.4. Rear blower switch state when pressing the \"+\" button Upstream default raw=9 (not necessarily valid data).";
CM_ SG_ 685 FrontBlowerMinusState "DATABASE_CANDIDATE: physical interpretation unverified; capture/layout evidence reported separately. PSA-RE bits 4.3-4.0. Front blower speed state on minus button press Upstream default raw=2 (not necessarily valid data).";
CM_ SG_ 685 FrontBlowerPlusSwitchState "DATABASE_CANDIDATE: physical interpretation unverified; capture/layout evidence reported separately. PSA-RE bits 4.7-4.4. Front blower switch state when pressing the \"+\" button Upstream default raw=9 (not necessarily valid data).";
CM_ SG_ 685 FrontBlowerMotorSetpoint "DATABASE_CANDIDATE: physical interpretation unverified; capture/layout evidence reported separately. PSA-RE bits 3.7-3.0. Front blower motor setpoint Raw invalid=255; numeric DBC decoders may still scale it: check raw before use. Upstream default raw=0 (not necessarily valid data).";
CM_ SG_ 685 Unused1 "DATABASE_CANDIDATE: physical interpretation unverified; capture/layout evidence reported separately. PSA-RE bits 2.0. ";
CM_ SG_ 685 RearCentralDisplayPresence "DATABASE_CANDIDATE: physical interpretation unverified; capture/layout evidence reported separately. PSA-RE bits 2.1. Rear central HMI display presence Upstream default raw=0 (not necessarily valid data).";
CM_ SG_ 685 HeatedWindshieldPresence "DATABASE_CANDIDATE: physical interpretation unverified; capture/layout evidence reported separately. PSA-RE bits 2.2. Heated windshield equipment presence Upstream default raw=0 (not necessarily valid data).";
CM_ SG_ 685 HeatedVentilatedSeatsConfig "DATABASE_CANDIDATE: physical interpretation unverified; capture/layout evidence reported separately. PSA-RE bits 2.4-2.3. Heated and/or ventilated seats configuration Upstream default raw=0 (not necessarily valid data).";
CM_ SG_ 685 AirInletSetpoint "DATABASE_CANDIDATE: physical interpretation unverified; capture/layout evidence reported separately. PSA-RE bits 2.6-2.5. Air inlet actuator setpoint (outside/recirculation) Upstream default raw=0 (not necessarily valid data).";
CM_ SG_ 685 HeatedWindshieldIndicatorRequest "DATABASE_CANDIDATE: physical interpretation unverified; capture/layout evidence reported separately. PSA-RE bits 2.7. Heated windshield indicator light request Upstream default raw=0 (not necessarily valid data).";
CM_ SG_ 685 AcSystemType "DATABASE_CANDIDATE: physical interpretation unverified; capture/layout evidence reported separately. PSA-RE bits 1.1-1.0. Air conditioning system type";
CM_ SG_ 685 CenterTemperatureSetpoint "DATABASE_CANDIDATE: physical interpretation unverified; capture/layout evidence reported separately. PSA-RE bits 1.4-1.2. Centered temperature setpoint value Upstream default raw=3 (not necessarily valid data).";
CM_ SG_ 685 LuchWarningLamp "DATABASE_CANDIDATE: physical interpretation unverified; capture/layout evidence reported separately. PSA-RE bits 1.5. LUCH warning lamp on Upstream default raw=0 (not necessarily valid data).";
CM_ SG_ 685 RestoreModeEnabled "DATABASE_CANDIDATE: physical interpretation unverified; capture/layout evidence reported separately. PSA-RE bits 1.6. Restore mode enabled Upstream default raw=0 (not necessarily valid data).";
CM_ SG_ 685 AcLcdDisplayOffRequest "DATABASE_CANDIDATE: physical interpretation unverified; capture/layout evidence reported separately. PSA-RE bits 1.7. Climate control LCD display switch-off request Upstream default raw=0 (not necessarily valid data).";
VAL_ 603 ClimatePrecondSundaySlot2Enabled 0 "Function off" 1 "Function active" ;
VAL_ 603 ClimatePrecondSaturdaySlo_fd2bfe 0 "Function off" 1 "Function active" ;
VAL_ 603 ClimatePrecondFridaySlot2Enabled 0 "Function off" 1 "Function active" ;
VAL_ 603 ClimatePrecondThursdaySlo_8ba9ec 0 "Function off" 1 "Function active" ;
VAL_ 603 ClimatePrecondWednesdaySl_20214f 0 "Function off" 1 "Function active" ;
VAL_ 603 ClimatePrecondTuesdaySlot_413385 0 "Function off" 1 "Function active" ;
VAL_ 603 ClimatePrecondMondaySlot2Enabled 0 "Function off" 1 "Function active" ;
VAL_ 603 ClimatePrecondSlot2Enabled 0 "Function off" 1 "Function active" ;
VAL_ 603 ClimatePrecondSundaySlot1Enabled 0 "Function off" 1 "Function active" ;
VAL_ 603 ClimatePrecondSaturdaySlo_c187b9 0 "Function off" 1 "Function active" ;
VAL_ 603 ClimatePrecondFridaySlot1Enabled 0 "Function off" 1 "Function active" ;
VAL_ 603 ClimatePrecondThursdaySlo_13efd6 0 "Function off" 1 "Function active" ;
VAL_ 603 ClimatePrecondWednesdaySl_d65ca4 0 "Function off" 1 "Function active" ;
VAL_ 603 ClimatePrecondTuesdaySlot_1bddd8 0 "Function off" 1 "Function active" ;
VAL_ 603 ClimatePrecondMondaySlot1Enabled 0 "Function off" 1 "Function active" ;
VAL_ 603 ClimatePrecondSlot1Enabled 0 "Function off" 1 "Function active" ;
VAL_ 603 ClimatePrecondMenuAvailability 0 "Unavailable" 1 "Available" ;
VAL_ 604 EcocoachTripConsumption 511 "Not_available" ;
VAL_ 604 EcocoachDailyScoreSun 15 "Not_available" ;
VAL_ 604 EcocoachDailyScoreSat 15 "Not_available" ;
VAL_ 604 EcocoachDailyScoreFri 15 "Not_available" ;
VAL_ 604 EcocoachDailyScoreThu 15 "Not_available" ;
VAL_ 604 EcocoachDailyScoreWed 15 "Not_available" ;
VAL_ 604 EcocoachDailyScoreTue 15 "Not_available" ;
VAL_ 604 EcocoachDailyScoreMon 15 "Not_available" ;
VAL_ 607 FlowStatus 0 "ContinueToSend" 1 "Wait" 2 "Overflow" ;
VAL_ 607 IsoTpFrameType 0 "SingleFrame" 1 "FirstFrame" 2 "ConsecutiveFrame" 3 "FlowControl" ;
VAL_ 608 AmlaItemStatus 0 "Function off" 1 "Function active" ;
VAL_ 608 AfsFunctionActive 0 "Inactive" 1 "Active" ;
VAL_ 608 ArsFunctionActive 0 "Inactive" 1 "Active" ;
VAL_ 608 IrvFunctionInhibited 0 "No inhibition" 1 "Inhibition" ;
VAL_ 608 Dae4wdItemModeStatus 0 "Sport mode" 1 "Normal mode" ;
VAL_ 608 DaeItemModeStatus 0 "Sport mode" 1 "Normal mode" ;
VAL_ 608 LoadedArmsAccessFunctionActive 0 "Inactive" 1 "Active" ;
VAL_ 608 IlvItemStatus 0 "Function off" 1 "Function active" ;
VAL_ 608 GrilleLightingFunctionStatus 0 "Function off" 1 "Function active" ;
VAL_ 608 CafrItemStatus 0 "Function off" 1 "Function active" ;
VAL_ 608 DriverAlertAssistFunctionActive 0 "Inactive" 1 "Active" ;
VAL_ 608 LoadedArmsLockFunctionActive 0 "Inactive" 1 "Active" ;
VAL_ 608 EtsrFunctionActive 0 "Function off" 1 "Function active" ;
VAL_ 608 EcsModeFunctionActive 0 "Permanent deselection" 1 "Temporary deselection" ;
VAL_ 608 ActiveUserProfile 0 "Default profile" 1 "User profile 1" 2 "User profile 2" ;
VAL_ 608 ReverseIndexingStatus 0 "Function off" 1 "Function active" ;
VAL_ 608 TpmsReinitializationStatus 0 "Function off" 1 "Function active" ;
VAL_ 608 CollisionRiskBrakingType 0 "Function off" 1 "Function active" ;
VAL_ 608 ArcSensitivityLevel 1 "Sensitivity 1" 2 "Sensitivity 2" 3 "Sensitivity 3" ;
VAL_ 608 ArcFunctionActive 0 "Function off" 1 "Function active" ;
VAL_ 608 ConfigurableButtonFunction 0 "Dome light lighting" 1 "Black Panel" 2 "Access to the alert log (JDA)" 3 "Customisation" 4 "Instrument cluster colouring" 5 "Manual check" ;
VAL_ 608 RearFlapMotorizationFunct_177f8c 0 "Function off" 1 "Function active" ;
VAL_ 608 AutomaticRearWiperInReverse 0 "Function off" 1 "Function active" ;
VAL_ 608 BlindSpotMonitoringFeedbackType 0 "Function off" 1 "Function active" ;
VAL_ 608 ParkingAidSetup 0 "Function off" 1 "Function active" ;
VAL_ 608 AutomaticHeadlightsSwitchingOn 0 "Function off" 1 "Function active" ;
VAL_ 608 UnlockingLightingDuration 0 "15 s" 1 "30 s" 2 "60 s" ;
VAL_ 608 UnlockingLightingFunction 0 "Function off" 1 "Function active" ;
VAL_ 608 MotorwayLightingFunction 0 "Function off" 1 "Function active" ;
VAL_ 608 FollowMeHomeDuration 0 "15 s" 1 "30 s" 2 "60 s" ;
VAL_ 608 FollowMeHome 0 "Function off" 1 "Function active" ;
VAL_ 608 AmbientLighting 0 "Function off" 1 "Function active" ;
VAL_ 608 DlrFunction 0 "Function off" 1 "Function active" ;
VAL_ 608 AdaptiveLighting 0 "Function off" 1 "Function active" ;
VAL_ 608 DriverGreeting 0 "Function deactivated" 1 "Function activated" ;
VAL_ 608 RearOpeningsSelectivityStatus 0 "Function off" 1 "Function active" ;
VAL_ 608 CabOpeningsSelectivityFun_dd2313 0 "Function off" 1 "Function active" ;
VAL_ 608 DoorUnlockingModeOnKey 0 "Function off" 1 "Function active" ;
VAL_ 608 AutomaticElectricParkingB_11b15b 0 "Function off" 1 "Function active" ;
VAL_ 608 VehicleSoundHarmony 0 "Harmony 1" 1 "Harmony 2" 2 "Harmony 3" 3 "Harmony 4" ;
VAL_ 608 VehicleConfigurationDataValid 0 "Unavailable" 1 "Available" ;
VAL_ 608 AmbientLightingLevel 0 "Level 0" 1 "Level 1" 2 "Level 2" 3 "Level 3" 4 "Level 4" 5 "Level 5" 6 "Level 6" 7 "Invalid" ;
VAL_ 608 TemperatureUnit 0 "Degrees Celsius" 1 "Degrees Fahrenheit" ;
VAL_ 608 ConfigVolumeUnit 0 "litre" 1 "Gallon" ;
VAL_ 608 ConfigConsumptionUnit 0 "Volume for 100 distance units (e.g. 1/100 km)" 1 "Distance per volume unit (e.g. mpg, km/l)" ;
VAL_ 608 DistanceUnit 0 "km" 1 "miles" ;
VAL_ 608 VehicleLanguage 0 "French" 1 "English" 2 "German" 3 "Spanish" 4 "Italian" 5 "Portuguese" 6 "Dutch" 7 "Greek" 8 "Brazilian Portuguese" 9 "Polish" 10 "Traditional Chinese" 11 "Simplified Chinese" 12 "Turkish" 13 "Japanese" 14 "Russian" 15 "Czech" 16 "Croatian" 17 "Hungarian" 18 "Arabic" 19 "Bulgarian" 20 "Korean" 21 "Danish" 22 "Estonian" 23 "Farsi" 24 "Finnish" 25 "Hebrew" 26 "Norwegian" 27 "Romanian" 28 "Serbian" 29 "Swedish" 30 "Ukrainian" 31 "Vietnamese" ;
VAL_ 608 UnitLanguageDataValidity 0 "Unavailable" 1 "Available" ;
VAL_ 609 LpgAverageConsumptionTrip2 511 "Not_available" ;
VAL_ 609 MeanConsumption 65535 "Not_available" ;
VAL_ 609 TotalDistance 65535 "Not_available" ;
VAL_ 609 MeanSpeed 255 "Not_available" ;
VAL_ 611 FlowStatus 0 "ContinueToSend" 1 "Wait" 2 "Overflow" ;
VAL_ 611 IsoTpFrameType 0 "SingleFrame" 1 "FirstFrame" 2 "ConsecutiveFrame" 3 "FlowControl" ;
VAL_ 612 TunerMemoryBank 0 "unspecified" 1 "FM" 2 "AM" 3 "DAB" 15 "Invalid" ;
VAL_ 612 Frequency 2047 "Not_available" ;
VAL_ 612 MediaPlaybackTimer 65535 "Not_available" ;
VAL_ 613 MpxAvailable 0 "Not available" 1 "Available" 2 "Decoding in progress" ;
VAL_ 613 PsNameAvailable 0 "Not available" 1 "Available" 2 "Decoding in progress" ;
VAL_ 613 RdtextStatus 0 "Not available" 1 "Available" 3 "RDS decoding on" ;
VAL_ 613 RdtextFunctionStatus 0 "Not requested" 1 "Requested" ;
VAL_ 613 NewsFunctionStatus 0 "Not requested" 1 "Requested" ;
VAL_ 613 NewsBroadcastStatus 0 "None" 1 "NEWS1" 2 "News 2" 3 "NEWS3" 4 "NEWS4" 5 "NEWS5" 6 "NEWS6" 7 "NEWS7" ;
VAL_ 613 NewsStatus 0 "Not available" 1 "Available" 3 "RDS decoding on" ;
VAL_ 613 DabfmStatus 0 "Not available" 1 "Available" 3 "RDS decoding on" ;
VAL_ 613 DabfmFunctionStatus 0 "Not requested" 1 "Requested" ;
VAL_ 613 PtyCurrent 0 "No PTY" 1 "News" 2 "Current affairs" 3 "Info service" 4 "Sport" 5 "Education" 6 "Fiction" 7 "Culture" 8 "Science/culture" 9 "Entertainment" 10 "Pop music" 11 "Rock music" 12 "Songs" 13 "Light classic" 14 "Classical music" 15 "Other music" 16 "Weather" 17 "Economy" 18 "Children" 19 "Company" 20 "Religion" 21 "Open line" 22 "Travel" 23 "Leisure" 24 "Jazz" 25 "Country" 26 "Local songs" 27 "Oldies" 28 "Folklore" 29 "Documentary" ;
VAL_ 613 TaOut 0 "No" 1 "Yes" ;
VAL_ 613 TaStatus 0 "Not available" 1 "Available" 3 "RDS decoding on" ;
VAL_ 613 TaActivated 0 "Not requested" 1 "Requested" ;
VAL_ 613 AfStatus 0 "Not available" 1 "Available" 3 "RDS decoding on" ;
VAL_ 613 AfActivated 0 "Not requested" 1 "Requested" ;
VAL_ 615 CruiseMenuInfoAvailability 0 "Unavailable" 1 "Available" ;
VAL_ 615 Stop6SpeedValue 255 "Not_available" ;
VAL_ 616 AuthenticationHmiDisplayRequest 0 "No request" 1 "Request" ;
VAL_ 616 ManualModeSelectionState 0 "Not selected" 1 "Selected" ;
VAL_ 616 VehicleModeSelectorCommand 0 "None" 1 "Low" 2 "High" ;
VAL_ 616 CurrentVehicleMode 0 "Normal" 1 "Sport" 2 "Comfort" 3 "Eco" 4 "Sand" 5 "Mud" 6 "Snow" 7 "ZEV" 8 "EAWD" 9 "Hybrid" 10 "ZEV Eco mode" 11 "Hybrid Eco" 12 "Eco plus" ;
VAL_ 616 VehicleModeSelectorConfiguration 0 "Selector absent" 1 "Sport / Eco manual" 2 "Sport-Eco" 3 "Comfort / Sport / Eco" 5 "ASR only" 6 "Sport/Comfort/Eco/ASR" 7 "Sport/Eco ASR" 8 "Manual ASR" 9 "Sport/comfort ASR" 10 "Eco/Comfort/Sport manual" 11 "Grip Control, Eco, Sport, Manual" 12 "ASR+/Eco/Sport/Manual" ;
VAL_ 616 DriverMassageStatus 0 "FREE" 1 "Massage off" 2 "Massage on" 3 "Massage pause" ;
VAL_ 616 PassengerMassageStatus 0 "FREE" 1 "Massage off" 2 "Massage on" 3 "Massage pause" ;
VAL_ 616 SmartDeviceNotification 0 "No request" 1 "Requested" ;
VAL_ 616 AsrConnectionStatus 0 "ESP connected" 1 "ASR inhibited" 2 "ESP inhibited" 3 "ESP faulty" ;
VAL_ 616 DynamicModeHmiFeedback 0 "Normal" 1 "Sport" 2 "Comfort" 3 "Eco" ;
VAL_ 616 DynamicSettingType 0 "No system" 1 "System" ;
VAL_ 616 DynamicModeSelectedSynthesis 0 "Normal" 1 "Sport" 2 "Comfort" 3 "Eco" ;
VAL_ 616 DriverMassageButtonStatus 0 "Key released" 1 "Key pressed" ;
VAL_ 616 PassengerMassageButtonStatus 0 "Key released" 1 "Key pressed" ;
VAL_ 616 DriverMassageIntensityStatus 0 "Weak intensity" 1 "Normal intensity" 2 "High intensity" 3 "FREE" ;
VAL_ 616 PassengerMassageIntensityStatus 0 "Weak intensity" 1 "Normal intensity" 2 "High intensity" 3 "FREE" ;
VAL_ 616 DriverMassageTypeStatus 1 "Type 1" 2 "Type 2" 3 "Type 3" 4 "Type 4" 5 "Type 5" 6 "Type 6" 7 "Type 7" 8 "Type 8" 15 "Invalid" ;
VAL_ 616 PassengerMassageTypeStatus 1 "Type 1" 2 "Type 2" 3 "Type 3" 4 "Type 4" 5 "Type 5" 6 "Type 6" 7 "Type 7" 8 "Type 8" 15 "Invalid" ;
VAL_ 616 VehiclePoiDisplayRequest 0 "No POI" 1 "Garage POI" 2 "POI pause" 3 "Petrol station POI" 4 "POI: charging station" 5 "AdBlue POI" ;
VAL_ 616 IlvSpeedRobustFlag 0 "Not robust" 1 "robust" ;
VAL_ 616 IlvOverspeedFlag 0 "Without overspeed" 1 "Overspeed" ;
VAL_ 616 IlvSignType 0 "EuroNCAP speed limit zone" 1 "End of speed-limit zone" 2 "Speed limit Area noEuroNcap" 3 "Invalid" ;
VAL_ 616 IlvSpeedToDisplay 255 "Not_available" ;
VAL_ 617 FlowStatus 0 "ContinueToSend" 1 "Wait" 2 "Overflow" ;
VAL_ 617 IsoTpFrameType 0 "SingleFrame" 1 "FirstFrame" 2 "ConsecutiveFrame" 3 "FlowControl" ;
VAL_ 625 FlowStatus 0 "ContinueToSend" 1 "Wait" 2 "Overflow" ;
VAL_ 625 IsoTpFrameType 0 "SingleFrame" 1 "FirstFrame" 2 "ConsecutiveFrame" 3 "FlowControl" ;
VAL_ 630 RearOpeningUnlockSelectiv_f38f2f 0 "Inactive" 1 "Active" ;
VAL_ 630 DriverDoorUnlockSelectivi_40d5a3 0 "Inactive" 1 "Active" ;
VAL_ 630 CabinLoadZoneSelectivityStatus 0 "Inactive" 1 "Active" ;
VAL_ 630 SelectivityFunctionStatus 0 "Inactive" 1 "Active" ;
VAL_ 630 RearOpeningLockStatus 0 "Unlocked" 1 "Locked" ;
VAL_ 630 TrunkLockingState 0 "Locked" 1 "Unlocked" ;
VAL_ 630 UreaRemainingAutonomy 16383 "Not_available" ;
VAL_ 630 UreaAutonomyDisplayRequest 0 "Not requested" 1 "Requested" ;
VAL_ 630 TimeMinute 63 "Not_available" ;
VAL_ 630 TimeHour 31 "Not_available" ;
VAL_ 630 ClockDay 63 "Not_available" ;
VAL_ 630 ClockMonth 0 "Value not used (0000)" 1 "January" 2 "February" 3 "March" 4 "April" 5 "May" 6 "June" 7 "July" 8 "August" 9 "September" 10 "October" 11 "November" 12 "December" 13 "Unused value (1101)" 14 "Unavailable" 15 "Invalid" ;
VAL_ 630 ClockDisplayType 0 "Steady" 1 "Flashing" ;
VAL_ 630 VehicleLockingState 0 "Invalid" 1 "Locked" 2 "Superlocked" 3 "Unlocked" 4 "Driver door unlocked" 5 "Cab unlocked" 6 "Loading zone unlocked" 7 "Invalid" ;
VAL_ 630 ClockYear 127 "Not_available" ;
VAL_ 630 ConfigDisplayTime 0 "Time displayed in 12-hour mode" 1 "Time displayed in 24-hour mode" ;
VAL_ 632 VparkAutoModeActive 0 "Inactive" 1 "Active" ;
VAL_ 632 VparkObstaclePresence 0 "False" 1 "Obstacle at the rear" 2 "Obstacle ahead" 3 "Obstacle on the left" 4 "Obstacle on the right" ;
VAL_ 632 VparkActivationStatus 0 "Inactive" 1 "Active" 2 "Failure detected" ;
VAL_ 632 VparkViewType 0 "No request" 1 "Windowed view" 2 "Panoramic view" 3 "360° view" ;
VAL_ 632 VparkViewState 0 "Standard view, front" 1 "Standard rear view" 2 "Panoramic front view" 3 "Panoramic rear view" 4 "Zoom view, front" 5 "Rear-view zoom" 6 "Left lateral view" 7 "Right side view" 8 "360 view Left" 9 "360° view, right" 10 "360 view suspended" ;
VAL_ 632 VparkDisplayBrightness 6 "Brightness 1" 7 "Brightness 2" 8 "BRIGHTNESS 3" 9 "Brightness 4" 10 "Brightness 5" ;
VAL_ 632 VparkDisplayContrast 0 "Contrast -5" 1 "Contrast -4" 2 "Contrast -3" 3 "Contrast -2" 4 "Contrast -1" 5 "Contrast 0" 6 "Contrast 1" 7 "Contrast 2" 8 "Contrast 3" 9 "Contrast 4" 10 "Contrast 5" ;
VAL_ 641 FlowStatus 0 "ContinueToSend" 1 "Wait" 2 "Overflow" ;
VAL_ 641 IsoTpFrameType 0 "SingleFrame" 1 "FirstFrame" 2 "ConsecutiveFrame" 3 "FlowControl" ;
VAL_ 660 FlowStatus 0 "ContinueToSend" 1 "Wait" 2 "Overflow" ;
VAL_ 660 IsoTpFrameType 0 "SingleFrame" 1 "FirstFrame" 2 "ConsecutiveFrame" 3 "FlowControl" ;
VAL_ 663 SpeedDisplayedOnHud 255 "Not_available" ;
VAL_ 663 HudScreenManualMovement 0 "No manual mirror movement" 1 "Manual movement of the mirror" ;
VAL_ 663 HudMemoryRecall 0 "No memory recall" 1 "Memorisation recall" ;
VAL_ 663 HudMemoryStatus 0 "No memorization ongoing" 1 "Memorization ongoing" ;
VAL_ 663 HudActivationStatus 0 "HUD not activated" 1 "Head-up display activated" 2 "Unavailable" 3 "Invalid" ;
VAL_ 663 MediaDisplayFault 0 "No fault detected" 1 "Failure detected" ;
VAL_ 667 ClimatePrecondSundaySlot4Enabled 0 "Function off" 1 "Function active" ;
VAL_ 667 ClimatePrecondSaturdaySlo_419d2b 0 "Function off" 1 "Function active" ;
VAL_ 667 ClimatePrecondFridaySlot4Enabled 0 "Function off" 1 "Function active" ;
VAL_ 667 ClimatePrecondThursdaySlo_d85853 0 "Function off" 1 "Function active" ;
VAL_ 667 ClimatePrecondWednesdaySl_c2d848 0 "Function off" 1 "Function active" ;
VAL_ 667 ClimatePrecondTuesdaySlot_ddb9f8 0 "Function off" 1 "Function active" ;
VAL_ 667 ClimatePrecondMondaySlot4Enabled 0 "Function off" 1 "Function active" ;
VAL_ 667 ClimatePrecondSlot4Enabled 0 "Function off" 1 "Function active" ;
VAL_ 667 ClimatePrecondSundaySlot3Enabled 0 "Function off" 1 "Function active" ;
VAL_ 667 ClimatePrecondSaturdaySlo_def41f 0 "Function off" 1 "Function active" ;
VAL_ 667 ClimatePrecondFridaySlot3Enabled 0 "Function off" 1 "Function active" ;
VAL_ 667 ClimatePrecondThursdaySlo_f9fbde 0 "Function off" 1 "Function active" ;
VAL_ 667 ClimatePrecondWednesdaySl_dfe9f3 0 "Function off" 1 "Function active" ;
VAL_ 667 ClimatePrecondTuesdaySlot_f7a007 0 "Function off" 1 "Function active" ;
VAL_ 667 ClimatePrecondMondaySlot3Enabled 0 "Function off" 1 "Function active" ;
VAL_ 667 ClimatePrecondSlot3Enabled 0 "Function off" 1 "Function active" ;
VAL_ 671 FlowStatus 0 "ContinueToSend" 1 "Wait" 2 "Overflow" ;
VAL_ 671 IsoTpFrameType 0 "SingleFrame" 1 "FirstFrame" 2 "ConsecutiveFrame" 3 "FlowControl" ;
VAL_ 672 FunctionStatusAccessRequest 0 "No request" 1 "Requested" ;
VAL_ 672 AlertLogAccessRequest 0 "No request" 1 "Requested" ;
VAL_ 672 CustomizationMenuAccessRequest 0 "No request" 1 "Requested" ;
VAL_ 672 ActiveProfileScreenAccessRequest 0 "No request" 1 "Requested" ;
VAL_ 672 ConfigurableKeyProgrammin_af2e87 0 "No request" 1 "Requested" ;
VAL_ 673 LpgAverageConsumptionTrip1 511 "Not_available" ;
VAL_ 673 MeanConsumption 65535 "Not_available" ;
VAL_ 673 TotalDistance 65535 "Not_available" ;
VAL_ 673 MeanSpeed 255 "Not_available" ;
VAL_ 674 FlowStatus 0 "ContinueToSend" 1 "Wait" 2 "Overflow" ;
VAL_ 674 IsoTpFrameType 0 "SingleFrame" 1 "FirstFrame" 2 "ConsecutiveFrame" 3 "FlowControl" ;
VAL_ 676 RadioLanguage 0 "French" 1 "English" 2 "German" 3 "Spanish" 4 "Italian" 5 "Portuguese" 6 "Dutch" 7 "Greek" 8 "Brazilian Portuguese" 9 "Polish" 10 "Traditional Chinese" 11 "Simplified Chinese" 12 "Turkish" 13 "Japanese" 14 "Russian" 15 "Invalid" ;
VAL_ 676 TelematicsFunctionsStatus 0 "No telematics function activated" 1 "At least one telematics function activated" ;
VAL_ 679 CruiseMenuInfoAvailability 0 "Unavailable" 1 "Available" ;
VAL_ 679 Stop6SpeedValue 255 "Not_available" ;
VAL_ 680 AccResumeDrivingPrompt 0 "No request" 1 "Requested" ;
VAL_ 680 AdvcnpOverspeedAlert 0 "No request" 1 "Requested" ;
VAL_ 680 CruiseControlTypeSwitchPosition 0 "Cruise control selected" 1 "Adaptive cruise control selected" ;
VAL_ 681 InternetConnectionType 0 "no internet" 1 "3G" 2 "3G+" 3 "EDGE" 4 "Wi-Fi" 5 "DUN" 14 "Unavailable" 15 "Invalid" ;
VAL_ 681 PhoneSignalLevel 127 "Not_available" ;
VAL_ 681 PhoneBatteryLevel 127 "Not_available" ;
VAL_ 685 CabinAirQualityLevel 0 "Good" 1 "Moderate" 2 "Unhealthy" 3 "Unavailable" ;
VAL_ 685 CabinAirPurifierState 0 "Off" 1 "Automatic" 2 "Low" 3 "Medium" 4 "High" 5 "Absent" 7 "Unavailable" ;
VAL_ 685 CabinAirPurificationState 0 "Off" 1 "In progress" 2 "PURE" 3 "Unavailable" ;
VAL_ 685 RearLeftBlowerSetpoint 255 "Not_available" ;
VAL_ 685 RearHeatedVentilatedSeatsConfig 0 "Absent" 1 "Heated seats" 2 "Heated and ventilated seats" ;
VAL_ 685 CabinAirFilterState 0 "OK" 1 "To change" 2 "Absent" 3 "Unavailable" ;
VAL_ 685 IonizerCommand 0 "ion_off" 1 "Ion clean" 2 "Ion comfort" 3 "Unavailable" ;
VAL_ 685 IonizerState 0 "ion_off" 1 "Ion clean" 2 "Ion comfort" 3 "Unavailable" ;
VAL_ 685 RearLeftBlowerMinusState 2 "Speed 1" 3 "Speed 2" 4 "Speed 3" 5 "Speed 4" 6 "Speed5" 7 "Speed 6" 8 "Speed 7" 9 "Speed 8" ;
VAL_ 685 RearBlowerPlusSwitchState 2 "Speed 1" 3 "Speed 2" 4 "Speed 3" 5 "Speed 4" 6 "Speed5" 7 "Speed 6" 8 "Speed 7" 9 "Speed 8" ;
VAL_ 685 FrontBlowerMinusState 2 "Speed 1" 3 "Speed 2" 4 "Speed 3" 5 "Speed 4" 6 "Speed5" 7 "Speed 6" 8 "Speed 7" 9 "Speed 8" ;
VAL_ 685 FrontBlowerPlusSwitchState 2 "Speed 1" 3 "Speed 2" 4 "Speed 3" 5 "Speed 4" 6 "Speed5" 7 "Speed 6" 8 "Speed 7" 9 "Speed 8" ;
VAL_ 685 FrontBlowerMotorSetpoint 255 "Not_available" ;
VAL_ 685 RearCentralDisplayPresence 0 "Absent" 1 "Present" ;
VAL_ 685 HeatedWindshieldPresence 0 "Absent" 1 "Present" ;
VAL_ 685 HeatedVentilatedSeatsConfig 0 "Absent" 1 "Heated seats" 2 "Heated and ventilated seats" ;
VAL_ 685 AirInletSetpoint 0 "Outside air" 1 "Partial recycling" 2 "Total recirculation" 3 "Invalid" ;
VAL_ 685 HeatedWindshieldIndicatorRequest 0 "Off" 1 "On" ;
VAL_ 685 AcSystemType 0 "CH" 1 "RF" 2 "RFTA" 3 "RFT" ;
VAL_ 685 CenterTemperatureSetpoint 0 "18°C or 64°F" 1 "19°C or 66°F" 2 "20 °C or 68 °F" 3 "21°C or 70°F" 4 "22°C or 72°F" 5 "23 °C or 74 °F" 6 "24 °C or 76 °F" 7 "25 °C or 78 °F" ;
VAL_ 685 LuchWarningLamp 0 "Not authorized" 1 "Authorised" ;
VAL_ 685 RestoreModeEnabled 0 "Not authorized" 1 "Authorised" ;
VAL_ 685 AcLcdDisplayOffRequest 0 "Not requested" 1 "Requested" ;
SG_MUL_VAL_ 607 SingleFrameLength IsoTpFrameType 0-0;
SG_MUL_VAL_ 607 FirstFrameLength IsoTpFrameType 1-1;
SG_MUL_VAL_ 607 ConsecutiveSequence IsoTpFrameType 2-2;
SG_MUL_VAL_ 607 FlowStatus IsoTpFrameType 3-3;
SG_MUL_VAL_ 607 UnknownPciLow IsoTpFrameType 4-15;
SG_MUL_VAL_ 607 BlockSize IsoTpFrameType 3-3;
SG_MUL_VAL_ 607 SingleData1 IsoTpFrameType 0-0;
SG_MUL_VAL_ 607 ConsecutiveData1 IsoTpFrameType 2-2;
SG_MUL_VAL_ 607 UnknownData1 IsoTpFrameType 4-15;
SG_MUL_VAL_ 607 SeparationTimeRaw IsoTpFrameType 3-3;
SG_MUL_VAL_ 607 SingleData2 IsoTpFrameType 0-0;
SG_MUL_VAL_ 607 ConsecutiveData2 IsoTpFrameType 2-2;
SG_MUL_VAL_ 607 UnknownData2 IsoTpFrameType 4-15;
SG_MUL_VAL_ 607 FirstData1 IsoTpFrameType 1-1;
SG_MUL_VAL_ 607 SingleData3 IsoTpFrameType 0-0;
SG_MUL_VAL_ 607 ConsecutiveData3 IsoTpFrameType 2-2;
SG_MUL_VAL_ 607 UnknownData3 IsoTpFrameType 4-15;
SG_MUL_VAL_ 607 FirstData2 IsoTpFrameType 1-1;
SG_MUL_VAL_ 607 FlowPadding1 IsoTpFrameType 3-3;
SG_MUL_VAL_ 607 SingleData4 IsoTpFrameType 0-0;
SG_MUL_VAL_ 607 ConsecutiveData4 IsoTpFrameType 2-2;
SG_MUL_VAL_ 607 UnknownData4 IsoTpFrameType 4-15;
SG_MUL_VAL_ 607 FirstData3 IsoTpFrameType 1-1;
SG_MUL_VAL_ 607 FlowPadding2 IsoTpFrameType 3-3;
SG_MUL_VAL_ 607 SingleData5 IsoTpFrameType 0-0;
SG_MUL_VAL_ 607 ConsecutiveData5 IsoTpFrameType 2-2;
SG_MUL_VAL_ 607 UnknownData5 IsoTpFrameType 4-15;
SG_MUL_VAL_ 607 FirstData4 IsoTpFrameType 1-1;
SG_MUL_VAL_ 607 FlowPadding3 IsoTpFrameType 3-3;
SG_MUL_VAL_ 607 SingleData6 IsoTpFrameType 0-0;
SG_MUL_VAL_ 607 ConsecutiveData6 IsoTpFrameType 2-2;
SG_MUL_VAL_ 607 UnknownData6 IsoTpFrameType 4-15;
SG_MUL_VAL_ 607 FirstData5 IsoTpFrameType 1-1;
SG_MUL_VAL_ 607 FlowPadding4 IsoTpFrameType 3-3;
SG_MUL_VAL_ 607 SingleData7 IsoTpFrameType 0-0;
SG_MUL_VAL_ 607 ConsecutiveData7 IsoTpFrameType 2-2;
SG_MUL_VAL_ 607 UnknownData7 IsoTpFrameType 4-15;
SG_MUL_VAL_ 607 FirstData6 IsoTpFrameType 1-1;
SG_MUL_VAL_ 607 FlowPadding5 IsoTpFrameType 3-3;
SG_MUL_VAL_ 611 SingleFrameLength IsoTpFrameType 0-0;
SG_MUL_VAL_ 611 FirstFrameLength IsoTpFrameType 1-1;
SG_MUL_VAL_ 611 ConsecutiveSequence IsoTpFrameType 2-2;
SG_MUL_VAL_ 611 FlowStatus IsoTpFrameType 3-3;
SG_MUL_VAL_ 611 UnknownPciLow IsoTpFrameType 4-15;
SG_MUL_VAL_ 611 BlockSize IsoTpFrameType 3-3;
SG_MUL_VAL_ 611 SingleData1 IsoTpFrameType 0-0;
SG_MUL_VAL_ 611 ConsecutiveData1 IsoTpFrameType 2-2;
SG_MUL_VAL_ 611 UnknownData1 IsoTpFrameType 4-15;
SG_MUL_VAL_ 611 SeparationTimeRaw IsoTpFrameType 3-3;
SG_MUL_VAL_ 611 SingleData2 IsoTpFrameType 0-0;
SG_MUL_VAL_ 611 ConsecutiveData2 IsoTpFrameType 2-2;
SG_MUL_VAL_ 611 UnknownData2 IsoTpFrameType 4-15;
SG_MUL_VAL_ 611 FirstData1 IsoTpFrameType 1-1;
SG_MUL_VAL_ 611 SingleData3 IsoTpFrameType 0-0;
SG_MUL_VAL_ 611 ConsecutiveData3 IsoTpFrameType 2-2;
SG_MUL_VAL_ 611 UnknownData3 IsoTpFrameType 4-15;
SG_MUL_VAL_ 611 FirstData2 IsoTpFrameType 1-1;
SG_MUL_VAL_ 611 FlowPadding1 IsoTpFrameType 3-3;
SG_MUL_VAL_ 611 SingleData4 IsoTpFrameType 0-0;
SG_MUL_VAL_ 611 ConsecutiveData4 IsoTpFrameType 2-2;
SG_MUL_VAL_ 611 UnknownData4 IsoTpFrameType 4-15;
SG_MUL_VAL_ 611 FirstData3 IsoTpFrameType 1-1;
SG_MUL_VAL_ 611 FlowPadding2 IsoTpFrameType 3-3;
SG_MUL_VAL_ 611 SingleData5 IsoTpFrameType 0-0;
SG_MUL_VAL_ 611 ConsecutiveData5 IsoTpFrameType 2-2;
SG_MUL_VAL_ 611 UnknownData5 IsoTpFrameType 4-15;
SG_MUL_VAL_ 611 FirstData4 IsoTpFrameType 1-1;
SG_MUL_VAL_ 611 FlowPadding3 IsoTpFrameType 3-3;
SG_MUL_VAL_ 611 SingleData6 IsoTpFrameType 0-0;
SG_MUL_VAL_ 611 ConsecutiveData6 IsoTpFrameType 2-2;
SG_MUL_VAL_ 611 UnknownData6 IsoTpFrameType 4-15;
SG_MUL_VAL_ 611 FirstData5 IsoTpFrameType 1-1;
SG_MUL_VAL_ 611 FlowPadding4 IsoTpFrameType 3-3;
SG_MUL_VAL_ 611 SingleData7 IsoTpFrameType 0-0;
SG_MUL_VAL_ 611 ConsecutiveData7 IsoTpFrameType 2-2;
SG_MUL_VAL_ 611 UnknownData7 IsoTpFrameType 4-15;
SG_MUL_VAL_ 611 FirstData6 IsoTpFrameType 1-1;
SG_MUL_VAL_ 611 FlowPadding5 IsoTpFrameType 3-3;
SG_MUL_VAL_ 617 SingleFrameLength IsoTpFrameType 0-0;
SG_MUL_VAL_ 617 FirstFrameLength IsoTpFrameType 1-1;
SG_MUL_VAL_ 617 ConsecutiveSequence IsoTpFrameType 2-2;
SG_MUL_VAL_ 617 FlowStatus IsoTpFrameType 3-3;
SG_MUL_VAL_ 617 UnknownPciLow IsoTpFrameType 4-15;
SG_MUL_VAL_ 617 BlockSize IsoTpFrameType 3-3;
SG_MUL_VAL_ 617 SingleData1 IsoTpFrameType 0-0;
SG_MUL_VAL_ 617 ConsecutiveData1 IsoTpFrameType 2-2;
SG_MUL_VAL_ 617 UnknownData1 IsoTpFrameType 4-15;
SG_MUL_VAL_ 617 SeparationTimeRaw IsoTpFrameType 3-3;
SG_MUL_VAL_ 617 SingleData2 IsoTpFrameType 0-0;
SG_MUL_VAL_ 617 ConsecutiveData2 IsoTpFrameType 2-2;
SG_MUL_VAL_ 617 UnknownData2 IsoTpFrameType 4-15;
SG_MUL_VAL_ 617 FirstData1 IsoTpFrameType 1-1;
SG_MUL_VAL_ 617 SingleData3 IsoTpFrameType 0-0;
SG_MUL_VAL_ 617 ConsecutiveData3 IsoTpFrameType 2-2;
SG_MUL_VAL_ 617 UnknownData3 IsoTpFrameType 4-15;
SG_MUL_VAL_ 617 FirstData2 IsoTpFrameType 1-1;
SG_MUL_VAL_ 617 FlowPadding1 IsoTpFrameType 3-3;
SG_MUL_VAL_ 617 SingleData4 IsoTpFrameType 0-0;
SG_MUL_VAL_ 617 ConsecutiveData4 IsoTpFrameType 2-2;
SG_MUL_VAL_ 617 UnknownData4 IsoTpFrameType 4-15;
SG_MUL_VAL_ 617 FirstData3 IsoTpFrameType 1-1;
SG_MUL_VAL_ 617 FlowPadding2 IsoTpFrameType 3-3;
SG_MUL_VAL_ 617 SingleData5 IsoTpFrameType 0-0;
SG_MUL_VAL_ 617 ConsecutiveData5 IsoTpFrameType 2-2;
SG_MUL_VAL_ 617 UnknownData5 IsoTpFrameType 4-15;
SG_MUL_VAL_ 617 FirstData4 IsoTpFrameType 1-1;
SG_MUL_VAL_ 617 FlowPadding3 IsoTpFrameType 3-3;
SG_MUL_VAL_ 617 SingleData6 IsoTpFrameType 0-0;
SG_MUL_VAL_ 617 ConsecutiveData6 IsoTpFrameType 2-2;
SG_MUL_VAL_ 617 UnknownData6 IsoTpFrameType 4-15;
SG_MUL_VAL_ 617 FirstData5 IsoTpFrameType 1-1;
SG_MUL_VAL_ 617 FlowPadding4 IsoTpFrameType 3-3;
SG_MUL_VAL_ 617 SingleData7 IsoTpFrameType 0-0;
SG_MUL_VAL_ 617 ConsecutiveData7 IsoTpFrameType 2-2;
SG_MUL_VAL_ 617 UnknownData7 IsoTpFrameType 4-15;
SG_MUL_VAL_ 617 FirstData6 IsoTpFrameType 1-1;
SG_MUL_VAL_ 617 FlowPadding5 IsoTpFrameType 3-3;
SG_MUL_VAL_ 625 SingleFrameLength IsoTpFrameType 0-0;
SG_MUL_VAL_ 625 FirstFrameLength IsoTpFrameType 1-1;
SG_MUL_VAL_ 625 ConsecutiveSequence IsoTpFrameType 2-2;
SG_MUL_VAL_ 625 FlowStatus IsoTpFrameType 3-3;
SG_MUL_VAL_ 625 UnknownPciLow IsoTpFrameType 4-15;
SG_MUL_VAL_ 625 BlockSize IsoTpFrameType 3-3;
SG_MUL_VAL_ 625 SingleData1 IsoTpFrameType 0-0;
SG_MUL_VAL_ 625 ConsecutiveData1 IsoTpFrameType 2-2;
SG_MUL_VAL_ 625 UnknownData1 IsoTpFrameType 4-15;
SG_MUL_VAL_ 625 SeparationTimeRaw IsoTpFrameType 3-3;
SG_MUL_VAL_ 625 SingleData2 IsoTpFrameType 0-0;
SG_MUL_VAL_ 625 ConsecutiveData2 IsoTpFrameType 2-2;
SG_MUL_VAL_ 625 UnknownData2 IsoTpFrameType 4-15;
SG_MUL_VAL_ 625 FirstData1 IsoTpFrameType 1-1;
SG_MUL_VAL_ 625 SingleData3 IsoTpFrameType 0-0;
SG_MUL_VAL_ 625 ConsecutiveData3 IsoTpFrameType 2-2;
SG_MUL_VAL_ 625 UnknownData3 IsoTpFrameType 4-15;
SG_MUL_VAL_ 625 FirstData2 IsoTpFrameType 1-1;
SG_MUL_VAL_ 625 FlowPadding1 IsoTpFrameType 3-3;
SG_MUL_VAL_ 625 SingleData4 IsoTpFrameType 0-0;
SG_MUL_VAL_ 625 ConsecutiveData4 IsoTpFrameType 2-2;
SG_MUL_VAL_ 625 UnknownData4 IsoTpFrameType 4-15;
SG_MUL_VAL_ 625 FirstData3 IsoTpFrameType 1-1;
SG_MUL_VAL_ 625 FlowPadding2 IsoTpFrameType 3-3;
SG_MUL_VAL_ 625 SingleData5 IsoTpFrameType 0-0;
SG_MUL_VAL_ 625 ConsecutiveData5 IsoTpFrameType 2-2;
SG_MUL_VAL_ 625 UnknownData5 IsoTpFrameType 4-15;
SG_MUL_VAL_ 625 FirstData4 IsoTpFrameType 1-1;
SG_MUL_VAL_ 625 FlowPadding3 IsoTpFrameType 3-3;
SG_MUL_VAL_ 625 SingleData6 IsoTpFrameType 0-0;
SG_MUL_VAL_ 625 ConsecutiveData6 IsoTpFrameType 2-2;
SG_MUL_VAL_ 625 UnknownData6 IsoTpFrameType 4-15;
SG_MUL_VAL_ 625 FirstData5 IsoTpFrameType 1-1;
SG_MUL_VAL_ 625 FlowPadding4 IsoTpFrameType 3-3;
SG_MUL_VAL_ 625 SingleData7 IsoTpFrameType 0-0;
SG_MUL_VAL_ 625 ConsecutiveData7 IsoTpFrameType 2-2;
SG_MUL_VAL_ 625 UnknownData7 IsoTpFrameType 4-15;
SG_MUL_VAL_ 625 FirstData6 IsoTpFrameType 1-1;
SG_MUL_VAL_ 625 FlowPadding5 IsoTpFrameType 3-3;
SG_MUL_VAL_ 641 SingleFrameLength IsoTpFrameType 0-0;
SG_MUL_VAL_ 641 FirstFrameLength IsoTpFrameType 1-1;
SG_MUL_VAL_ 641 ConsecutiveSequence IsoTpFrameType 2-2;
SG_MUL_VAL_ 641 FlowStatus IsoTpFrameType 3-3;
SG_MUL_VAL_ 641 UnknownPciLow IsoTpFrameType 4-15;
SG_MUL_VAL_ 641 BlockSize IsoTpFrameType 3-3;
SG_MUL_VAL_ 641 SingleData1 IsoTpFrameType 0-0;
SG_MUL_VAL_ 641 ConsecutiveData1 IsoTpFrameType 2-2;
SG_MUL_VAL_ 641 UnknownData1 IsoTpFrameType 4-15;
SG_MUL_VAL_ 641 SeparationTimeRaw IsoTpFrameType 3-3;
SG_MUL_VAL_ 641 SingleData2 IsoTpFrameType 0-0;
SG_MUL_VAL_ 641 ConsecutiveData2 IsoTpFrameType 2-2;
SG_MUL_VAL_ 641 UnknownData2 IsoTpFrameType 4-15;
SG_MUL_VAL_ 641 FirstData1 IsoTpFrameType 1-1;
SG_MUL_VAL_ 641 SingleData3 IsoTpFrameType 0-0;
SG_MUL_VAL_ 641 ConsecutiveData3 IsoTpFrameType 2-2;
SG_MUL_VAL_ 641 UnknownData3 IsoTpFrameType 4-15;
SG_MUL_VAL_ 641 FirstData2 IsoTpFrameType 1-1;
SG_MUL_VAL_ 641 FlowPadding1 IsoTpFrameType 3-3;
SG_MUL_VAL_ 641 SingleData4 IsoTpFrameType 0-0;
SG_MUL_VAL_ 641 ConsecutiveData4 IsoTpFrameType 2-2;
SG_MUL_VAL_ 641 UnknownData4 IsoTpFrameType 4-15;
SG_MUL_VAL_ 641 FirstData3 IsoTpFrameType 1-1;
SG_MUL_VAL_ 641 FlowPadding2 IsoTpFrameType 3-3;
SG_MUL_VAL_ 641 SingleData5 IsoTpFrameType 0-0;
SG_MUL_VAL_ 641 ConsecutiveData5 IsoTpFrameType 2-2;
SG_MUL_VAL_ 641 UnknownData5 IsoTpFrameType 4-15;
SG_MUL_VAL_ 641 FirstData4 IsoTpFrameType 1-1;
SG_MUL_VAL_ 641 FlowPadding3 IsoTpFrameType 3-3;
SG_MUL_VAL_ 641 SingleData6 IsoTpFrameType 0-0;
SG_MUL_VAL_ 641 ConsecutiveData6 IsoTpFrameType 2-2;
SG_MUL_VAL_ 641 UnknownData6 IsoTpFrameType 4-15;
SG_MUL_VAL_ 641 FirstData5 IsoTpFrameType 1-1;
SG_MUL_VAL_ 641 FlowPadding4 IsoTpFrameType 3-3;
SG_MUL_VAL_ 641 SingleData7 IsoTpFrameType 0-0;
SG_MUL_VAL_ 641 ConsecutiveData7 IsoTpFrameType 2-2;
SG_MUL_VAL_ 641 UnknownData7 IsoTpFrameType 4-15;
SG_MUL_VAL_ 641 FirstData6 IsoTpFrameType 1-1;
SG_MUL_VAL_ 641 FlowPadding5 IsoTpFrameType 3-3;
SG_MUL_VAL_ 660 SingleFrameLength IsoTpFrameType 0-0;
SG_MUL_VAL_ 660 FirstFrameLength IsoTpFrameType 1-1;
SG_MUL_VAL_ 660 ConsecutiveSequence IsoTpFrameType 2-2;
SG_MUL_VAL_ 660 FlowStatus IsoTpFrameType 3-3;
SG_MUL_VAL_ 660 UnknownPciLow IsoTpFrameType 4-15;
SG_MUL_VAL_ 660 BlockSize IsoTpFrameType 3-3;
SG_MUL_VAL_ 660 SingleData1 IsoTpFrameType 0-0;
SG_MUL_VAL_ 660 ConsecutiveData1 IsoTpFrameType 2-2;
SG_MUL_VAL_ 660 UnknownData1 IsoTpFrameType 4-15;
SG_MUL_VAL_ 660 SeparationTimeRaw IsoTpFrameType 3-3;
SG_MUL_VAL_ 660 SingleData2 IsoTpFrameType 0-0;
SG_MUL_VAL_ 660 ConsecutiveData2 IsoTpFrameType 2-2;
SG_MUL_VAL_ 660 UnknownData2 IsoTpFrameType 4-15;
SG_MUL_VAL_ 660 FirstData1 IsoTpFrameType 1-1;
SG_MUL_VAL_ 660 SingleData3 IsoTpFrameType 0-0;
SG_MUL_VAL_ 660 ConsecutiveData3 IsoTpFrameType 2-2;
SG_MUL_VAL_ 660 UnknownData3 IsoTpFrameType 4-15;
SG_MUL_VAL_ 660 FirstData2 IsoTpFrameType 1-1;
SG_MUL_VAL_ 660 FlowPadding1 IsoTpFrameType 3-3;
SG_MUL_VAL_ 660 SingleData4 IsoTpFrameType 0-0;
SG_MUL_VAL_ 660 ConsecutiveData4 IsoTpFrameType 2-2;
SG_MUL_VAL_ 660 UnknownData4 IsoTpFrameType 4-15;
SG_MUL_VAL_ 660 FirstData3 IsoTpFrameType 1-1;
SG_MUL_VAL_ 660 FlowPadding2 IsoTpFrameType 3-3;
SG_MUL_VAL_ 660 SingleData5 IsoTpFrameType 0-0;
SG_MUL_VAL_ 660 ConsecutiveData5 IsoTpFrameType 2-2;
SG_MUL_VAL_ 660 UnknownData5 IsoTpFrameType 4-15;
SG_MUL_VAL_ 660 FirstData4 IsoTpFrameType 1-1;
SG_MUL_VAL_ 660 FlowPadding3 IsoTpFrameType 3-3;
SG_MUL_VAL_ 660 SingleData6 IsoTpFrameType 0-0;
SG_MUL_VAL_ 660 ConsecutiveData6 IsoTpFrameType 2-2;
SG_MUL_VAL_ 660 UnknownData6 IsoTpFrameType 4-15;
SG_MUL_VAL_ 660 FirstData5 IsoTpFrameType 1-1;
SG_MUL_VAL_ 660 FlowPadding4 IsoTpFrameType 3-3;
SG_MUL_VAL_ 660 SingleData7 IsoTpFrameType 0-0;
SG_MUL_VAL_ 660 ConsecutiveData7 IsoTpFrameType 2-2;
SG_MUL_VAL_ 660 UnknownData7 IsoTpFrameType 4-15;
SG_MUL_VAL_ 660 FirstData6 IsoTpFrameType 1-1;
SG_MUL_VAL_ 660 FlowPadding5 IsoTpFrameType 3-3;
SG_MUL_VAL_ 671 SingleFrameLength IsoTpFrameType 0-0;
SG_MUL_VAL_ 671 FirstFrameLength IsoTpFrameType 1-1;
SG_MUL_VAL_ 671 ConsecutiveSequence IsoTpFrameType 2-2;
SG_MUL_VAL_ 671 FlowStatus IsoTpFrameType 3-3;
SG_MUL_VAL_ 671 UnknownPciLow IsoTpFrameType 4-15;
SG_MUL_VAL_ 671 BlockSize IsoTpFrameType 3-3;
SG_MUL_VAL_ 671 SingleData1 IsoTpFrameType 0-0;
SG_MUL_VAL_ 671 ConsecutiveData1 IsoTpFrameType 2-2;
SG_MUL_VAL_ 671 UnknownData1 IsoTpFrameType 4-15;
SG_MUL_VAL_ 671 SeparationTimeRaw IsoTpFrameType 3-3;
SG_MUL_VAL_ 671 SingleData2 IsoTpFrameType 0-0;
SG_MUL_VAL_ 671 ConsecutiveData2 IsoTpFrameType 2-2;
SG_MUL_VAL_ 671 UnknownData2 IsoTpFrameType 4-15;
SG_MUL_VAL_ 671 FirstData1 IsoTpFrameType 1-1;
SG_MUL_VAL_ 671 SingleData3 IsoTpFrameType 0-0;
SG_MUL_VAL_ 671 ConsecutiveData3 IsoTpFrameType 2-2;
SG_MUL_VAL_ 671 UnknownData3 IsoTpFrameType 4-15;
SG_MUL_VAL_ 671 FirstData2 IsoTpFrameType 1-1;
SG_MUL_VAL_ 671 FlowPadding1 IsoTpFrameType 3-3;
SG_MUL_VAL_ 671 SingleData4 IsoTpFrameType 0-0;
SG_MUL_VAL_ 671 ConsecutiveData4 IsoTpFrameType 2-2;
SG_MUL_VAL_ 671 UnknownData4 IsoTpFrameType 4-15;
SG_MUL_VAL_ 671 FirstData3 IsoTpFrameType 1-1;
SG_MUL_VAL_ 671 FlowPadding2 IsoTpFrameType 3-3;
SG_MUL_VAL_ 671 SingleData5 IsoTpFrameType 0-0;
SG_MUL_VAL_ 671 ConsecutiveData5 IsoTpFrameType 2-2;
SG_MUL_VAL_ 671 UnknownData5 IsoTpFrameType 4-15;
SG_MUL_VAL_ 671 FirstData4 IsoTpFrameType 1-1;
SG_MUL_VAL_ 671 FlowPadding3 IsoTpFrameType 3-3;
SG_MUL_VAL_ 671 SingleData6 IsoTpFrameType 0-0;
SG_MUL_VAL_ 671 ConsecutiveData6 IsoTpFrameType 2-2;
SG_MUL_VAL_ 671 UnknownData6 IsoTpFrameType 4-15;
SG_MUL_VAL_ 671 FirstData5 IsoTpFrameType 1-1;
SG_MUL_VAL_ 671 FlowPadding4 IsoTpFrameType 3-3;
SG_MUL_VAL_ 671 SingleData7 IsoTpFrameType 0-0;
SG_MUL_VAL_ 671 ConsecutiveData7 IsoTpFrameType 2-2;
SG_MUL_VAL_ 671 UnknownData7 IsoTpFrameType 4-15;
SG_MUL_VAL_ 671 FirstData6 IsoTpFrameType 1-1;
SG_MUL_VAL_ 671 FlowPadding5 IsoTpFrameType 3-3;
SG_MUL_VAL_ 674 SingleFrameLength IsoTpFrameType 0-0;
SG_MUL_VAL_ 674 FirstFrameLength IsoTpFrameType 1-1;
SG_MUL_VAL_ 674 ConsecutiveSequence IsoTpFrameType 2-2;
SG_MUL_VAL_ 674 FlowStatus IsoTpFrameType 3-3;
SG_MUL_VAL_ 674 UnknownPciLow IsoTpFrameType 4-15;
SG_MUL_VAL_ 674 BlockSize IsoTpFrameType 3-3;
SG_MUL_VAL_ 674 SingleData1 IsoTpFrameType 0-0;
SG_MUL_VAL_ 674 ConsecutiveData1 IsoTpFrameType 2-2;
SG_MUL_VAL_ 674 UnknownData1 IsoTpFrameType 4-15;
SG_MUL_VAL_ 674 SeparationTimeRaw IsoTpFrameType 3-3;
SG_MUL_VAL_ 674 SingleData2 IsoTpFrameType 0-0;
SG_MUL_VAL_ 674 ConsecutiveData2 IsoTpFrameType 2-2;
SG_MUL_VAL_ 674 UnknownData2 IsoTpFrameType 4-15;
SG_MUL_VAL_ 674 FirstData1 IsoTpFrameType 1-1;
SG_MUL_VAL_ 674 SingleData3 IsoTpFrameType 0-0;
SG_MUL_VAL_ 674 ConsecutiveData3 IsoTpFrameType 2-2;
SG_MUL_VAL_ 674 UnknownData3 IsoTpFrameType 4-15;
SG_MUL_VAL_ 674 FirstData2 IsoTpFrameType 1-1;
SG_MUL_VAL_ 674 FlowPadding1 IsoTpFrameType 3-3;
SG_MUL_VAL_ 674 SingleData4 IsoTpFrameType 0-0;
SG_MUL_VAL_ 674 ConsecutiveData4 IsoTpFrameType 2-2;
SG_MUL_VAL_ 674 UnknownData4 IsoTpFrameType 4-15;
SG_MUL_VAL_ 674 FirstData3 IsoTpFrameType 1-1;
SG_MUL_VAL_ 674 FlowPadding2 IsoTpFrameType 3-3;
SG_MUL_VAL_ 674 SingleData5 IsoTpFrameType 0-0;
SG_MUL_VAL_ 674 ConsecutiveData5 IsoTpFrameType 2-2;
SG_MUL_VAL_ 674 UnknownData5 IsoTpFrameType 4-15;
SG_MUL_VAL_ 674 FirstData4 IsoTpFrameType 1-1;
SG_MUL_VAL_ 674 FlowPadding3 IsoTpFrameType 3-3;
SG_MUL_VAL_ 674 SingleData6 IsoTpFrameType 0-0;
SG_MUL_VAL_ 674 ConsecutiveData6 IsoTpFrameType 2-2;
SG_MUL_VAL_ 674 UnknownData6 IsoTpFrameType 4-15;
SG_MUL_VAL_ 674 FirstData5 IsoTpFrameType 1-1;
SG_MUL_VAL_ 674 FlowPadding4 IsoTpFrameType 3-3;
SG_MUL_VAL_ 674 SingleData7 IsoTpFrameType 0-0;
SG_MUL_VAL_ 674 ConsecutiveData7 IsoTpFrameType 2-2;
SG_MUL_VAL_ 674 UnknownData7 IsoTpFrameType 4-15;
SG_MUL_VAL_ 674 FirstData6 IsoTpFrameType 1-1;
SG_MUL_VAL_ 674 FlowPadding5 IsoTpFrameType 3-3;
